VERSION "HNNBNNNYNNNNNNNNNNNNNNNNNNNNNNNNNNNNNNNNNN/4/%%%/4/'%**4NNN///"

NS_ :

BS_:

BU_: Allrad_Haldex AreaView_MQB BAP_Tester Bremse_ABS_MK100 Bremse_ESP_EPB_EBC460Vi Bremse_ESP_EPB_MK100 Bremse_ESP_MK100 Daempfer Gateway_MQB Lenkhilfe_EPS PDC PDC_PLA

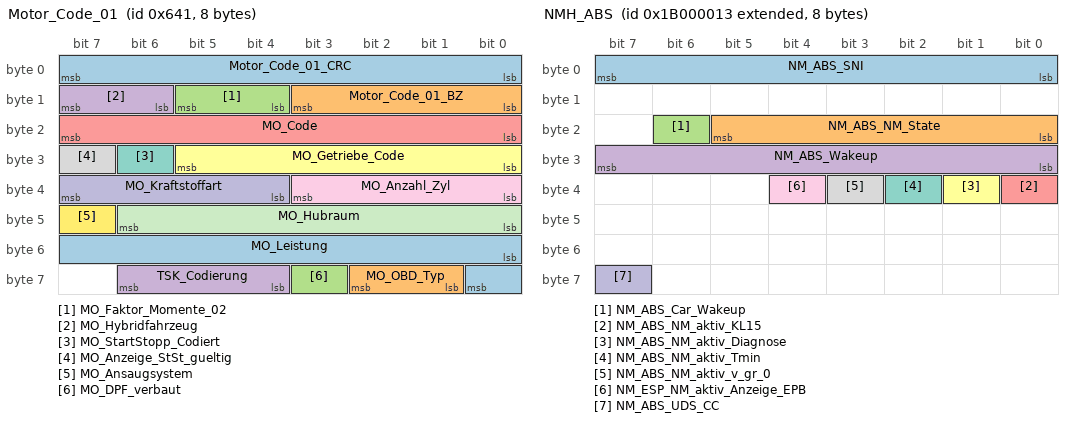
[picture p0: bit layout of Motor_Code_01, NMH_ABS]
BO_ 1601 Motor_Code_01: 8 Gateway_MQB
 SG_ Motor_Code_01_CRC : 0|8@1+ (1,0) [0|255] ""  Bremse_ABS_MK100,Bremse_ESP_EPB_EBC460Vi,Bremse_ESP_EPB_MK100,Bremse_ESP_MK100,Lenkhilfe_EPS
 SG_ Motor_Code_01_BZ : 8|4@1+ (1,0) [0|15] ""  Bremse_ABS_MK100,Bremse_ESP_EPB_EBC460Vi,Bremse_ESP_EPB_MK100,Bremse_ESP_MK100,Lenkhilfe_EPS
 SG_ MO_Faktor_Momente_02 : 12|2@1+ (1,0) [1|3] "Unit_NewtoMeter"  Allrad_Haldex,Bremse_ABS_MK100,Bremse_ESP_EPB_EBC460Vi,Bremse_ESP_EPB_MK100,Bremse_ESP_MK100,Lenkhilfe_EPS
 SG_ MO_Hybridfahrzeug : 14|2@1+ (1.0,0.0) [0.0|3] ""  Bremse_ESP_EPB_EBC460Vi,Bremse_ESP_EPB_MK100,Lenkhilfe_EPS
 SG_ MO_Code : 16|8@1+ (1,0) [0|255] ""  Vector__XXX
 SG_ MO_Getriebe_Code : 24|6@1+ (1.0,0.0) [0.0|63] ""  Bremse_ABS_MK100,Bremse_ESP_EPB_EBC460Vi,Bremse_ESP_EPB_MK100,Bremse_ESP_MK100
 SG_ MO_StartStopp_Codiert : 30|1@1+ (1.0,0.0) [0.0|1] ""  Lenkhilfe_EPS
 SG_ MO_Anzeige_StSt_gueltig : 31|1@1+ (1.0,0.0) [0.0|1] ""  Vector__XXX
 SG_ MO_Anzahl_Zyl : 32|4@1+ (1.0,0.0) [0.0|15] ""  Bremse_ESP_EPB_EBC460Vi,Bremse_ESP_EPB_MK100,Bremse_ESP_MK100
 SG_ MO_Kraftstoffart : 36|4@1+ (1.0,0.0) [0.0|15] ""  Allrad_Haldex,Bremse_ESP_EPB_EBC460Vi,Bremse_ESP_EPB_MK100,Bremse_ESP_MK100
 SG_ MO_Hubraum : 40|7@1+ (0.1,0) [0.0|12.7] "Unit_Liter"  Bremse_ESP_EPB_EBC460Vi,Bremse_ESP_EPB_MK100
 SG_ MO_Ansaugsystem : 47|1@1+ (1.0,0.0) [0.0|1] ""  Bremse_ESP_EPB_EBC460Vi,Bremse_ESP_EPB_MK100,Bremse_ESP_MK100
 SG_ MO_Leistung : 48|9@1+ (1,0) [0|511] "Unit_KiloWatt"  Allrad_Haldex,Bremse_ESP_EPB_EBC460Vi,Bremse_ESP_EPB_MK100
 SG_ MO_OBD_Typ : 57|2@1+ (1.0,0.0) [0.0|3] ""  Bremse_ESP_EPB_MK100
 SG_ MO_DPF_verbaut : 59|1@1+ (1.0,0.0) [0.0|1] ""  Vector__XXX
 SG_ TSK_Codierung : 60|3@1+ (1.0,0.0) [0.0|7] ""  Bremse_ESP_EPB_EBC460Vi,Bremse_ESP_EPB_MK100,Bremse_ESP_MK100

BO_ 2600468499 NMH_ABS: 8 Bremse_ABS_MK100
 SG_ NM_ABS_SNI : 0|8@1+ (1.0,0.0) [0.0|255] ""  Vector__XXX
 SG_ NM_ABS_NM_State : 16|6@1+ (1.0,0.0) [0.0|63] ""  AreaView_MQB,Bremse_ABS_MK100,Bremse_ESP_EPB_EBC460Vi,Bremse_ESP_EPB_MK100,Bremse_ESP_MK100,Lenkhilfe_EPS
 SG_ NM_ABS_Car_Wakeup : 22|1@1+ (1.0,0.0) [0.0|1] ""  Gateway_MQB
 SG_ NM_ABS_Wakeup : 24|8@1+ (1.0,0.0) [0.0|255] ""  Vector__XXX
 SG_ NM_ABS_NM_aktiv_KL15 : 32|1@1+ (1.0,0.0) [0.0|1] ""  Vector__XXX
 SG_ NM_ABS_NM_aktiv_Diagnose : 33|1@1+ (1.0,0.0) [0.0|1] ""  Vector__XXX
 SG_ NM_ABS_NM_aktiv_Tmin : 34|1@1+ (1.0,0.0) [0.0|1] ""  Vector__XXX
 SG_ NM_ABS_NM_aktiv_v_gr_0 : 35|1@1+ (1.0,0.0) [0.0|1] ""  Vector__XXX
 SG_ NM_ESP_NM_aktiv_Anzeige_EPB : 36|1@1+ (1.0,0.0) [0.0|1] ""  Vector__XXX
 SG_ NM_ABS_UDS_CC : 63|1@1+ (1.0,0.0) [0.0|1] ""  Vector__XXX

BO_ 2600468496 NMH_Gateway: 8 Gateway_MQB
 SG_ NM_Gateway_SNI : 0|8@1+ (1.0,0.0) [0.0|255] ""  Vector__XXX
 SG_ NM_Gateway_NM_State : 16|6@1+ (1.0,0.0) [0.0|63] ""  AreaView_MQB,Bremse_ABS_MK100,Bremse_ESP_EPB_EBC460Vi,Bremse_ESP_EPB_MK100,Bremse_ESP_MK100,Lenkhilfe_EPS
 SG_ NM_Gateway_Car_Wakeup : 22|1@1+ (1.0,0.0) [0.0|1] ""  Vector__XXX
 SG_ NM_Gateway_Wakeup : 24|8@1+ (1.0,0.0) [0.0|255] ""  Vector__XXX
 SG_ NM_Gateway_NM_aktiv_KL15 : 32|1@1+ (1.0,0.0) [0.0|1] ""  Vector__XXX
 SG_ NM_Gateway_NM_aktiv_Diagnose : 33|1@1+ (1.0,0.0) [0.0|1] ""  Vector__XXX
 SG_ NM_Gateway_NM_aktiv_Tmin : 34|1@1+ (1.0,0.0) [0.0|1] ""  Vector__XXX
 SG_ NM_Gateway_ACAN_Aktivitaet : 35|1@1+ (1.0,0.0) [0.0|1] ""  Vector__XXX
 SG_ NM_Gateway_FCAN_Aktivitaet : 36|1@1+ (1.0,0.0) [0.0|1] ""  Vector__XXX
 SG_ NM_Gateway_KCAN_Aktivitaet : 37|1@1+ (1.0,0.0) [0.0|1] ""  Vector__XXX
 SG_ NM_Gateway_ICAN_Aktivitaet : 38|1@1+ (1.0,0.0) [0.0|1] ""  Vector__XXX
 SG_ NM_Gateway_DiagCAN_Aktivitaet : 39|1@1+ (1.0,0.0) [0.0|1] ""  Vector__XXX
 SG_ NM_Gateway_ECAN_Aktivitaet : 40|1@1+ (1.0,0.0) [0.0|1] ""  Vector__XXX
 SG_ NM_Gateway_EnergieLIN_Aktivitaet : 41|1@1+ (1.0,0.0) [0.0|1] ""  Vector__XXX
 SG_ NM_Gateway_Bedien_LIN_Aktivitaet : 42|1@1+ (1.0,0.0) [0.0|1] ""  Vector__XXX
 SG_ NM_Gateway_EM_Aktivitaet : 43|1@1+ (1.0,0.0) [0.0|1] ""  Vector__XXX
 SG_ NM_Gateway_KS_Aktivitaet : 44|1@1+ (1.0,0.0) [0.0|1] ""  Vector__XXX
 SG_ NM_Gateway_HVEM_aktiv : 45|1@1+ (1.0,0.0) [0.0|1] ""  Vector__XXX
 SG_ NM_Gateway_NL_EM : 48|1@1+ (1.0,0.0) [0.0|1] ""  Vector__XXX
 SG_ NM_Gateway_NL_Shutdown : 49|1@1+ (1.0,0.0) [0.0|1] ""  Vector__XXX
 SG_ NM_Gateway_NL_Spg_Messung : 50|1@1+ (1.0,0.0) [0.0|1] ""  Vector__XXX
 SG_ NM_Gateway_NL_Wakeup_Monitor : 51|1@1+ (1.0,0.0) [0.0|1] ""  Vector__XXX
 SG_ NM_Gateway_UDS_CC : 63|1@1+ (1.0,0.0) [0.0|1] ""  Vector__XXX

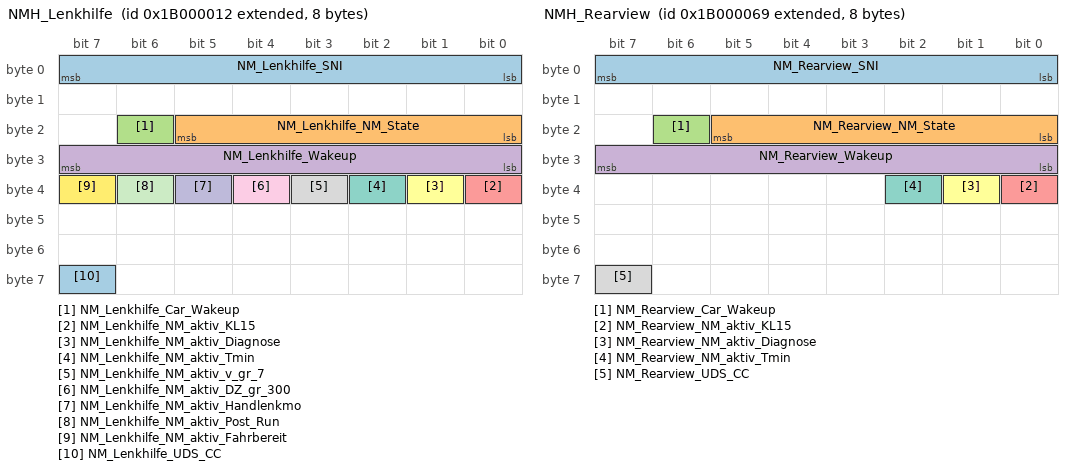
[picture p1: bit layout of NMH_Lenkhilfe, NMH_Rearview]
BO_ 2600468498 NMH_Lenkhilfe: 8 Lenkhilfe_EPS
 SG_ NM_Lenkhilfe_SNI : 0|8@1+ (1.0,0.0) [0.0|255] ""  Vector__XXX
 SG_ NM_Lenkhilfe_NM_State : 16|6@1+ (1.0,0.0) [0.0|63] ""  AreaView_MQB,Bremse_ABS_MK100,Bremse_ESP_EPB_EBC460Vi,Bremse_ESP_EPB_MK100,Bremse_ESP_MK100,Lenkhilfe_EPS
 SG_ NM_Lenkhilfe_Car_Wakeup : 22|1@1+ (1.0,0.0) [0.0|1] ""  Gateway_MQB
 SG_ NM_Lenkhilfe_Wakeup : 24|8@1+ (1.0,0.0) [0.0|255] ""  Vector__XXX
 SG_ NM_Lenkhilfe_NM_aktiv_KL15 : 32|1@1+ (1.0,0.0) [0.0|1] ""  Vector__XXX
 SG_ NM_Lenkhilfe_NM_aktiv_Diagnose : 33|1@1+ (1.0,0.0) [0.0|1] ""  Vector__XXX
 SG_ NM_Lenkhilfe_NM_aktiv_Tmin : 34|1@1+ (1.0,0.0) [0.0|1] ""  Vector__XXX
 SG_ NM_Lenkhilfe_NM_aktiv_v_gr_7 : 35|1@1+ (1.0,0.0) [0.0|1] ""  Vector__XXX
 SG_ NM_Lenkhilfe_NM_aktiv_DZ_gr_300 : 36|1@1+ (1.0,0.0) [0.0|1] ""  Vector__XXX
 SG_ NM_Lenkhilfe_NM_aktiv_Handlenkmo : 37|1@1+ (1.0,0.0) [0.0|1] ""  Vector__XXX
 SG_ NM_Lenkhilfe_NM_aktiv_Post_Run : 38|1@1+ (1.0,0.0) [0.0|1] ""  Vector__XXX
 SG_ NM_Lenkhilfe_NM_aktiv_Fahrbereit : 39|1@1+ (1.0,0.0) [0.0|1] ""  Vector__XXX
 SG_ NM_Lenkhilfe_UDS_CC : 63|1@1+ (1.0,0.0) [0.0|1] ""  Vector__XXX

BO_ 2600468585 NMH_Rearview: 8 AreaView_MQB
 SG_ NM_Rearview_SNI : 0|8@1+ (1.0,0.0) [0.0|255] ""  Vector__XXX
 SG_ NM_Rearview_NM_State : 16|6@1+ (1.0,0.0) [0.0|63] ""  AreaView_MQB,Bremse_ABS_MK100,Bremse_ESP_EPB_EBC460Vi,Bremse_ESP_EPB_MK100,Bremse_ESP_MK100,Lenkhilfe_EPS
 SG_ NM_Rearview_Car_Wakeup : 22|1@1+ (1.0,0.0) [0.0|1] ""  Vector__XXX
 SG_ NM_Rearview_Wakeup : 24|8@1+ (1.0,0.0) [0.0|255] ""  Vector__XXX
 SG_ NM_Rearview_NM_aktiv_KL15 : 32|1@1+ (1.0,0.0) [0.0|1] ""  Vector__XXX
 SG_ NM_Rearview_NM_aktiv_Diagnose : 33|1@1+ (1.0,0.0) [0.0|1] ""  Vector__XXX
 SG_ NM_Rearview_NM_aktiv_Tmin : 34|1@1+ (1.0,0.0) [0.0|1] ""  Vector__XXX
 SG_ NM_Rearview_UDS_CC : 63|1@1+ (1.0,0.0) [0.0|1] ""  Vector__XXX

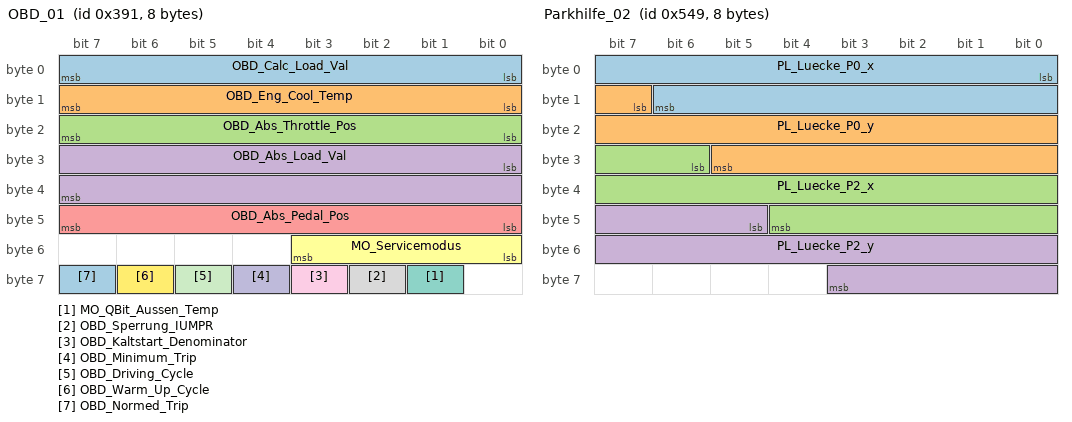
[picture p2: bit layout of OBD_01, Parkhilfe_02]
BO_ 913 OBD_01: 8 Gateway_MQB
 SG_ OBD_Calc_Load_Val : 0|8@1+ (0.39215686274509803,0) [0E-17|99.99999999999999765] "Unit_PerCent"  Bremse_ESP_EPB_MK100
 SG_ OBD_Eng_Cool_Temp : 8|8@1+ (1,-40) [-40|215] "Unit_DegreCelsi"  Bremse_ESP_EPB_MK100
 SG_ OBD_Abs_Throttle_Pos : 16|8@1+ (0.39215686274509803,0) [0E-17|99.99999999999999765] "Unit_PerCent"  Bremse_ESP_EPB_MK100
 SG_ OBD_Abs_Load_Val : 24|16@1+ (0.39215686274509803,0) [0E-17|25699.99999999999939605] "Unit_PerCent"  Bremse_ESP_EPB_MK100
 SG_ OBD_Abs_Pedal_Pos : 40|8@1+ (0.39215686274509803,0) [0E-17|99.99999999999999765] "Unit_PerCent"  Bremse_ESP_EPB_MK100
 SG_ MO_Servicemodus : 48|4@1+ (1.0,0.0) [0.0|15] ""  Vector__XXX
 SG_ MO_QBit_Aussen_Temp : 57|1@1+ (1.0,0.0) [0.0|1] ""  Vector__XXX
 SG_ OBD_Sperrung_IUMPR : 58|1@1+ (1.0,0.0) [0.0|1] ""  Bremse_ESP_EPB_MK100
 SG_ OBD_Kaltstart_Denominator : 59|1@1+ (1.0,0.0) [0.0|1] ""  Bremse_ESP_EPB_MK100
 SG_ OBD_Minimum_Trip : 60|1@1+ (1.0,0.0) [0.0|1] ""  Bremse_ESP_EPB_MK100
 SG_ OBD_Driving_Cycle : 61|1@1+ (1.0,0.0) [0.0|1] ""  Bremse_ESP_EPB_MK100
 SG_ OBD_Warm_Up_Cycle : 62|1@1+ (1.0,0.0) [0.0|1] ""  Bremse_ESP_EPB_MK100
 SG_ OBD_Normed_Trip : 63|1@1+ (1.0,0.0) [0.0|1] ""  Bremse_ESP_EPB_MK100

BO_ 2549875219 OBDC_ABS_Req: 8 Vector__XXX
 SG_ OBDC_ABS_Req_Data : 0|64@1+ (1.0,0.0) [0.0|18446744073709551615] ""  Bremse_ABS_MK100,Bremse_ESP_EPB_EBC460Vi,Bremse_ESP_EPB_MK100,Bremse_ESP_MK100

BO_ 2550006291 OBDC_ABS_Resp: 8 Bremse_ABS_MK100
 SG_ OBDC_ABS_Resp_Data : 0|64@1+ (1.0,0.0) [0.0|18446744073709551615] ""  Vector__XXX

BO_ 2549875215 OBDC_Allrad_Req: 8 Vector__XXX
 SG_ OBDC_Allrad_Req_Data : 0|64@1+ (1.0,0.0) [0.0|18446744073709551615] ""  Allrad_Haldex

BO_ 2550006287 OBDC_Allrad_Resp: 8 Allrad_Haldex
 SG_ OBDC_Allrad_Resp_Data : 0|64@1+ (1.0,0.0) [0.0|18446744073709551615] ""  Vector__XXX

BO_ 2549875314 OBDC_Daempfer_Req: 8 Vector__XXX
 SG_ OBDC_Daempfer_Req_Data : 0|64@1+ (1.0,0.0) [0.0|18446744073709551615] ""  Daempfer

BO_ 2550006386 OBDC_Daempfer_Resp: 8 Daempfer
 SG_ OBDC_Daempfer_Resp_Data : 0|64@1+ (1.0,0.0) [0.0|18446744073709551615] ""  Vector__XXX

BO_ 2549875210 OBDC_EPH_Req: 8 Vector__XXX
 SG_ OBDC_EPH_Req_Data : 0|64@1+ (1.0,0.0) [0.0|18446744073709551615] ""  PDC,PDC_PLA

BO_ 2550006282 OBDC_EPH_Resp: 8 PDC
 SG_ OBDC_EPH_Resp_Data : 0|64@1+ (1.0,0.0) [0.0|18446744073709551615] ""  Vector__XXX

BO_ 2549875218 OBDC_Lenkhilfe_Req: 8 Vector__XXX
 SG_ OBDC_Lenkhilfe_Req_Data : 0|64@1+ (1.0,0.0) [0.0|18446744073709551615] ""  Lenkhilfe_EPS

BO_ 2550006290 OBDC_Lenkhilfe_Resp: 8 Lenkhilfe_EPS
 SG_ OBDC_Lenkhilfe_Resp_Data : 0|64@1+ (1.0,0.0) [0.0|18446744073709551615] ""  Vector__XXX

BO_ 2549875305 OBDC_Rearview_Req: 8 Vector__XXX
 SG_ OBDC_Rearview_Req_Data : 0|64@1+ (1.0,0.0) [0.0|18446744073709551615] ""  AreaView_MQB

BO_ 2550006377 OBDC_Rearview_Resp: 8 AreaView_MQB
 SG_ OBDC_Rearview_Resp_Data : 0|64@1+ (1.0,0.0) [0.0|18446744073709551615] ""  Vector__XXX

BO_ 1175 Parkhilfe_01: 8 PDC
 SG_ PH_Visualisierung : 0|3@1+ (1.0,0.0) [0.0|7] ""  AreaView_MQB,Gateway_MQB
 SG_ PDC_Tonausgabe_Front : 4|4@1+ (1.0,0.0) [0.0|15] ""  Gateway_MQB
 SG_ PDC_Tonausgabe_Heck : 8|4@1+ (1.0,0.0) [0.0|15] ""  Gateway_MQB
 SG_ PH_nachtr_Stopp_Anf : 12|1@1+ (1.0,0.0) [0.0|1] ""  Gateway_MQB
 SG_ PH_Abschaltursache : 13|3@1+ (1.0,0.0) [0.0|7] ""  Gateway_MQB
 SG_ PH_Opt_Anzeige_V_ein : 16|1@1+ (1.0,0.0) [0.0|1] ""  Gateway_MQB
 SG_ PH_Opt_Anzeige_H_ein : 17|1@1+ (1.0,0.0) [0.0|1] ""  Gateway_MQB
 SG_ PH_Opt_Anz_V_Hindernis : 18|1@1+ (1.0,0.0) [0.0|1] ""  Gateway_MQB
 SG_ PH_Opt_Anz_H_Hindernis : 19|1@1+ (1.0,0.0) [0.0|1] ""  Gateway_MQB
 SG_ PH_Tongeber_V_aktiv : 20|1@1+ (1.0,0.0) [0.0|1] ""  Gateway_MQB
 SG_ PH_Tongeber_H_aktiv : 21|1@1+ (1.0,0.0) [0.0|1] ""  Gateway_MQB
 SG_ PH_Tongeber_mute : 22|1@1+ (1.0,0.0) [0.0|1] ""  Gateway_MQB
 SG_ PH_Anf_Audioabsenkung : 23|1@1+ (1.0,0.0) [0.0|1] ""  Gateway_MQB
 SG_ PH_Tongeber_H_verfuegbar : 24|1@1+ (1.0,0.0) [0.0|1] ""  Gateway_MQB
 SG_ PLA_Anf_Aufschaltung_RVC : 25|1@1+ (1.0,0.0) [0.0|1] ""  AreaView_MQB,Gateway_MQB
 SG_ PH_Taster : 28|2@1+ (1.0,0.0) [0.0|3] ""  AreaView_MQB,Gateway_MQB
 SG_ PH_Anf_Verdeck : 30|2@1+ (1.0,0.0) [0.0|3] ""  Gateway_MQB
 SG_ PH_Frequenz_hinten : 32|4@1+ (1,0) [0|15] ""  Gateway_MQB
 SG_ PH_Lautstaerke_hinten : 36|4@1+ (1,0) [0|15] ""  Gateway_MQB
 SG_ PH_Frequenz_vorn : 40|4@1+ (1,0) [0|15] ""  Gateway_MQB
 SG_ PH_Lautstaerke_vorn : 44|4@1+ (1,0) [0|15] ""  Gateway_MQB
 SG_ PH_StartStopp_Info : 49|2@1+ (1.0,0.0) [0.0|3] ""  Gateway_MQB
 SG_ PH_Stoermeldung : 52|4@1+ (1.0,0.0) [0.0|15] ""  Gateway_MQB
 SG_ PH_defekt : 56|1@1+ (1.0,0.0) [0.0|1] ""  Gateway_MQB
 SG_ PH_gestoert : 57|1@1+ (1.0,0.0) [0.0|1] ""  Gateway_MQB
 SG_ PH_Systemzustand : 58|3@1+ (1.0,0.0) [0.0|7] ""  AreaView_MQB,Gateway_MQB
 SG_ PH_Display_Kundenwunsch : 61|2@1+ (1.0,0.0) [0.0|3] ""  Gateway_MQB

BO_ 1353 Parkhilfe_02: 8 PDC_PLA
 SG_ PL_Luecke_P0_x : 0|15@1+ (2,-32767) [-32767|32767] "Unit_Centimeter"  AreaView_MQB,Gateway_MQB
 SG_ PL_Luecke_P0_y : 15|15@1+ (2,-32767) [-32767|32767] "Unit_Centimeter"  AreaView_MQB,Gateway_MQB
 SG_ PL_Luecke_P2_x : 30|15@1+ (2,-32767) [-32767|32767] "Unit_Centimeter"  AreaView_MQB,Gateway_MQB
 SG_ PL_Luecke_P2_y : 45|15@1+ (2,-32767) [-32767|32767] "Unit_Centimeter"  AreaView_MQB,Gateway_MQB

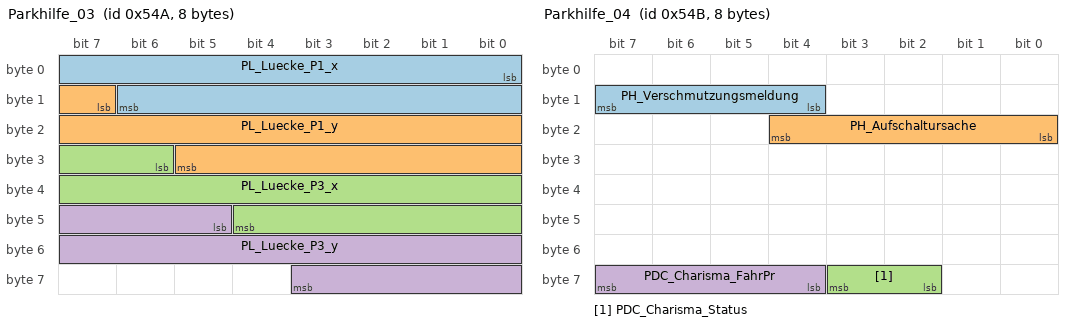
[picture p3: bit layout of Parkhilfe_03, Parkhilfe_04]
BO_ 1354 Parkhilfe_03: 8 PDC_PLA
 SG_ PL_Luecke_P1_x : 0|15@1+ (2,-32767) [-32767|32767] "Unit_Centimeter"  AreaView_MQB,Gateway_MQB
 SG_ PL_Luecke_P1_y : 15|15@1+ (2,-32767) [-32767|32767] "Unit_Centimeter"  AreaView_MQB,Gateway_MQB
 SG_ PL_Luecke_P3_x : 30|15@1+ (2,-32767) [-32767|32767] "Unit_Centimeter"  AreaView_MQB,Gateway_MQB
 SG_ PL_Luecke_P3_y : 45|15@1+ (2,-32767) [-32767|32767] "Unit_Centimeter"  AreaView_MQB,Gateway_MQB

BO_ 1355 Parkhilfe_04: 8 PDC
 SG_ PH_Verschmutzungsmeldung : 12|4@1+ (1.0,0.0) [0.0|15] ""  Vector__XXX
 SG_ PH_Aufschaltursache : 16|5@1+ (1.0,0.0) [0.0|31] ""  Vector__XXX
 SG_ PDC_Charisma_Status : 58|2@1+ (1.0,0.0) [0.0|3] ""  Gateway_MQB
 SG_ PDC_Charisma_FahrPr : 60|4@1+ (1.0,0.0) [0.0|15] ""  Gateway_MQB

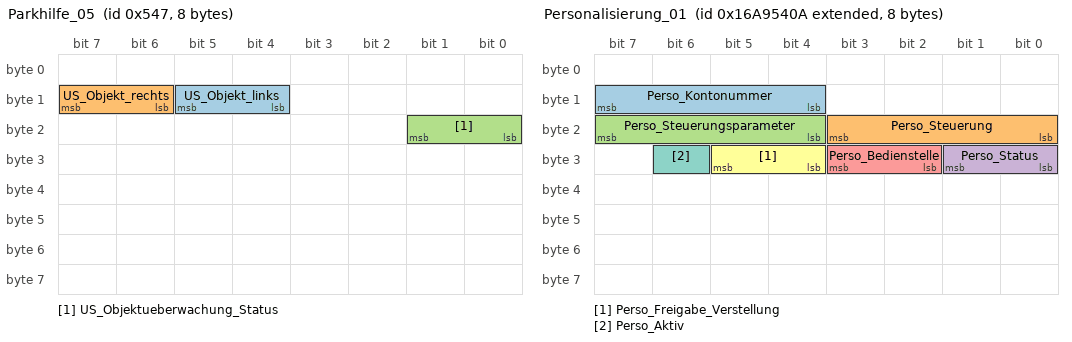
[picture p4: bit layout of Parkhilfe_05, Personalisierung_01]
BO_ 1351 Parkhilfe_05: 8 PDC_PLA
 SG_ US_Objekt_links : 12|2@1+ (1.0,0.0) [0.0|3] ""  Gateway_MQB
 SG_ US_Objekt_rechts : 14|2@1+ (1.0,0.0) [0.0|3] ""  Gateway_MQB
 SG_ US_Objektueberwachung_Status : 16|2@1+ (1.0,0.0) [0.0|3] ""  Gateway_MQB

BO_ 2527679498 Personalisierung_01: 8 Gateway_MQB
 SG_ Perso_Kontonummer : 12|4@1+ (1.0,0.0) [0.0|15] ""  PDC,PDC_PLA
 SG_ Perso_Steuerung : 16|4@1+ (1.0,0.0) [0.0|15] ""  PDC,PDC_PLA
 SG_ Perso_Steuerungsparameter : 20|4@1+ (1.0,0.0) [0.0|15] ""  PDC,PDC_PLA
 SG_ Perso_Status : 24|2@1+ (1.0,0.0) [0.0|3] ""  PDC,PDC_PLA
 SG_ Perso_Bedienstelle : 26|2@1+ (1.0,0.0) [0.0|3] ""  Vector__XXX
 SG_ Perso_Freigabe_Verstellung : 28|2@1+ (1.0,0.0) [0.0|3] ""  Vector__XXX
 SG_ Perso_Aktiv : 30|1@1+ (1.0,0.0) [0.0|1] ""  Vector__XXX

BO_ 304 PLA_01: 8 PDC
 SG_ PLA_01_CRC : 0|8@1+ (1,0) [0|255] ""  Bremse_ESP_EPB_EBC460Vi,Bremse_ESP_EPB_MK100,Bremse_ESP_MK100,Lenkhilfe_EPS
 SG_ PLA_01_BZ : 8|4@1+ (1,0) [0|15] ""  Bremse_ESP_EPB_EBC460Vi,Bremse_ESP_EPB_MK100,Bremse_ESP_MK100,Lenkhilfe_EPS
 SG_ PLA_Status_PLA_ESP : 12|4@1+ (1.0,0.0) [0.0|15] ""  Bremse_ESP_EPB_EBC460Vi,Bremse_ESP_EPB_MK100,Bremse_ESP_MK100
 SG_ PLA_LW_Soll : 16|13@1+ (0.1,0) [0.0|819.1] "Unit_DegreOfArc"  Lenkhilfe_EPS
 SG_ PLA_VZ_LW_Soll : 31|1@1+ (1.0,0.0) [0.0|1] ""  Lenkhilfe_EPS
 SG_ PLA_Status_PLA_EPS : 32|4@1+ (1.0,0.0) [0.0|15] ""  Gateway_MQB,Lenkhilfe_EPS
 SG_ PLA_Bremsmoment m0  : 36|13@1+ (4,0) [0|32760] "Unit_NewtoMeter"  Bremse_ESP_EPB_EBC460Vi,Bremse_ESP_EPB_MK100,Bremse_ESP_MK100
 SG_ PLA_Bremsverzoegerung m1  : 36|7@1+ (0.1,0) [0.0|12.0] "Unit_MeterPerSeconSquar"  Bremse_ESP_EPB_EBC460Vi,Bremse_ESP_EPB_MK100,Bremse_ESP_MK100
 SG_ PLA_Anf_Bremsverzoegerung m1  : 43|1@1+ (1.0,0.0) [0.0|1] ""  Bremse_ESP_EPB_EBC460Vi,Bremse_ESP_EPB_MK100,Bremse_ESP_MK100
 SG_ PLA_BremsMom_Verzoeg M  : 50|1@1+ (1.0,0.0) [0.0|1] ""  Bremse_ESP_EPB_EBC460Vi,Bremse_ESP_EPB_MK100,Bremse_ESP_MK100
 SG_ PLA_Anhalten : 51|1@1+ (1.0,0.0) [0.0|1] ""  Bremse_ESP_EPB_EBC460Vi,Bremse_ESP_EPB_MK100,Bremse_ESP_MK100
 SG_ PLA_Anhalteweg : 52|11@1+ (0.01,0) [0.01|20.45] "Unit_Meter"  Bremse_ESP_EPB_EBC460Vi,Bremse_ESP_EPB_MK100,Bremse_ESP_MK100
 SG_ PLA_01_Signal_red_cyclic : 63|1@1+ (1.0,0.0) [0.0|1] ""  Vector__XXX

BO_ 1174 PLA_Status_01: 8 PDC_PLA
 SG_ PLS_Anf_Anz : 12|1@1+ (1.0,0.0) [0.0|1] ""  Gateway_MQB
 SG_ PLS_Kurze_Luecke : 13|1@1+ (1.0,0.0) [0.0|1] ""  Gateway_MQB
 SG_ PLS_Laengs_Querluecke : 14|1@1+ (1.0,0.0) [0.0|1] ""  Gateway_MQB
 SG_ PLS_Anf_Anz_Schwellpfeil : 15|1@1+ (1.0,0.0) [0.0|1] ""  Gateway_MQB
 SG_ PLS_Fahrtrichtg_Mehrzg : 16|1@1+ (1.0,0.0) [0.0|1] ""  Gateway_MQB
 SG_ PLS_Bremssymbol : 17|1@1+ (1.0,0.0) [0.0|1] ""  Gateway_MQB
 SG_ PLS_PL_Exist : 18|1@1+ (1.0,0.0) [0.0|1] ""  Gateway_MQB
 SG_ PLS_Standby : 19|1@1+ (1.0,0.0) [0.0|1] ""  Gateway_MQB
 SG_ PLS_Mehrzg_Aktiv : 20|1@1+ (1.0,0.0) [0.0|1] ""  Gateway_MQB
 SG_ PLS_Pos_OK : 21|1@1+ (1.0,0.0) [0.0|1] ""  Gateway_MQB
 SG_ PLS_PL_Seite : 22|1@1+ (1.0,0.0) [0.0|1] ""  Gateway_MQB
 SG_ PLS_Lenk_Aktiv_Hinweis : 23|1@1+ (1.0,0.0) [0.0|1] ""  Gateway_MQB
 SG_ PLS_Texte : 24|7@1+ (1.0,0.0) [0.0|127] ""  Gateway_MQB
 SG_ PLS_Schwellpfeil_rel : 32|4@1+ (1.0,0.0) [0.0|15] ""  Gateway_MQB
 SG_ PLS_Schwellpfeil_abs : 37|2@1+ (1.0,0.0) [0.0|3] ""  Gateway_MQB
 SG_ PLS_Ausparken_Aktiv : 40|1@1+ (1.0,0.0) [0.0|1] ""  Gateway_MQB
 SG_ PLS_Bremsleuchte : 41|1@1+ (1.0,0.0) [0.0|1] ""  Gateway_MQB
 SG_ PLS_Akustik : 42|2@1+ (1.0,0.0) [0.0|3] ""  Gateway_MQB

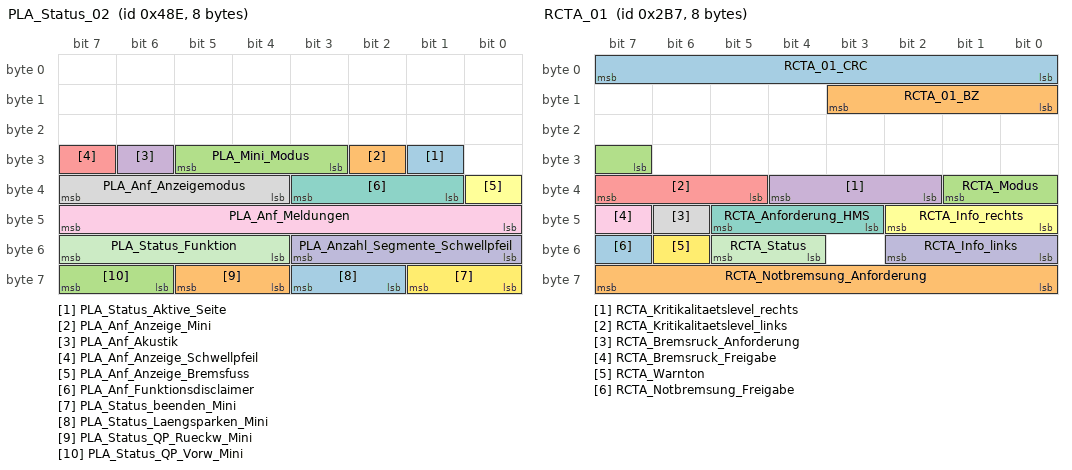
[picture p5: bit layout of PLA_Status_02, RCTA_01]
BO_ 1166 PLA_Status_02: 8 PDC
 SG_ PLA_Status_Aktive_Seite : 25|1@1+ (1.0,0.0) [0.0|1] ""  Gateway_MQB
 SG_ PLA_Anf_Anzeige_Mini : 26|1@1+ (1.0,0.0) [0.0|1] ""  Gateway_MQB
 SG_ PLA_Mini_Modus : 27|3@1+ (1.0,0.0) [0.0|7] ""  Gateway_MQB
 SG_ PLA_Anf_Akustik : 30|1@1+ (1.0,0.0) [0.0|1] ""  Gateway_MQB
 SG_ PLA_Anf_Anzeige_Schwellpfeil : 31|1@1+ (1.0,0.0) [0.0|1] ""  Gateway_MQB
 SG_ PLA_Anf_Anzeige_Bremsfuss : 32|1@1+ (1.0,0.0) [0.0|1] ""  Gateway_MQB
 SG_ PLA_Anf_Funktionsdisclaimer : 33|3@1+ (1.0,0.0) [0.0|7] ""  Gateway_MQB
 SG_ PLA_Anf_Anzeigemodus : 36|4@1+ (1.0,0.0) [0.0|15] ""  Gateway_MQB
 SG_ PLA_Anf_Meldungen : 40|8@1+ (1.0,0.0) [0.0|255] ""  Gateway_MQB
 SG_ PLA_Anzahl_Segmente_Schwellpfeil : 48|4@1+ (1,0) [0|15] "Unit_None"  Gateway_MQB
 SG_ PLA_Status_Funktion : 52|4@1+ (1.0,0.0) [0.0|15] ""  Gateway_MQB
 SG_ PLA_Status_beenden_Mini : 56|2@1+ (1.0,0.0) [0.0|3] ""  Gateway_MQB
 SG_ PLA_Status_Laengsparken_Mini : 58|2@1+ (1.0,0.0) [0.0|3] ""  Gateway_MQB
 SG_ PLA_Status_QP_Rueckw_Mini : 60|2@1+ (1.0,0.0) [0.0|3] ""  Gateway_MQB
 SG_ PLA_Status_QP_Vorw_Mini : 62|2@1+ (1.0,0.0) [0.0|3] ""  Gateway_MQB

BO_ 695 RCTA_01: 8 Gateway_MQB
 SG_ RCTA_01_CRC : 0|8@1+ (1,0) [0|255] ""  Bremse_ESP_EPB_EBC460Vi,Bremse_ESP_EPB_MK100
 SG_ RCTA_01_BZ : 8|4@1+ (1,0) [0|15] ""  Bremse_ESP_EPB_EBC460Vi,Bremse_ESP_EPB_MK100
 SG_ RCTA_Modus : 31|3@1+ (1.0,0.0) [0.0|7] ""  Vector__XXX
 SG_ RCTA_Kritikalitaetslevel_rechts : 34|3@1+ (1.0,0.0) [0.0|7] ""  Vector__XXX
 SG_ RCTA_Kritikalitaetslevel_links : 37|3@1+ (1.0,0.0) [0.0|7] ""  Vector__XXX
 SG_ RCTA_Info_rechts : 40|3@1+ (1.0,0.0) [0.0|7] ""  PDC_PLA
 SG_ RCTA_Anforderung_HMS : 43|3@1+ (1.0,0.0) [0.0|7] ""  Vector__XXX
 SG_ RCTA_Bremsruck_Anforderung : 46|1@1+ (1.0,0.0) [0.0|1] ""  Bremse_ESP_EPB_EBC460Vi,Bremse_ESP_EPB_MK100
 SG_ RCTA_Bremsruck_Freigabe : 47|1@1+ (1.0,0.0) [0.0|1] ""  Bremse_ESP_EPB_EBC460Vi,Bremse_ESP_EPB_MK100
 SG_ RCTA_Info_links : 48|3@1+ (1.0,0.0) [0.0|7] ""  PDC_PLA
 SG_ RCTA_Status : 52|2@1+ (1.0,0.0) [0.0|3] ""  Bremse_ESP_EPB_EBC460Vi,Bremse_ESP_EPB_MK100,PDC,PDC_PLA
 SG_ RCTA_Warnton : 54|1@1+ (1.0,0.0) [0.0|1] ""  PDC,PDC_PLA
 SG_ RCTA_Notbremsung_Freigabe : 55|1@1+ (1.0,0.0) [0.0|1] ""  Bremse_ESP_EPB_EBC460Vi,Bremse_ESP_EPB_MK100
 SG_ RCTA_Notbremsung_Anforderung : 56|8@1+ (0.078,-19.812) [-19.734|0.000] "Unit_MeterPerSeconSquar"  Bremse_ESP_EPB_EBC460Vi,Bremse_ESP_EPB_MK100

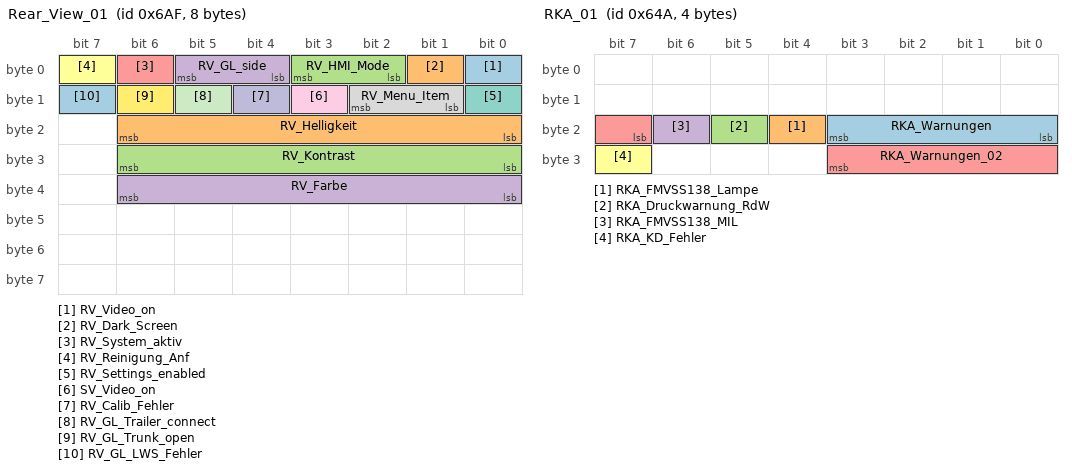
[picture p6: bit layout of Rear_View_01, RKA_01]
BO_ 1711 Rear_View_01: 8 AreaView_MQB
 SG_ RV_Video_on : 0|1@1+ (1.0,0.0) [0.0|1] ""  Gateway_MQB
 SG_ RV_Dark_Screen : 1|1@1+ (1.0,0.0) [0.0|1] ""  Gateway_MQB
 SG_ RV_HMI_Mode : 2|2@1+ (1.0,0.0) [0.0|3] ""  Gateway_MQB
 SG_ RV_GL_side : 4|2@1+ (1.0,0.0) [0.0|3] ""  Gateway_MQB
 SG_ RV_System_aktiv : 6|1@1+ (1.0,0.0) [0.0|1] ""  Gateway_MQB
 SG_ RV_Reinigung_Anf : 7|1@1+ (1.0,0.0) [0.0|1] ""  Gateway_MQB
 SG_ RV_Settings_enabled : 8|1@1+ (1.0,0.0) [0.0|1] ""  Gateway_MQB
 SG_ RV_Menu_Item : 9|2@1+ (1.0,0.0) [0.0|3] ""  Gateway_MQB
 SG_ SV_Video_on : 11|1@1+ (1.0,0.0) [0.0|1] ""  Gateway_MQB
 SG_ RV_Calib_Fehler : 12|1@1+ (1.0,0.0) [0.0|1] ""  Gateway_MQB
 SG_ RV_GL_Trailer_connect : 13|1@1+ (1.0,0.0) [0.0|1] ""  Gateway_MQB
 SG_ RV_GL_Trunk_open : 14|1@1+ (1.0,0.0) [0.0|1] ""  Gateway_MQB
 SG_ RV_GL_LWS_Fehler : 15|1@1+ (1.0,0.0) [0.0|1] ""  Gateway_MQB
 SG_ RV_Helligkeit : 16|7@1+ (1,0) [0|100] "Unit_PerCent"  Gateway_MQB
 SG_ RV_Kontrast : 24|7@1+ (1,0) [0|100] "Unit_PerCent"  Gateway_MQB
 SG_ RV_Farbe : 32|7@1+ (1,0) [0|100] "Unit_PerCent"  Gateway_MQB

BO_ 1610 RKA_01: 4 Bremse_ESP_EPB_EBC460Vi
 SG_ RKA_Warnungen : 16|4@1+ (1.0,0.0) [0.0|15] ""  Gateway_MQB
 SG_ RKA_FMVSS138_Lampe : 20|1@1+ (1.0,0.0) [0.0|1] ""  Gateway_MQB
 SG_ RKA_Druckwarnung_RdW : 21|1@1+ (1.0,0.0) [0.0|1] ""  Gateway_MQB
 SG_ RKA_FMVSS138_MIL : 22|1@1+ (1,0) [0|1] ""  Gateway_MQB
 SG_ RKA_Warnungen_02 : 23|5@1+ (1.0,0.0) [0.0|31] ""  Gateway_MQB
 SG_ RKA_KD_Fehler : 31|1@1+ (1.0,0.0) [0.0|1] ""  Gateway_MQB

BO_ 1710 Spiegel_01: 4 Gateway_MQB
 SG_ SP_FT_oben : 0|1@1+ (1.0,0.0) [0.0|1] ""  Vector__XXX
 SG_ SP_FT_unten : 1|1@1+ (1.0,0.0) [0.0|1] ""  Vector__XXX
 SG_ SP_FT_links : 2|1@1+ (1.0,0.0) [0.0|1] ""  Vector__XXX
 SG_ SP_FT_rechts : 3|1@1+ (1.0,0.0) [0.0|1] ""  Vector__XXX
 SG_ SP_BT_oben : 4|1@1+ (1.0,0.0) [0.0|1] ""  Vector__XXX
 SG_ SP_BT_unten : 5|1@1+ (1.0,0.0) [0.0|1] ""  Vector__XXX
 SG_ SP_BT_links : 6|1@1+ (1.0,0.0) [0.0|1] ""  Vector__XXX
 SG_ SP_BT_rechts : 7|1@1+ (1.0,0.0) [0.0|1] ""  Vector__XXX
 SG_ SP_abklappen : 8|1@1+ (1.0,0.0) [0.0|1] ""  AreaView_MQB
 SG_ SP_anklappen : 9|1@1+ (1.0,0.0) [0.0|1] ""  AreaView_MQB
 SG_ SP_normieren : 10|1@1+ (1.0,0.0) [0.0|1] ""  Vector__XXX
 SG_ SP_Spg_Verstellschalter_Fehler : 11|1@1+ (1.0,0.0) [0.0|1] ""  Vector__XXX
 SG_ SP_Hzg_Taster : 12|1@1+ (1.0,0.0) [0.0|1] ""  Vector__XXX
 SG_ SP_S_oben : 16|1@1+ (1.0,0.0) [0.0|1] ""  Vector__XXX
 SG_ SP_S_unten : 17|1@1+ (1.0,0.0) [0.0|1] ""  Vector__XXX
 SG_ SP_S_links : 18|1@1+ (1.0,0.0) [0.0|1] ""  Vector__XXX
 SG_ SP_S_rechts : 19|1@1+ (1.0,0.0) [0.0|1] ""  Vector__XXX
 SG_ SP_Auswahl_li : 20|1@1+ (1.0,0.0) [0.0|1] ""  Vector__XXX
 SG_ SP_Auswahl_re : 21|1@1+ (1.0,0.0) [0.0|1] ""  Vector__XXX
 SG_ SP_ARA_Status : 22|1@1+ (1.0,0.0) [0.0|1] ""  Vector__XXX
 SG_ SP_S_Klappen : 23|1@1+ (1.0,0.0) [0.0|1] ""  AreaView_MQB

BO_ 1413 Systeminfo_01: 8 Gateway_MQB
 SG_ SI_Sammel_SG_Fehler : 0|6@1+ (1,0) [0|60] ""  Vector__XXX
 SG_ SI_Diagnose_Aktiv : 7|1@1+ (1.0,0.0) [0.0|1] ""  Vector__XXX
 SG_ SI_QRS_Mode : 8|1@1+ (1.0,0.0) [0.0|1] ""  Vector__XXX
 SG_ SI_T_Mode : 9|1@1+ (1.0,0.0) [0.0|1] ""  Vector__XXX
 SG_ SI_NWDF : 10|1@1+ (1.0,0.0) [0.0|1] ""  Allrad_Haldex,AreaView_MQB,Bremse_ESP_EPB_EBC460Vi,Daempfer,Lenkhilfe_EPS,PDC,PDC_PLA
 SG_ SI_NWDF_gueltig : 11|1@1+ (1.0,0.0) [0.0|1] ""  Allrad_Haldex,AreaView_MQB,Bremse_ESP_EPB_EBC460Vi,Daempfer,Lenkhilfe_EPS,PDC,PDC_PLA
 SG_ SI_Sammelfehler : 12|1@1+ (1.0,0.0) [0.0|1] ""  Vector__XXX
 SG_ GW_KD_Fehler : 13|1@1+ (1.0,0.0) [0.0|1] ""  Vector__XXX
 SG_ SI_T_Schutz : 14|1@1+ (1.0,0.0) [0.0|1] ""  Daempfer,PDC,PDC_PLA
 SG_ SI_BUS_01 : 16|1@1+ (1.0,0.0) [0.0|1] ""  Vector__XXX
 SG_ SI_BUS_02 : 17|1@1+ (1.0,0.0) [0.0|1] ""  Vector__XXX
 SG_ SI_BUS_03 : 18|1@1+ (1.0,0.0) [0.0|1] ""  Vector__XXX
 SG_ SI_BUS_04 : 19|1@1+ (1.0,0.0) [0.0|1] ""  Vector__XXX
 SG_ SI_BUS_05 : 20|1@1+ (1.0,0.0) [0.0|1] ""  Vector__XXX
 SG_ SI_BUS_06 : 21|1@1+ (1.0,0.0) [0.0|1] ""  Vector__XXX
 SG_ SI_BUS_07 : 22|1@1+ (1.0,0.0) [0.0|1] ""  Vector__XXX
 SG_ SI_BUS_08 : 23|1@1+ (1.0,0.0) [0.0|1] ""  Vector__XXX
 SG_ SI_BUS_09 : 24|1@1+ (1.0,0.0) [0.0|1] ""  Vector__XXX
 SG_ SI_BUS_10 : 25|1@1+ (1.0,0.0) [0.0|1] ""  Vector__XXX
 SG_ SI_BUS_11 : 26|1@1+ (1.0,0.0) [0.0|1] ""  Vector__XXX
 SG_ SI_BUS_12 : 27|1@1+ (1.0,0.0) [0.0|1] ""  Vector__XXX
 SG_ SI_BUS_13 : 28|1@1+ (1.0,0.0) [0.0|1] ""  Vector__XXX
 SG_ SI_BUS_14 : 29|1@1+ (1.0,0.0) [0.0|1] ""  Vector__XXX
 SG_ SI_BUS_15 : 30|1@1+ (1.0,0.0) [0.0|1] ""  Vector__XXX
 SG_ SI_Bus_Identifikation : 32|8@1+ (1.0,0.0) [0.0|255] ""  Vector__XXX

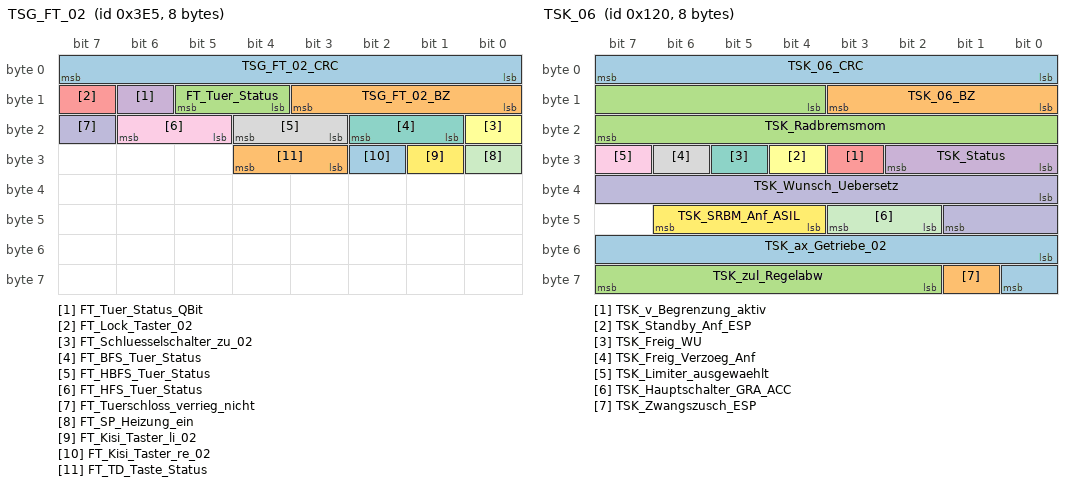
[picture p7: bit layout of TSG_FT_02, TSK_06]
BO_ 997 TSG_FT_02: 8 Gateway_MQB
 SG_ TSG_FT_02_CRC : 0|8@1+ (1,0) [0|255] ""  Bremse_ESP_EPB_EBC460Vi,Bremse_ESP_EPB_MK100
 SG_ TSG_FT_02_BZ : 8|4@1+ (1,0) [0|15] ""  Bremse_ESP_EPB_EBC460Vi,Bremse_ESP_EPB_MK100
 SG_ FT_Tuer_Status : 12|2@1+ (1.0,0.0) [0.0|3] ""  Bremse_ESP_EPB_EBC460Vi,Bremse_ESP_EPB_MK100
 SG_ FT_Tuer_Status_QBit : 14|1@1+ (1.0,0.0) [0.0|1] ""  Vector__XXX
 SG_ FT_Lock_Taster_02 : 15|1@1+ (1.0,0.0) [0.0|1] ""  Vector__XXX
 SG_ FT_Schluesselschalter_zu_02 : 16|1@1+ (1.0,0.0) [0.0|1] ""  Vector__XXX
 SG_ FT_BFS_Tuer_Status : 17|2@1+ (1.0,0.0) [0.0|3] ""  Vector__XXX
 SG_ FT_HBFS_Tuer_Status : 19|2@1+ (1.0,0.0) [0.0|3] ""  Vector__XXX
 SG_ FT_HFS_Tuer_Status : 21|2@1+ (1.0,0.0) [0.0|3] ""  Vector__XXX
 SG_ FT_Tuerschloss_verrieg_nicht : 23|1@1+ (1.0,0.0) [0.0|1] ""  Vector__XXX
 SG_ FT_SP_Heizung_ein : 24|1@1+ (1.0,0.0) [0.0|1] ""  Vector__XXX
 SG_ FT_Kisi_Taster_li_02 : 25|1@1+ (1.0,0.0) [0.0|1] ""  Vector__XXX
 SG_ FT_Kisi_Taster_re_02 : 26|1@1+ (1.0,0.0) [0.0|1] ""  Vector__XXX
 SG_ FT_TD_Taste_Status : 27|2@1+ (1.0,0.0) [0.0|3] ""  Vector__XXX

BO_ 288 TSK_06: 8 Gateway_MQB
 SG_ TSK_06_CRC : 0|8@1+ (1,0) [0|255] ""  Bremse_ESP_EPB_EBC460Vi,Bremse_ESP_EPB_MK100,Bremse_ESP_MK100
 SG_ TSK_06_BZ : 8|4@1+ (1,0) [0|15] ""  Bremse_ESP_EPB_EBC460Vi,Bremse_ESP_EPB_MK100,Bremse_ESP_MK100
 SG_ TSK_Radbremsmom : 12|12@1+ (8,0) [0|32760] "Unit_NewtoMeter"  Bremse_ESP_EPB_EBC460Vi,Bremse_ESP_EPB_MK100,Bremse_ESP_MK100
 SG_ TSK_Status : 24|3@1+ (1.0,0.0) [0.0|7] ""  Bremse_ESP_EPB_EBC460Vi,Bremse_ESP_EPB_MK100,Bremse_ESP_MK100
 SG_ TSK_v_Begrenzung_aktiv : 27|1@1+ (1.0,0.0) [0.0|1] ""  Vector__XXX
 SG_ TSK_Standby_Anf_ESP : 28|1@1+ (1.0,0.0) [0.0|1] ""  Bremse_ESP_EPB_EBC460Vi,Bremse_ESP_EPB_MK100,Bremse_ESP_MK100
 SG_ TSK_Freig_WU : 29|1@1+ (1.0,0.0) [0.0|1] ""  Vector__XXX
 SG_ TSK_Freig_Verzoeg_Anf : 30|1@1+ (1.0,0.0) [0.0|1] ""  Bremse_ESP_EPB_EBC460Vi,Bremse_ESP_EPB_MK100,Bremse_ESP_MK100
 SG_ TSK_Limiter_ausgewaehlt : 31|1@1+ (1.0,0.0) [0.0|1] ""  Vector__XXX
 SG_ TSK_Wunsch_Uebersetz : 32|10@1+ (0.0245,0) [0.0245|25.0635] ""  Vector__XXX
 SG_ TSK_Hauptschalter_GRA_ACC : 42|2@1+ (1.0,0.0) [0.0|3] ""  Vector__XXX
 SG_ TSK_SRBM_Anf_ASIL : 44|3@1+ (1.0,0.0) [0.0|7] ""  Vector__XXX
 SG_ TSK_ax_Getriebe_02 : 48|9@1+ (0.024,-2.016) [-2.016|10.224] "Unit_MeterPerSeconSquar"  Vector__XXX
 SG_ TSK_Zwangszusch_ESP : 57|1@1+ (1.0,0.0) [0.0|1] ""  Bremse_ESP_EPB_EBC460Vi,Bremse_ESP_EPB_MK100,Bremse_ESP_MK100
 SG_ TSK_zul_Regelabw : 58|6@1+ (0.024,0) [0.000|1.512] "Unit_MeterPerSeconSquar"  Vector__XXX

BO_ 1716 VIN_01: 8 Gateway_MQB
 SG_ VIN_01_MUX M  : 0|2@1+ (1,0) [0|3] ""  Bremse_ABS_MK100,Bremse_ESP_EPB_EBC460Vi,Bremse_ESP_EPB_MK100,Bremse_ESP_MK100,Daempfer,Lenkhilfe_EPS
 SG_ KS_Geheimnis_1 m0  : 8|8@1+ (1,0) [0|255] ""  Vector__XXX
 SG_ VIN_4 m1  : 8|8@1+ (1,0) [0|255] ""  Daempfer
 SG_ VIN_11 m2  : 8|8@1+ (1,0) [0|255] ""  Daempfer
 SG_ KS_Geheimnis_2 m0  : 16|8@1+ (1,0) [0|255] ""  Vector__XXX
 SG_ VIN_5 m1  : 16|8@1+ (1,0) [0|255] ""  Daempfer
 SG_ VIN_12 m2  : 16|8@1+ (1,0) [0|255] ""  Daempfer
 SG_ KS_Geheimnis_3 m0  : 24|8@1+ (1,0) [0|255] ""  Vector__XXX
 SG_ VIN_6 m1  : 24|8@1+ (1,0) [0|255] ""  Daempfer
 SG_ VIN_13 m2  : 24|8@1+ (1,0) [0|255] ""  Bremse_ABS_MK100,Bremse_ESP_EPB_EBC460Vi,Bremse_ESP_EPB_MK100,Bremse_ESP_MK100,Daempfer
 SG_ KS_Geheimnis_4 m0  : 32|8@1+ (1,0) [0|255] ""  Vector__XXX
 SG_ VIN_7 m1  : 32|8@1+ (1,0) [0|255] ""  Bremse_ABS_MK100,Bremse_ESP_EPB_EBC460Vi,Bremse_ESP_EPB_MK100,Bremse_ESP_MK100,Daempfer
 SG_ VIN_14 m2  : 32|8@1+ (1,0) [0|255] ""  Bremse_ABS_MK100,Bremse_ESP_EPB_EBC460Vi,Bremse_ESP_EPB_MK100,Bremse_ESP_MK100,Daempfer,Lenkhilfe_EPS
 SG_ VIN_1 m0  : 40|8@1+ (1,0) [0|255] ""  Daempfer
 SG_ VIN_8 m1  : 40|8@1+ (1,0) [0|255] ""  Bremse_ABS_MK100,Bremse_ESP_EPB_EBC460Vi,Bremse_ESP_EPB_MK100,Bremse_ESP_MK100,Daempfer
 SG_ VIN_15 m2  : 40|8@1+ (1,0) [0|255] ""  Bremse_ABS_MK100,Bremse_ESP_EPB_EBC460Vi,Bremse_ESP_EPB_MK100,Bremse_ESP_MK100,Daempfer,Lenkhilfe_EPS
 SG_ VIN_2 m0  : 48|8@1+ (1,0) [0|255] ""  Daempfer
 SG_ VIN_9 m1  : 48|8@1+ (1,0) [0|255] ""  Daempfer
 SG_ VIN_16 m2  : 48|8@1+ (1,0) [0|255] ""  Bremse_ABS_MK100,Bremse_ESP_EPB_EBC460Vi,Bremse_ESP_EPB_MK100,Bremse_ESP_MK100,Daempfer,Lenkhilfe_EPS
 SG_ VIN_3 m0  : 56|8@1+ (1,0) [0|255] ""  Daempfer
 SG_ VIN_10 m1  : 56|8@1+ (1,0) [0|255] ""  Daempfer
 SG_ VIN_17 m2  : 56|8@1+ (1,0) [0|255] ""  Bremse_ABS_MK100,Bremse_ESP_EPB_EBC460Vi,Bremse_ESP_EPB_MK100,Bremse_ESP_MK100,Daempfer,Lenkhilfe_EPS

BO_ 2617218560 XCP_Daempfer_CRO_01: 8 Vector__XXX
 SG_ XCP_Daempfer_CRO_01_Data : 0|64@1+ (1.0,0.0) [0.0|18446744073709551615] ""  Daempfer

BO_ 2617218561 XCP_Daempfer_DTO_01: 8 Daempfer
 SG_ XCP_Daempfer_DTO_01_Data : 0|64@1+ (1.0,0.0) [0.0|18446744073709551615] ""  Vector__XXX

BO_ 2617024000 XCP_ESP_CRO_01: 8 Gateway_MQB
 SG_ XCP_ESP_CRO_01_Data : 0|64@1+ (1.0,0.0) [0.0|18446744073709551615] ""  Bremse_ABS_MK100,Bremse_ESP_EPB_EBC460Vi,Bremse_ESP_EPB_MK100,Bremse_ESP_MK100

BO_ 2617024001 XCP_ESP_DTO_01: 8 Bremse_ABS_MK100
 SG_ XCP_ESP_DTO_01_Data : 0|64@1+ (1.0,0.0) [0.0|18446744073709551615] ""  Gateway_MQB

BO_TX_BU_ 2600468499 :Bremse_ABS_MK100,Bremse_ESP_EPB_EBC460Vi,Bremse_ESP_EPB_MK100,Bremse_ESP_MK100;
BO_TX_BU_ 2550006291 :Bremse_ABS_MK100,Bremse_ESP_EPB_EBC460Vi,Bremse_ESP_EPB_MK100,Bremse_ESP_MK100;
BO_TX_BU_ 2550006282 :PDC,PDC_PLA;
BO_TX_BU_ 1175 :PDC,PDC_PLA;
BO_TX_BU_ 1355 :PDC,PDC_PLA;
BO_TX_BU_ 304 :PDC,PDC_PLA;
BO_TX_BU_ 1166 :PDC,PDC_PLA;
BO_TX_BU_ 1610 :Bremse_ESP_EPB_EBC460Vi,Bremse_ESP_EPB_MK100,Bremse_ESP_MK100;
BO_TX_BU_ 2617024001 :Bremse_ABS_MK100,Bremse_ESP_EPB_EBC460Vi,Bremse_ESP_EPB_MK100,Bremse_ESP_MK100;
CM_ BO_ 1601 "ab MQB mit CRC-8";
CM_ BO_ 1175 "neue Struktur ab MQB ohne KD-Fehler";
CM_ BO_ 1355 "neue Struktur ab MQB ohne KD-Fehler";
CM_ BO_ 1351 "neue Struktur ab MQB ohne KD-Fehler";
CM_ BO_ 304 "Nur im MQB verwendet";
CM_ BO_ 695 "Rear Cross Traffic Assist";
CM_ BO_ 1413 "MQB, MLBevo";
CM_ BO_ 288 "Vorschlag TSK-Schnittstelle MQB";
CM_ BO_ 1716 "200ms bei D4 und folgende";
CM_ BO_ 2617218560 "ab MQB";
CM_ BO_ 2617218561 "ab MQB";
CM_ BO_ 2617024000 "ab MQB";
CM_ BO_ 2617024001 "ab MQB";

CM_ SG_ 1601 MO_Ansaugsystem "Art des Ansaugsystems des Verbrennungsmotors";
CM_ SG_ 1601 MO_Anzahl_Zyl "Zylinderzahl des Verbrennungsmotors";
CM_ SG_ 1601 MO_Anzeige_StSt_gueltig "Zeigt die Gültigkeit der neuen StSt-Anzeigesignale an, MO_Anzeige_StSt_Text und  MO_Anzeige_Symbol. Mo_Text_Motorstart 1..5 sind zu ignorieren.";
CM_ SG_ 1601 MO_Code "Motorcodierinformation Version 8";
CM_ SG_ 1601 MO_DPF_verbaut "Verbauinformation Diesel-Partikel-Filter
";
CM_ SG_ 1601 MO_Faktor_Momente_02 "Dieses Signal schaltet den Wertebereich aller Momente vom Motor, Getriebe, TSK, Bremse ... um! Die Momente besitzen somit einen variablen Wertebereich, weil sich durch den Faktor die Momente sowohl in Auflösung als auch Maximalwerten ändert.

0x0 nicht ";
CM_ SG_ 1601 MO_Getriebe_Code "Getriebecodierung des Motors";
CM_ SG_ 1601 MO_Hubraum "Hubraum des Verbrennungsmotors";
CM_ SG_ 1601 MO_Hybridfahrzeug "Anhand dieses Signals plausibilisiert die Lenkhilfe das Bit Fahrbereitschaft.

Im Projekt Cayenne PHEV (und ggf. auch VW526 PHEV) ist aus Gründen der Abwärtskompatibilität der Wert '2' zu senden.";
CM_ SG_ 1601 MO_Kraftstoffart "Primärkraftstoff zum Antrieb des Fahrzeugs";
CM_ SG_ 1601 MO_Leistung "Nennleistung des Verbrennungsmotors";
CM_ SG_ 1601 MO_OBD_Typ "Abgastyp OBD";
CM_ SG_ 1601 MO_StartStopp_Codiert "Funktion StartStopp im aktuellen Klemmenzyklus verbaut";
CM_ SG_ 1601 Motor_Code_01_CRC "Für MLB:
'Berechnung siehe Lastenheft 'Kommunikationsabsicherung für FlexRay und CAN''

Ab MQB und MLBevo:
'Berechnung siehe Lastenheft 'End-to-End Kommunikationsabsicherung''

Endwerte siehe Begleitdokument 'S-PDU Kennungsfolgen'";
CM_ SG_ 1601 TSK_Codierung "Information über den plausibilisierten Codierungszustand des Triebstrangskoordinators auf ACC oder GRA.";

CM_ SG_ 2600468499 NM_ABS_Car_Wakeup "Car Wakeup (Gateway wertet aus)
MQB: EPB-Lampe wird bei 'Kl. 15 aus' für die Dauer von 30 Sekunden eingeschaltet (Bit bleibt solange gesetzt)";
CM_ SG_ 2600468499 NM_ABS_NM_aktiv_Diagnose "Diagnose befindet sich nach VW80124 in einer NonDefaultDiagnostic-Session, z.B. ExtendedDiagnostic-Session";
CM_ SG_ 2600468499 NM_ABS_NM_aktiv_KL15 "Steuergerät hat KL15-EIN erkannt";
CM_ SG_ 2600468499 NM_ABS_NM_aktiv_Tmin "Mindestaktivzeit ist noch nicht abgelaufen (bei jedem Weckereignis wird die Mindestaktivzeit neu gestartet)";
CM_ SG_ 2600468499 NM_ABS_NM_aktiv_v_gr_0 "Bus gefordert, weil die Bremse nicht den Stillstand aller Räder erkannt hat";
CM_ SG_ 2600468499 NM_ABS_NM_State "1 = Zustand Repeat Message (<-- Bus-Sleep Mode)
2 = Zustand Repeat Message (<-- Prepare Bus-Sleep Mode)
4 = Zustand Normal Operation (<-- Repeat Message)
8 = Zustand Normal Operation (<-- Ready Sleep)";
CM_ SG_ 2600468499 NM_ABS_SNI "Source Node-Identifier (SNI) identifiziert den Sender der NM-Botschaft (Knotenadresse) eindeutig im Fahrzeug";
CM_ SG_ 2600468499 NM_ABS_UDS_CC "Funktionseinschränkung aufgrund aktivem UDS-Communication Control; siehe VW80124";
CM_ SG_ 2600468499 NM_ABS_Wakeup "enthält die Weckursache; stehen mehrere Weckursachen parallel an, dann muss der kleinste Wert übertragen werden";
CM_ SG_ 2600468499 NM_ESP_NM_aktiv_Anzeige_EPB "Bus gefordert, weil EPB-Lampe im Kombi angezeigt werden muss";

CM_ SG_ 2600468496 NM_Gateway_ACAN_Aktivitaet "Dieser Bus wird auf Grund einer Aktivität auf dem Antriebs-CAN wachgehalten (Buskopplung, CAR-Wakeup)";
CM_ SG_ 2600468496 NM_Gateway_Bedien_LIN_Aktivitaet "Dieser Bus wird auf Grund einer Aktivität auf dem Bedien-LIN wachgehalten (Buskopplung, CAR-Wakeup)";
CM_ SG_ 2600468496 NM_Gateway_Car_Wakeup "Car Wakeup (Subbusmaster wertet aus)
MQB: Diagnose- oder Komponentenschutzmaster-Funktion weckt den schlafenden Subbus (z.B. MOST)";
CM_ SG_ 2600468496 NM_Gateway_DiagCAN_Aktivitaet "Dieser Bus wird auf Grund einer Aktivität auf dem Diagnose-CAN wachgehalten (Buskopplung, CAR-Wakeup)";
CM_ SG_ 2600468496 NM_Gateway_ECAN_Aktivitaet "Dieser Bus wird auf Grund einer Aktivität auf dem Extended-CAN wachgehalten (Buskopplung, CAR-Wakeup)";
CM_ SG_ 2600468496 NM_Gateway_EM_Aktivitaet "Dieser Bus wird auf Grund einer Aktivität des Energiemanagements wachgehalten";
CM_ SG_ 2600468496 NM_Gateway_EnergieLIN_Aktivitaet "Dieser Bus wird auf Grund einer Aktivität auf dem Energie-LIN wachgehalten (Buskopplung, CAR-Wakeup)";
CM_ SG_ 2600468496 NM_Gateway_FCAN_Aktivitaet "Dieser Bus wird auf Grund einer Aktivität auf dem Fahrwerks-CAN wachgehalten (Buskopplung, CAR-Wakeup)";
CM_ SG_ 2600468496 NM_Gateway_HVEM_aktiv "Hochvoltenergiemanagement hält ACAN im MQB E wach.
Mögliche Gründe z. B. Ladesteckerentriegelung bei Fahrzeugentriegelung, autonomes Nachladen NV, ...";
CM_ SG_ 2600468496 NM_Gateway_ICAN_Aktivitaet "Dieser Bus wird auf Grund einer Aktivität auf dem Infotainment-CAN wachgehalten (Buskopplung, CAR-Wakeup)";
CM_ SG_ 2600468496 NM_Gateway_KCAN_Aktivitaet "Dieser Bus wird auf Grund einer Aktivität auf dem Komfort-CAN wachgehalten (Buskopplung, CAR-Wakeup)";
CM_ SG_ 2600468496 NM_Gateway_KS_Aktivitaet "Dieser Bus wird auf Grund einer Aktivität des Komponentenschutzes (IKA-Runde) wachgehalten.";
CM_ SG_ 2600468496 NM_Gateway_NL_EM "lokale / interne Aktivität vor WakeUp: Energiemanagement";
CM_ SG_ 2600468496 NM_Gateway_NL_Shutdown "lokale / interne Aktivität vor WakeUp: Shutdown";
CM_ SG_ 2600468496 NM_Gateway_NL_Spg_Messung "lokale / interne Aktivität vor WakeUp: Spannungsmessung";
CM_ SG_ 2600468496 NM_Gateway_NL_Wakeup_Monitor "lokale / interne Aktivität vor WakeUp: Wakeup Monitor";
CM_ SG_ 2600468496 NM_Gateway_NM_aktiv_Diagnose "Diagnose befindet sich nach VW80124 in einer NonDefaultDiagnostic-Session, z.B. ExtendedDiagnostic-Session";
CM_ SG_ 2600468496 NM_Gateway_NM_aktiv_KL15 "Steuergerät hat KL15-EIN erkannt";
CM_ SG_ 2600468496 NM_Gateway_NM_aktiv_Tmin "Mindestaktivzeit ist noch nicht abgelaufen (bei jedem Weckereignis wird die Mindestaktivzeit neu gestartet)";
CM_ SG_ 2600468496 NM_Gateway_NM_State "1 = Zustand Repeat Message (<-- Bus-Sleep Mode)
2 = Zustand Repeat Message (<-- Prepare Bus-Sleep Mode)
4 = Zustand Normal Operation (<-- Repeat Message)
8 = Zustand Normal Operation (<-- Ready Sleep)
16 = Zustand Repeat Message (<-- Ready Sleep)
32 ";
CM_ SG_ 2600468496 NM_Gateway_SNI "Source Node-Identifier (SNI) identifiziert den Sender der NM-Botschaft (Knotenadresse) eindeutig im Fahrzeug";
CM_ SG_ 2600468496 NM_Gateway_UDS_CC "Funktionseinschränkung aufgrund aktivem UDS-Communication Control; siehe VW80124";
CM_ SG_ 2600468496 NM_Gateway_Wakeup "enthält die Weckursache; stehen mehrere Weckursachen parallel an, dann muss der kleinste Wert übertragen werden";

CM_ SG_ 2600468498 NM_Lenkhilfe_Car_Wakeup "Car Wakeup (Gateway wertet aus)
";
CM_ SG_ 2600468498 NM_Lenkhilfe_NM_aktiv_Diagnose "Diagnose befindet sich nach VW80124 in einer NonDefaultDiagnostic-Session, z.B. ExtendedDiagnostic-Session";
CM_ SG_ 2600468498 NM_Lenkhilfe_NM_aktiv_DZ_gr_300 "Bus gefordert bei Drehzahl > 300 1/min";
CM_ SG_ 2600468498 NM_Lenkhilfe_NM_aktiv_Fahrbereit "Bus gefordert bei erkannter Fahrbereitschaft (Hybrid/Elektro)";
CM_ SG_ 2600468498 NM_Lenkhilfe_NM_aktiv_Handlenkmo "Bus gefordert bei anliegendem Handlenkmoment";
CM_ SG_ 2600468498 NM_Lenkhilfe_NM_aktiv_KL15 "Steuergerät hat KL15-EIN erkannt";
CM_ SG_ 2600468498 NM_Lenkhilfe_NM_aktiv_Post_Run "Bus gefordert bei Post Run";
CM_ SG_ 2600468498 NM_Lenkhilfe_NM_aktiv_Tmin "Mindestaktivzeit ist noch nicht abgelaufen (bei jedem Weckereignis wird die Mindestaktivzeit neu gestartet)";
CM_ SG_ 2600468498 NM_Lenkhilfe_NM_aktiv_v_gr_7 "Bus gefordert bei Geschwindigkeit > 7 km/h";
CM_ SG_ 2600468498 NM_Lenkhilfe_NM_State "1 = Zustand Repeat Message (<-- Bus-Sleep Mode)
2 = Zustand Repeat Message (<-- Prepare Bus-Sleep Mode)
4 = Zustand Normal Operation (<-- Repeat Message)
8 = Zustand Normal Operation (<-- Ready Sleep)";
CM_ SG_ 2600468498 NM_Lenkhilfe_SNI "Source Node-Identifier (SNI) identifiziert den Sender der NM-Botschaft (Knotenadresse) eindeutig im Fahrzeug";
CM_ SG_ 2600468498 NM_Lenkhilfe_UDS_CC "Funktionseinschränkung aufgrund aktivem UDS-Communication Control; siehe VW80124";
CM_ SG_ 2600468498 NM_Lenkhilfe_Wakeup "enthält die Weckursache; stehen mehrere Weckursachen parallel an, dann muss der kleinste Wert übertragen werden";

CM_ SG_ 2600468585 NM_Rearview_Car_Wakeup "Car Wakeup (Gateway wertet aus)
";
CM_ SG_ 2600468585 NM_Rearview_NM_aktiv_Diagnose "Diagnose befindet sich nach VW80124 in einer NonDefaultDiagnostic-Session, z.B. ExtendedDiagnostic-Session";
CM_ SG_ 2600468585 NM_Rearview_NM_aktiv_KL15 "Steuergerät hat KL15-EIN erkannt";
CM_ SG_ 2600468585 NM_Rearview_NM_aktiv_Tmin "Mindestaktivzeit ist noch nicht abgelaufen (bei jedem Weckereignis wird die Mindestaktivzeit neu gestartet)";
CM_ SG_ 2600468585 NM_Rearview_NM_State "1 = Zustand Repeat Message (<-- Bus-Sleep Mode)
2 = Zustand Repeat Message (<-- Prepare Bus-Sleep Mode)
4 = Zustand Normal Operation (<-- Repeat Message)
8 = Zustand Normal Operation (<-- Ready Sleep)";
CM_ SG_ 2600468585 NM_Rearview_SNI "Source Node-Identifier (SNI) identifiziert den Sender der NM-Botschaft (Knotenadresse) eindeutig im Fahrzeug";
CM_ SG_ 2600468585 NM_Rearview_UDS_CC "Funktionseinschränkung aufgrund aktivem UDS-Communication Control; siehe VW80124";
CM_ SG_ 2600468585 NM_Rearview_Wakeup "enthält die Weckursache; stehen mehrere Weckursachen parallel an, dann muss der kleinste Wert übertragen werden";

CM_ SG_ 913 MO_QBit_Aussen_Temp "QBit der Aussentemperatur. Gesetzt bei Ersatzwert, Init oder Fehler.";
CM_ SG_ 913 MO_Servicemodus "Ausgabe aktiver Service-Mode";
CM_ SG_ 913 OBD_Abs_Load_Val "Absolute Load Value

Übertragung von Meßgrößen an das Getriebesteuergerät für Freeze Frame Abspeicherung bei Getriebefehlern

PID $43 Absolute Load Value; 0 .. 25700%  mit 100/255 %/bit";
CM_ SG_ 913 OBD_Abs_Pedal_Pos "Absolute Pedal Position

Übertragung von Meßgrößen an das Getriebesteuergerät für Freeze Frame Abspeicherung bei Getriebefehlern

PID $49 Accelerator Pedal Position D; 0 .. 100% mit 100/255 %/bit";
CM_ SG_ 913 OBD_Abs_Throttle_Pos "Absolute Throttle Position

Übertragung von Meßgrößen an das Getriebesteuergerät für Freeze Frame Abspeicherung bei Getriebefehlern

PID $11 Absolute Throttle Position; 0 .. 100% mit 100/255 %/bit";
CM_ SG_ 913 OBD_Calc_Load_Val "Calculated Load Value

Übertragung von Meßgrößen an das Getriebesteuergerät für Freeze Frame Abspeicherung bei Getriebefehlern

PID $04 Calculated Load Value; 0 .. 100% mit 100/255 % per bit
";
CM_ SG_ 913 OBD_Eng_Cool_Temp "Engine Coolant Temperature

Übertragung von Meßgrößen an das Getriebesteuergerät für Freeze Frame Abspeicherung bei Getriebefehlern

PID $05 Engine Coolant Temperature; -40 .. +215°C mit 1°C/bit und 40°C Offset";
CM_ SG_ 913 OBD_Kaltstart_Denominator "Bestimmte Diagnosen werden nur unter Kaltstartbedingungen durchgeführt, der entsprechende Denominator bei IUMPR-pflichtigen Systemen wird anhand dieses vom MSG gebildeten Signals inkrementiert. (Entspricht EVAP-Denominator)";
CM_ SG_ 913 OBD_Minimum_Trip "Grundlage OBD-Gesetz CCR 1968.2 (d)(4.3) Denominator Specifications
Bildung des General Denominator 'Normed Trip':
 600 sec. (kumulativ) Zeit nach Motorstart
 300 sec. (kumulativ) mit Fahrzeuggeschwindigkeit > 25 mph (40 km/h)
 30 sec. (kontinuierlich";
CM_ SG_ 913 OBD_Normed_Trip "Gesetzlich definierte 'Normed Condition' erfüllt, 'General Denominator' darf erhöht werden";
CM_ SG_ 913 OBD_Sperrung_IUMPR "Wenn der General Denominator auf Grund eines Fehlers in den Eingangsgrößen gesperrt wird, wird diese Information über Bussystem als OBD-Statusinformation OBD_Sperrung_IUMPR für andere OBD-Steuergeräte bereitgestellt. 

Das MSG (MIL-Master) setzt dieses ";
CM_ SG_ 913 OBD_Warm_Up_Cycle "Mit dem Warm-Up-Cycle wird der zentrale Verlernzähler vom Gateway inkrementiert";

CM_ SG_ 1175 PDC_Tonausgabe_Front "In Abhängigkeit der Systemaktivitäten werden unterschiedliche Tonwarnungen ausgegeben. 
Kombi spielt entsprechende WAV.-Datei über internen Audiomaster ab.

0 = kein Ton
1 = Intervallton 1
2 = Intervallton 2
3 = Intervallton 3
4 = Intervallton 4
5";
CM_ SG_ 1175 PDC_Tonausgabe_Heck "In Abhängigkeit der Systemaktivitäten werden unterschiedliche Tonwarnungen ausgegeben. 
Kombi spielt entsprechende WAV.-Datei über internen Audiomaster ab.

0 = kein Ton
1 = Intervallton 1
2 = Intervallton 2
3 = Intervallton 3
4 = Intervallton 4
5";
CM_ SG_ 1175 PH_Abschaltursache "Abschaltursache bleibt bis zur nächsten Aktivierung bzw. bis KL15 aus gesetzt
Im Fehlerfall (blinkende LED) wird '7' gesendet obwohl das System noch aktiv ist, bei 'geheiltem' Fehler wird sofort wieder der Zustand '0' gesendet";
CM_ SG_ 1175 PH_Anf_Audioabsenkung "Es gibt zwei unterschiedliche Nachlauftimer für dieses Bit:
1. normale Funktion
2. Demotonausgabe";
CM_ SG_ 1175 PH_Anf_Verdeck "Anforderung an ein Verdeck-System, die vom Fahrer angeforderte Öffnung/Schließung zu verhindern";
CM_ SG_ 1175 PH_defekt "Zeigt an das sich die Parkhilfe im Fehlerzustand befindet. Signal bleibt bis zur nächsten 'Gut-Aktivierung' gesetzt.
Spezialfall: Sensordefekt hinten bei Anhängerbetrieb. Anhänger wird abgesteckt Fehler wird gesetzt. Fehlerfall bleibt bis Behebung des De";
CM_ SG_ 1175 PH_Display_Kundenwunsch "Anzeige der bei Aktivierung verwendeten Parameter bzgl. Kundenwunsch Displayanziege. Änderungen werden erst bei erneuter Aktivierung aktualisiert.";
CM_ SG_ 1175 PH_Frequenz_hinten "Uebertragung der aktuell im APS Steuergeraet gespeicherten Werte fuer Tongeber Frequenz hinten
Anzeige der aktuell verwendeten Parameter (nicht zwingend die abgespeicherten - da Werte erst 2s nach der letzten Änderung gespeichert werden!)";
CM_ SG_ 1175 PH_Frequenz_vorn "Uebertragung der aktuell im APS Steuergeraet gespeicherten Werte fuer Tongeber Frequenz vorne
Anzeige der aktuell verwendeten Parameter (nicht zwingend die abgespeicherten - da Werte erst 2s nach der letzten Änderung gespeichert werden!)";
CM_ SG_ 1175 PH_gestoert "Eine Störung ist aufgetreten, der die Parkhilfe in einen 'gestört-Zustand' versetzt, z.B. massiver Fremdultraschall, Vereisung, Schnee.Derzeit nur für Störschall benutzt, da keinerlei andere Erkennung implementiert.";
CM_ SG_ 1175 PH_Lautstaerke_hinten "Uebertragung der aktuell im APS Steuergeraet gespeicherten Werte fuer Tongeber Lautstaerke hinten
Anzeige der aktuell verwendeten Parameter (nicht zwingend die abgespeicherten - da Werte erst 2s nach der letzten Änderung gespeichert werden!)";
CM_ SG_ 1175 PH_Lautstaerke_vorn "Uebertragung der aktuell im APS Steuergeraet gespeicherten Werte fuer Tongeber Lautstaerke vorn.
Anzeige der aktuell verwendeten Parameter (nicht zwingend die abgespeicherten - da Werte erst 2s nach der letzten Änderung gespeichert werden!)";
CM_ SG_ 1175 PH_nachtr_Stopp_Anf "Dieses Signal dient dem Motor als Trigger, dass ein nachträglicher Motorstopp eingeleitet werden kann, wenn es die Bedingungen des StSt Koordinators dies zulassen. ";
CM_ SG_ 1175 PH_Opt_Anz_H_Hindernis "mindestens 1 Segment wird für den hinteren Detekionsbereich dargestellt, also ein Hindernis ist im Detektionsbereich. Funktion nur bei gesicherter Rückmeldung vom ASG gegeben.";
CM_ SG_ 1175 PH_Opt_Anz_V_Hindernis "mindestens 1 Segment wird für den vorderen Detekionsbereich dargestellt, also ein Hindernis ist im Detektionsbereich. Funktion nur bei gesicherter Rückmeldung vom ASG gegeben.";
CM_ SG_ 1175 PH_Opt_Anzeige_H_ein "OPS hinten ist im Display aktiv bzw. Anzeigemodule hinten sind eingeschaltet. Funktion nur bei gesicherter Rückmeldung vom ASG gegeben.";
CM_ SG_ 1175 PH_Opt_Anzeige_V_ein "OPS vorne ist im Display aktiv bzw. Anzeigemodule vorne sind eingeschaltet. Funktion nur bei gesicherter Rückmeldung vom ASG gegeben.";
CM_ SG_ 1175 PH_StartStopp_Info "Stopp-Freigabe und Start-Anforderung an den Start-Stopp-Koordinator";
CM_ SG_ 1175 PH_Stoermeldung "Meldung einer Störung der PDC an das Kombi";
CM_ SG_ 1175 PH_Systemzustand "Aktivierungsursache wird für die Dauer der Aktivierung gemeldet.
Im Fehlerfall bei atkviem System wechselt das Signal auf '7'
(siehe auch 'Abschaltursache')";
CM_ SG_ 1175 PH_Taster "Taster Status (für RVC/TopView)";
CM_ SG_ 1175 PH_Tongeber_H_aktiv "Rohsignal für 'Tongeber hinten wird angesteuert', verlängerbar mit Nachlauftimer.
Bit wird nicht während des Stellgliedtests angesteuert.";
CM_ SG_ 1175 PH_Tongeber_H_verfuegbar "Tongeber ist für die Tonausgabe für externe Funktionen verfügbar. PDC ist aktiv und Tongeber ist nicht gestört.";
CM_ SG_ 1175 PH_Tongeber_mute "Die Akustikausgabe des Systems wird unterdrückt, z.B. Wählhebel in 'P', Parlbremse geschlossen (8-Kanal-System)";
CM_ SG_ 1175 PH_Tongeber_V_aktiv "Rohsignal für 'Tongeber vorne wird angesteuert', verlängerbar mit Nachlauftimer.
Bit wird nicht während des Stellgliedtests angesteuert.";
CM_ SG_ 1175 PH_Visualisierung "Signal zeigt den Partnersteuergeräten RearView/TopView/ARA/... den aktuellen Status der Visualisierung des OPS. Die Partnersteuergeräte können dadurch auch ihre Aufschaltung an dieses Signal koppeln.";
CM_ SG_ 1175 PLA_Anf_Aufschaltung_RVC "Anforderung der Aufschaltung RVC durch PLA";

CM_ SG_ 1353 PL_Luecke_P0_x "x-Koordinate des Punktes P0
";
CM_ SG_ 1353 PL_Luecke_P0_y "y-Koordinate des Punktes P0";
CM_ SG_ 1353 PL_Luecke_P2_x "x-Koordinate des Punktes P2";
CM_ SG_ 1353 PL_Luecke_P2_y "y-Koordinate des Punktes P2";

CM_ SG_ 1354 PL_Luecke_P1_x "x-Koordinate des Punktes P1";
CM_ SG_ 1354 PL_Luecke_P1_y "y-Koordinate des Punktes P1";
CM_ SG_ 1354 PL_Luecke_P3_x "x-Koordinate des Punktes P3";
CM_ SG_ 1354 PL_Luecke_P3_y "y-Koordinate des Punktes P3";

CM_ SG_ 1355 PDC_Charisma_FahrPr "Istwert der Kennline (siehe System-LAH MQB FPA)";
CM_ SG_ 1355 PDC_Charisma_Status "Charisma Systemstatus des Charisma-Teilnehmers";
CM_ SG_ 1355 PH_Aufschaltursache "Der Grund für die Aufschaltung der Einparkhilfe wird angegeben, z.B. bei der Aktivierung der Einparkhilfe durch eine andere Funktion, wird diese Funktion als Aktivierungsursache für die Dauer der Aktivierung gemeldet.
Das Signal wird den PH_Systemzustand";
CM_ SG_ 1355 PH_Verschmutzungsmeldung "Meldung einer Verschmutzung/Vereisung der PDC an das Kombi";

CM_ SG_ 1351 US_Objekt_links "Signal gibt an, ob während der Fahrt über Ultraschall an der Flanke links ein Objekt erkannt wurde. Für lange Fahrzeuge (wie Crafter) soll die Information genutzt werden, um die Totwinkelüberwachung zu verbessern.";
CM_ SG_ 1351 US_Objekt_rechts "Signal gibt an, ob während der Fahrt über Ultraschall an der Flanke links ein Objekt erkannt wurde. Für lange Fahrzeuge (wie Crafter) soll die Information genutzt werden, um die Totwinkelüberwachung zu verbessern.";
CM_ SG_ 1351 US_Objektueberwachung_Status "Status der Ultraschallobjektüberwachung während der Fahrt. Während der Fahrt sollen dynamische Objekte über Ultraschall erkannt werden, um bei langen Fahrzeugen die Totwinkelüberwachung zu stützen. Im Stand/außerhalb gültiger Geschwindigkeit ist die Funkt";

CM_ SG_ 2527679498 Perso_Aktiv "Status Personalisierung für den Fahrer aktiviert/ deaktiviert (via HMI)";
CM_ SG_ 2527679498 Perso_Bedienstelle "Signal zeigt an, über welche Bedienstelle die Umschaltung des Benutzerkontos gestartet wurden.";
CM_ SG_ 2527679498 Perso_Freigabe_Verstellung "Signal zeigt an, ob die Ergonomiefunktionen nach Umschaltung des Benutzerkontos verfahren dürfen.";
CM_ SG_ 2527679498 Perso_Kontonummer "Signal gibt die jewels aktuelle Kontonummer für die Personalisierung an.
Nicht für AU736 und AU48x.";
CM_ SG_ 2527679498 Perso_Status "Codierstatus der Personalisierung
Nicht für AU736 und AU49x.";
CM_ SG_ 2527679498 Perso_Steuerung "Signal gibt einen Steuerungsbefehl an die Funktionsteilnehmer der Personalisierung.
Nicht für AU736 und AU49x.";
CM_ SG_ 2527679498 Perso_Steuerungsparameter "Signal gibt einen Parameter zum Steuerungsbefehl (Signal Perso_Steuerung) für die Personalisierung an.
Nicht für AU736 und AU49x.";

CM_ SG_ 304 PLA_01_BZ "4bit-Botschaftszaehler, wird in jeder Sendebotschaft inkrementiert

";
CM_ SG_ 304 PLA_01_CRC "Für MLB:
Berechnung siehe Lastenheft 'Kommunikationsabsicherung für FlexRay und CAN''

Ab MQB und MLBevo:
Berechnung siehe Lastenheft 'End-to-End Kommunikationsabsicherung'

Endwerte siehe Begleitdokument 'S-PDU Kennungsfolgen'";
CM_ SG_ 304 PLA_01_Signal_red_cyclic "Zeigt die reduzierte Zykluszeit der CAN-Botschaft 'PLA_01' an.";
CM_ SG_ 304 PLA_Anf_Bremsverzoegerung "Anforderung der Verzögerungsbremsung";
CM_ SG_ 304 PLA_Anhalten "Anhaltewunsch des PLA ";
CM_ SG_ 304 PLA_Anhalteweg "Anhalteweg für die Anhaltewegschnittstelle PLA";
CM_ SG_ 304 PLA_BremsMom_Verzoeg "Kennzeichnung der übertragenen Sollvorgabe
0 = Bremsmoment: MQB A
1 = Bremsverzoegerung: MLBevo, MQB B
Die Bedatung ist im Fahrzeug konstant.";
CM_ SG_ 304 PLA_Bremsmoment "Anforderung eines Summenradbremsmomentes";
CM_ SG_ 304 PLA_Bremsverzoegerung "Wert der Bremsverzögerung für eine Bremsung durch PLA";
CM_ SG_ 304 PLA_LW_Soll "Steuerbefehl an EPS zum Einstellen des angeforderten Lenkwinkels.";
CM_ SG_ 304 PLA_Status_PLA_EPS "Schnittstelle zum Austausch von Statusinformationen der internen Statusmaschine. Erforderlich zum Aktivieren der automatischen Lenkung.";
CM_ SG_ 304 PLA_Status_PLA_ESP "Zustand der Statusmaschine des PLA für die korrespondierenden Statusmaschine in der Bremse.";
CM_ SG_ 304 PLA_VZ_LW_Soll "Vorzeichen zum Lenkwinkel-Steuerbefehl an EPS zum Einstellen des angeforderten Lenkwinkels.";

CM_ SG_ 1174 PLS_Akustik "Dient der akustischen Signalisierung von PLA-Funktionsdeaktivierungen oder Funktionsstörungen";
CM_ SG_ 1174 PLS_Anf_Anz "Anforderung der Anzeige entsprechender Symbolik gem. HMI-Spezifikation im Kombiinstrument. Alle weiteren Darstellungen im Kombiinstrument werden nur  nur zur Anzeige gebracht, wenn dieses Signal gesetzt ist.";
CM_ SG_ 1174 PLS_Anf_Anz_Schwellpfeil "Schalter, mit dem die Anzeige eines Schwellpfeiles ein- bzw. ausgeschaltet wird.";
CM_ SG_ 1174 PLS_Ausparken_Aktiv "Vorhalt für mögliche Unterscheiungen in der Anzeige. Kennzeichnet einen aktiven Ausparkvorgang und dient der Anzeige geeigneter Informationen im Kombiinstrument, die sich von der Anzeige währende des Einparkvorganges unterscheiden.";
CM_ SG_ 1174 PLS_Bremsleuchte "Bei einer durch PLA initiierten Bremsung des Fahrzeugs muss Bremsleuchte angesteuert werden. Dieses Signal ist der Befehl, die Bremsleuchte einzuschalten, an dasjenige Steuergerät, das sie schaltet.";
CM_ SG_ 1174 PLS_Bremssymbol "Dient der Anzeige zur Aufforderung, das Bremspedal getreten zu halten, solange im Stillstand die Räder eingelenkt werden.";
CM_ SG_ 1174 PLS_Fahrtrichtg_Mehrzg "Fahrtrichtungsempfehlung bei mehrzügigem Ein- und Ausparken";
CM_ SG_ 1174 PLS_Kurze_Luecke "Schalter, mit dem eine Kurze Lücke erkannt wird, damit die Anzeige eines Schwellpfeiles ein- bzw. ausgeschaltet wird.
";
CM_ SG_ 1174 PLS_Laengs_Querluecke "Anzeige gemäß Auswahl der Parkfunktion für Längs- oder Querparklücke.";
CM_ SG_ 1174 PLS_Lenk_Aktiv_Hinweis "Anzeige des Symbols, das für Aktiv-Lenkung verwendet wird. Das Signal steuert den Anzeigebilschirm für den Hinweis und liegt nicht während des gesammten aktiven automatischen Lenkeigriffs an.";
CM_ SG_ 1174 PLS_Mehrzg_Aktiv "Schalter, mit dem die Bedienbildschirme der Fahrtrichtungsempfehlung bei mehrzügigem Ein- und Ausparken Anzeige erfolgt wird.";
CM_ SG_ 1174 PLS_PL_Exist "Anzeige des Symbols, das für die Parklückeinfo verwendet wird. Anzeige entsprechender Symbolik gem. HMI-Spezifikation im Kombiinstrument";
CM_ SG_ 1174 PLS_PL_Seite "Anzeige gemäß Auswahl der Parklückenseite für Ein- und Ausparken";
CM_ SG_ 1174 PLS_Pos_OK "Schalter, mit dem die Anzeige einer optimale Position zum erstmaligem  Einlegen des Rückwärtsgang bei der Einparkfunktion ausgeschaltet wird.";
CM_ SG_ 1174 PLS_Schwellpfeil_abs "Anzeige eines Schwellpfeils während Vorwärts- oder Rückwärtsfahrt in einer Parklücke, der den absoluten Abstand in gewünschter Richtung bis zum tatsächlichen Wendepunkt anzeigt. (Pfeil läuft leer).";
CM_ SG_ 1174 PLS_Schwellpfeil_rel "Anzeige eines Schwellpfeils während Vorwärts- oder Rückwärtsfahrt in einer Parklücke, der den relativen Abstand in gewünschter Richtung bis zum tatsächlichen Wendepunkt anzeigt. Der Pfeil läuft bis zur Aufforderung zum Fahrtrichtungswechsel leer.";
CM_ SG_ 1174 PLS_Standby "Anzeige des Symbols, das für Standby-Anzeige verwendet wird. Standby-Zustand zeigt an, dass die Fzg.-Geschwindigkeit zu hoch zum Vermessen von Parklücken ist, das System sich bei Unterschreiten einer Geschwindigkeitsschwelle wieder selbständig zur Anzeige";

CM_ SG_ 1166 PLA_Anf_Akustik "Anzeige, ob das PLA einen Gong im Kombi anfordert, Gong soll mit dem Übergang 0->1 abgespielt werden.";
CM_ SG_ 1166 PLA_Anf_Anzeige_Bremsfuss "Anzeige, ob PLA die Anzeige eines Bremsfusses anfordert";
CM_ SG_ 1166 PLA_Anf_Anzeige_Mini "Anforderung der Miniaturanzeige ";
CM_ SG_ 1166 PLA_Anf_Anzeige_Schwellpfeil "Anzeige, ob PLA im Kombi den Schwellpfeil zur Darstellung der Restwegstrecke im aktuellen Zug anfordert";
CM_ SG_ 1166 PLA_Anf_Anzeigemodus "Anzeigemodus das vom PLA je nach Parkszenario beim Kombi angefordert wird";
CM_ SG_ 1166 PLA_Anf_Funktionsdisclaimer "Anforderung des Funktionsdisclaimer durch PLA";
CM_ SG_ 1166 PLA_Anf_Meldungen "Anforderung der Meldungen:
0 - Keine Meldung
1-127 niederprio. Meldungen
128-255 hochprio. Meldungen";
CM_ SG_ 1166 PLA_Anzahl_Segmente_Schwellpfeil "Wird ein Schwellpfeil angezeigt, gibt dieses Signal die Länge des breiten Balkens in Anzahl der Segmente (max. Länge: 15 Segmente).

Wird keine Anzeige der Schwellpfeile angefordert, muss die Anzahl Segmente 0 sein.";
CM_ SG_ 1166 PLA_Mini_Modus "Art des vom PLA zur Darstellung angeforderten Minis. Wird angezeigt, wenn PLA_Anf_Anzeige_Mini=1.";
CM_ SG_ 1166 PLA_Status_Aktive_Seite "Anzeige der zu parkenden Seite";
CM_ SG_ 1166 PLA_Status_beenden_Mini "Status Anzeige beendet Mini";
CM_ SG_ 1166 PLA_Status_Funktion "Funktionsstati, die die einzelnen Schritte innerhalb eines Parkszenarios anzeigen.";
CM_ SG_ 1166 PLA_Status_Laengsparken_Mini "Status Anzeige Längsparken Mini";
CM_ SG_ 1166 PLA_Status_QP_Rueckw_Mini "Status Anzeige Querparken rückwärts Mini";
CM_ SG_ 1166 PLA_Status_QP_Vorw_Mini "Status Anzeige Querparken vorwärtsMini";

CM_ SG_ 695 RCTA_01_BZ "4bit-Botschaftszaehler, wird in jeder Sendebotschaft inkrementiert";
CM_ SG_ 695 RCTA_01_CRC "Für MLB:
'Berechnung siehe Lastenheft 'Kommunikationsabsicherung für FlexRay und CAN''

Ab MQB und MLBevo:
'Berechnung siehe Lastenheft 'End-to-End Kommunikationsabsicherung''

Endwerte siehe Begleitdokument 'S-PDU Kennungsfolgen'";
CM_ SG_ 695 RCTA_Anforderung_HMS "Nach einer Notbremsung durch RCTA muss das Fahrzeug halten. Deshalb ist eine HMS-Anforderung mit der Notbremsung erforderlich.";
CM_ SG_ 695 RCTA_Bremsruck_Anforderung "RCTA_Bremsruck_Anforderung  ist die Anforderung an das Bremssystem einen kurzen Bremsruck auszuführen. Mit dem Signal 'RCTA_Bremsruck_Freigabe' zusammen wird der Ruck ausgeführt. Dadurch soll der Fahrer auf eine mögliche Kollision hingewiesen und zum Brem";
CM_ SG_ 695 RCTA_Bremsruck_Freigabe "RCTA_Bremsruck_Freigabe ist die eigentliche Auforderung (mit dem Signal 'RCTA_Bremsruck_Anforderung') an das Bremssystem einen kurzen Bremsruck auszuführen. Dadurch soll der Fahrer auf eine mögliche Kollision hingewiesen und zum Bremsen animiert werden.";
CM_ SG_ 695 RCTA_Info_links "Das alte RCTA_Info wird aufgeteilt in RCTA_Info_links und RCTA_Info_rechts. Damit sollen Richtungsblinken oder ähnliches aufgrund der RCTA-Funtkion möglich gemacht werden.

Dieser Parameter ist eine zusätzliche Information zu RCTA. Andere Systeme können";
CM_ SG_ 695 RCTA_Info_rechts "Das alte RCTA_Info wird aufgeteilt in RCTA_Info_links und RCTA_Info_rechts. Damit sollen Richtungsblinken oder ähnliches aufgrund der RCTA-Funtkion möglich gemacht werden.

Dieser Parameter ist eine zusätzliche Information zu RCTA. Andere Systeme können";
CM_ SG_ 695 RCTA_Kritikalitaetslevel_links "Mit dem Signal wird das Kritikalitätslevel der Funktion RCTA dargestellt.
Je höher das Kritikalitätslevel ist, je höher die Crashwahrscheinlichkeit.
Die Kritikalität ist nicht bewertbar, wenn
-	die Funktion im Anhängerbetrieb ist
-	die Sensorsicht blo";
CM_ SG_ 695 RCTA_Kritikalitaetslevel_rechts "Mit dem Signal wird das Kritikalitätslevel der Funktion RCTA dargestellt.
Je höher das Kritikalitätslevel ist, je höher die Crashwahrscheinlichkeit.
Die Kritikalität ist nicht bewertbar, wenn
-	die Funktion im Anhängerbetrieb ist
-	die Sensorsicht blo";
CM_ SG_ 695 RCTA_Modus "gibt die Verfügbarkeit der RCTA Modus an";
CM_ SG_ 695 RCTA_Notbremsung_Anforderung "RCTA_Notbremsung_Anforderung  ist die Anforderung der Funktion RCTA an das Bremssystem. Mit dem Signal 'Notbremsung_Freigabe' zusammen wird die Bremsung eingeleitet. Dadurch sollen größere Schäden am Fahrzeug verhindert werden.";
CM_ SG_ 695 RCTA_Notbremsung_Freigabe "RCTA_Notbremsung_Freigabe ist die eigentliche Auforderung (mit dem Signal 'Notbremsung_Anforderung_Wert') an das Bremssystem eine Notfallbremsung einzuleiten. Dadurch sollen größere Schäden am Fahrzeug vermieden werden.";
CM_ SG_ 695 RCTA_Status "RCTA_Status ist die Rückmeldung, ob das System überhaupt aktiv ist. Mögliche Zustände sind: Das System ist aus; Das System ist nur passiv (läuft, ist aber ohne Funktionalität); Das System ist aktiv; Das System ist fehlerhaft";
CM_ SG_ 695 RCTA_Warnton "Ansteuerung APS Tongeber für  Warnton von RCTA. (Dauerton)";

CM_ SG_ 1711 RV_Dark_Screen "Verdunkelungsanforderung Kamerabild";
CM_ SG_ 1711 RV_Farbe "Istwert fuer Farbe (in Prozent)";
CM_ SG_ 1711 RV_Helligkeit "Istwert fuer Helligkeit (in Prozent)";
CM_ SG_ 1711 RV_HMI_Mode "Aktueller Wert für den HMI-Modus

";
CM_ SG_ 1711 RV_Kontrast "Istwert fuer Kontrast (in Prozent)";
CM_ SG_ 1711 RV_Menu_Item "Ausgewähltes Menü-Item
";
CM_ SG_ 1711 RV_Reinigung_Anf "Anforderung Reinigung der Rückfahrkamera";
CM_ SG_ 1711 RV_Settings_enabled "Menü 'Einstellungen'
";
CM_ SG_ 1711 RV_System_aktiv "Systemstatus (Initialisierungsphase)
";
CM_ SG_ 1711 RV_Video_on "Anzeige Kamerabild
";
CM_ SG_ 1711 SV_Video_on "Aufschaltaufforderung SideView";

CM_ SG_ 1610 RKA_Druckwarnung_RdW "Druckwarnung für RdW-Projekte, bei Druckverlust Prio1

Kein Einsatz RKA im D4 Hybrid";
CM_ SG_ 1610 RKA_FMVSS138_Lampe "Kein Einsatz RKA im D4 Hybrid";
CM_ SG_ 1610 RKA_FMVSS138_MIL "Zentral blinkend für 1 Minute immer nur gelbe Lampe, dann statisch an. 

Kein Einsatz RKA im D4 Hybrid";
CM_ SG_ 1610 RKA_KD_Fehler "Bit wird nur bedient, wenn RDK am Komfort-CAN verbaut ist! Wenn RKA am Dashboard-CAN oder FlexRay (im ESP) vorhanden ist, dann darf das KD-Bit vom ESP-Steuergerät nie mit 0x1 bedient, es muss immer mit Null gesendet werden. Gateway darf Signal zur Verbauk";
CM_ SG_ 1610 RKA_Warnungen "Warnungen der RKA
 
0xA - 0xF = tbd. 

Kein Einsatz RKA im D4 Hybrid";
CM_ SG_ 1610 RKA_Warnungen_02 "Ansteuerung der Warnungen (Texte, Töne, Lampen) im Kombi für Funktion RKA+

Kein Einsatz RKA im D4 Hybrid
";

CM_ SG_ 1710 SP_abklappen "Spiegel abklappen";
CM_ SG_ 1710 SP_anklappen "Spiegel anklappen";
CM_ SG_ 1710 SP_ARA_Status "Rückkanal TSG im ARA-Modus";
CM_ SG_ 1710 SP_Auswahl_li "Spiegelschalter in Stellung Auswahl links";
CM_ SG_ 1710 SP_Auswahl_re "Spiegelschalter in Stellung Auswahl rechts";
CM_ SG_ 1710 SP_BT_links "Spiegel Beifahrertür nach links";
CM_ SG_ 1710 SP_BT_oben "Spiegel Beifahrertür nach oben";
CM_ SG_ 1710 SP_BT_rechts "Spiegel Beifahrertür nach rechts";
CM_ SG_ 1710 SP_BT_unten "Spiegel Beifahrertür nach unten";
CM_ SG_ 1710 SP_FT_links "Spiegel Fahrertür nach links";
CM_ SG_ 1710 SP_FT_oben "Spiegel Fahrertür nach oben";
CM_ SG_ 1710 SP_FT_rechts "Spiegel Fahrertür nach rechts";
CM_ SG_ 1710 SP_FT_unten "Spiegel Fahrertür nach unten";
CM_ SG_ 1710 SP_Hzg_Taster "Heizungstaster/schalter aktiv";
CM_ SG_ 1710 SP_normieren "Spiegel normieren";
CM_ SG_ 1710 SP_S_Klappen "Spiegelschalter in Stellung Klappen";
CM_ SG_ 1710 SP_S_links "Spiegelschalter in Stellung links";
CM_ SG_ 1710 SP_S_oben "Spiegelschalter in Stellung oben";
CM_ SG_ 1710 SP_S_rechts "Spiegelschalter in Stellung rechts";
CM_ SG_ 1710 SP_S_unten "Spiegelschalter in Stellung unten";
CM_ SG_ 1710 SP_Spg_Verstellschalter_Fehler "Erkennung eines hängenden Spiegelverstellschalters";

CM_ SG_ 1413 GW_KD_Fehler "Kundendienstfehlerbit Gateway zur Anzeige eines im Gateway abgelegten Fehlerspeichereintrages.";
CM_ SG_ 1413 SI_BUS_01 "MQB/PQ26: ACAN
MLBevo: HCAN";
CM_ SG_ 1413 SI_BUS_02 "MQB: FCAN
MLBevo: Frei";
CM_ SG_ 1413 SI_BUS_03 "MQB/PQ26: KCAN
MLBevo: KCAN";
CM_ SG_ 1413 SI_BUS_04 "MQB: ICAN
MLBevo: ICAN";
CM_ SG_ 1413 SI_BUS_05 "MQB/PQ26: DiagCAN
MLBevo: DiagCAN";
CM_ SG_ 1413 SI_BUS_06 "MQB/PQ26: ECAN
MLBevo: ECAN";
CM_ SG_ 1413 SI_BUS_07 "MQB: LIN1 (Energie)
MLBevo: LIN1 (Energie)";
CM_ SG_ 1413 SI_BUS_08 "MQB: LIN2 (MFL)
MLBevo: LIN2 (MFL)";
CM_ SG_ 1413 SI_BUS_09 "MQB: LIN3 (unbelegt)
MLBevo: LIN3 (Energie2)";
CM_ SG_ 1413 SI_BUS_10 "MLBevo: Flexray";
CM_ SG_ 1413 SI_BUS_11 "MLBevo: Ethernet";
CM_ SG_ 1413 SI_BUS_12 "MQB: unbelegt
MLBevo: K2CAN";
CM_ SG_ 1413 SI_BUS_13 "MQB: unbelegt
MLBevo: DCAN";
CM_ SG_ 1413 SI_Bus_Identifikation "Das Signal identifiziert den Bus eindeutig. Das Signal ist konstant auf jedem Bus.
Der Signalwert entspricht dem Wert 'Busnummer' aus der VW80127 Gateway_component_list_databus_identification (0x2A2D) 'Bus-Identifier'.";
CM_ SG_ 1413 SI_Diagnose_Aktiv "Gibt an ob Diagnose-Botschaften empfangen werden und somit eine Diagnose aktiv ist.
MQB: Gibt an ob Diagnose-Bus Botschaften empfangen werden und somit eine Diagnose aktiv ist.";
CM_ SG_ 1413 SI_NWDF "Netzwerk-Diagnose Freigebe zur zentralen Aktivierung der Netzwerkdiagnose";
CM_ SG_ 1413 SI_NWDF_gueltig "Gültigkeitsbit zu SI_NWDF gemäß Lastenheft: Zentrale Aktivierung Netzwerkdiagnose";
CM_ SG_ 1413 SI_Sammel_SG_Fehler "Anzahl der gesetzten KD-Fehler direkt angeschlossener Steuergeräte der DK3 und DK4 gemäß 80127.
Hinweis: Ein Subbusmaster stellt nur die gesammelte Information der an ihn angeschlossenen Steuergeräte der DK3 und DK4 zur Verfügung.

Für ServiceKey Auswe";
CM_ SG_ 1413 SI_Sammelfehler "Sammelfehlermeldung zur Anzeige im Kombi - siehe Spez. Sammelfehlermeldung
Hinweis: Einzelne Steuergeräte können zur Anpassung an den Produktionsprozess im Gateway auskodiert werden!";
CM_ SG_ 1413 SI_T_Mode "0x0: Transportmodus nicht aktiv
0x1: Transportmodus aktiv";
CM_ SG_ 1413 SI_T_Schutz "Transportschutz-Signal, das bei Transportmodus und Motorlauf aktiv bleibt
0x0: Transportschutz nicht aktiv
0x1: Transportschutz aktiv";

CM_ SG_ 997 FT_BFS_Tuer_Status "Gesammelte Türstatusbotschaft";
CM_ SG_ 997 FT_HBFS_Tuer_Status "Türstatus mit Fehler und Initwert";
CM_ SG_ 997 FT_HFS_Tuer_Status "Türstatus mit Fehler und Initwert";
CM_ SG_ 997 FT_Kisi_Taster_li_02 "Der Kindersicherungstaster hinten links aktiv.";
CM_ SG_ 997 FT_Kisi_Taster_re_02 "Der Kindersicherungstaster hinten rechts aktiv.";
CM_ SG_ 997 FT_Lock_Taster_02 "Lock-Taster betätigt";
CM_ SG_ 997 FT_Schluesselschalter_zu_02 "Schlüsselschalter für Schließen betätigt";
CM_ SG_ 997 FT_SP_Heizung_ein "Dieses Signal zeigt die tatsächliche Ansteuerung der  Spiegelheizung incl. PWM an. 
Zudem wird aufgrund des Teilnetzbetriebs das Signal zur Ansteuerung der Beifahrer-Spiegelheizung benutzt.

";
CM_ SG_ 997 FT_TD_Taste_Status "Status Taste für Tankdeckel";
CM_ SG_ 997 FT_Tuer_Status "Tür geöffnet oder Tür geschlossen";
CM_ SG_ 997 FT_Tuer_Status_QBit "Dieses Bit gibt die Zuverlässigkeit des Türkontakts an.";
CM_ SG_ 997 FT_Tuerschloss_verrieg_nicht "Die Fahrertür kann nicht verriegelt werden.";
CM_ SG_ 997 TSG_FT_02_BZ "4bit Botschaftszaehler, wird mit jeder Sendebotschaft inkrementiert";
CM_ SG_ 997 TSG_FT_02_CRC "Für MLB:
'Berechnung siehe Lastenheft 'Kommunikationsabsicherung für FlexRay und CAN''

Ab MQB und MLBevo:
'Berechnung siehe Lastenheft 'End-to-End Kommunikationsabsicherung''

Endwerte siehe Begleitdokument 'S-PDU Kennungsfolgen'";

CM_ SG_ 288 TSK_06_CRC "Für MLB:
'Berechnung siehe Lastenheft 'Kommunikationsabsicherung für FlexRay und CAN''

Ab MQB und MLBevo:
'Berechnung siehe Lastenheft 'End-to-End Kommunikationsabsicherung''

Endwerte siehe Begleitdokument 'S-PDU Kennungsfolgen'";
CM_ SG_ 288 TSK_ax_Getriebe_02 "Beschleunigungsanforderung des Beschleunigungsreglers (u. a. für ACC, GRA, Speed Limiter). Das Signal wird vom Getriebe benutzt, um die von GRA/ACC geforderte Sollbeschleunigung in dem verbrauchsgünstigsten Gang einzustellen.
MQB: Im MQB wird die Sollbes";
CM_ SG_ 288 TSK_Freig_Verzoeg_Anf "Freigabe der Verzögerungsanforderung der ACC oder ggf. GRA+ Funktion für ECD Regelung im ESP";
CM_ SG_ 288 TSK_Freig_WU "Freigabe des TSK_Übersetzungswunsches bei ACC/GRA Betrieb bergab für die Verstellung nach kurz bzw. Rückschaltung im Getriebe.";
CM_ SG_ 288 TSK_Hauptschalter_GRA_ACC "Stellung des GRA/ACC Hauptschalters. Das Signal wird auch bei Fehlerabschaltungen von GRA/ACC weiterhin bedient und ermöglicht für ACC die Steuerung der ACC-Anzeige auch in Fehlerfällen.";
CM_ SG_ 288 TSK_Limiter_ausgewaehlt "ACC/GRA-Betrieb nur bei nicht ausgewähltem Limiter möglich";
CM_ SG_ 288 TSK_Radbremsmom "Bei der Schnittstelle vom TSK zum ESP soll in Folgeprojekten des B8 und insbesondere bei VW-Projekten die Ansteuerung der Bremse nicht über Sollbeschleunigung sondern Bremsmoment erfolgen.  Es handelt sich genauer um das Summenradbremsmoment, welches die ";
CM_ SG_ 288 TSK_SRBM_Anf_ASIL "ASIL-Level des TSK-Anforderers, der aktuell eine Bremsmomentenanforderung auslöst";
CM_ SG_ 288 TSK_Standby_Anf_ESP "Mit diesem Bit wird das aktive Bremssystem auf eine anstehende TSK-Verzögerungsanforderung vorbereitet (Überfahren Leerweg, Anlegen Bremsbeläge)";
CM_ SG_ 288 TSK_Status "Betriebszustand des TSK-Reglers";
CM_ SG_ 288 TSK_v_Begrenzung_aktiv "Limiter oder HGB begrenzen die Beschleunigung/das Moment";
CM_ SG_ 288 TSK_Wunsch_Uebersetz "Bei ACC/GRA Betrieb bergab teilt der TSK dem Getriebe mit, dass eine Drehzahlerhöhung erwünscht ist, um mehr Schleppmoment und damit verbunden die nötige Verzögerung zu erzeugen, um die Geschwindigkeit konstant zu halten. 

Nutzung im VL: das Getriebe v";
CM_ SG_ 288 TSK_zul_Regelabw "Anforderung der zulässigen Regelabweichung vom Triebstrangkoordinator. Zulässiger Betrag der Abweichung zwischen angeforderter 'TSK_Sollbeschleunigung_Getriebe' und umzusetzender Sollbeschleunigung  im Getriebe. Im TSK wird, abhängig vom Arbeitspunkt die ";
CM_ SG_ 288 TSK_Zwangszusch_ESP "Mit diesem Bit wird das ESP/ASR zwangsweise aktiviert. Bei gesetztem Bit ist ein ausgetastetes ESP (oder ASR) wieder aktiviert bzw. wird die Austastung verhindert.";

CM_ SG_ 1716 VIN_01_MUX "Achtung:
Die Botschaft ist nicht linear gemultiplext!!!
Sondern 0,1,0,2,0, usw.";
CM_ SG_ 1716 VIN_1 "Initwert:
0x2D bei Fahrzeugen mit Wegfahrsperrengeneration >= 5 
0x58 bei Fahrzeugen mit Wegfahrsperrengeneration < 5 (z.B. WFS-4)";
CM_ SG_ 1716 VIN_10 "Initwert:
0x2D bei Fahrzeugen mit Wegfahrsperrengeneration >= 5 
0x58 bei Fahrzeugen mit Wegfahrsperrengeneration < 5 (z.B. WFS-4)";
CM_ SG_ 1716 VIN_11 "Initwert:
0x2D bei Fahrzeugen mit Wegfahrsperrengeneration >= 5 
0x58 bei Fahrzeugen mit Wegfahrsperrengeneration < 5 (z.B. WFS-4)";
CM_ SG_ 1716 VIN_12 "Initwert:
0x2D bei Fahrzeugen mit Wegfahrsperrengeneration >= 5 
0x58 bei Fahrzeugen mit Wegfahrsperrengeneration < 5 (z.B. WFS-4)";
CM_ SG_ 1716 VIN_13 "Initwert:
0x2D bei Fahrzeugen mit Wegfahrsperrengeneration >= 5 
0x58 bei Fahrzeugen mit Wegfahrsperrengeneration < 5 (z.B. WFS-4)";
CM_ SG_ 1716 VIN_14 "Initwert:
0x2D bei Fahrzeugen mit Wegfahrsperrengeneration >= 5 
0x58 bei Fahrzeugen mit Wegfahrsperrengeneration < 5 (z.B. WFS-4)";
CM_ SG_ 1716 VIN_15 "Initwert:
0x2D bei Fahrzeugen mit Wegfahrsperrengeneration >= 5 
0x58 bei Fahrzeugen mit Wegfahrsperrengeneration < 5 (z.B. WFS-4)";
CM_ SG_ 1716 VIN_16 "Initwert:
0x2D bei Fahrzeugen mit Wegfahrsperrengeneration >= 5 
0x58 bei Fahrzeugen mit Wegfahrsperrengeneration < 5 (z.B. WFS-4)";
CM_ SG_ 1716 VIN_17 "Initwert:
0x2D bei Fahrzeugen mit Wegfahrsperrengeneration >= 5 
0x58 bei Fahrzeugen mit Wegfahrsperrengeneration < 5 (z.B. WFS-4)";
CM_ SG_ 1716 VIN_2 "Initwert:
0x2D bei Fahrzeugen mit Wegfahrsperrengeneration >= 5 
0x58 bei Fahrzeugen mit Wegfahrsperrengeneration < 5 (z.B. WFS-4)";
CM_ SG_ 1716 VIN_3 "Initwert:
0x2D bei Fahrzeugen mit Wegfahrsperrengeneration >= 5 
0x58 bei Fahrzeugen mit Wegfahrsperrengeneration < 5 (z.B. WFS-4)";
CM_ SG_ 1716 VIN_4 "Initwert:
0x2D bei Fahrzeugen mit Wegfahrsperrengeneration >= 5 
0x58 bei Fahrzeugen mit Wegfahrsperrengeneration < 5 (z.B. WFS-4)";
CM_ SG_ 1716 VIN_5 "Initwert:
0x2D bei Fahrzeugen mit Wegfahrsperrengeneration >= 5 
0x58 bei Fahrzeugen mit Wegfahrsperrengeneration < 5 (z.B. WFS-4)";
CM_ SG_ 1716 VIN_6 "Initwert:
0x2D bei Fahrzeugen mit Wegfahrsperrengeneration >= 5 
0x58 bei Fahrzeugen mit Wegfahrsperrengeneration < 5 (z.B. WFS-4)";
CM_ SG_ 1716 VIN_7 "Initwert:
0x2D bei Fahrzeugen mit Wegfahrsperrengeneration >= 5 
0x58 bei Fahrzeugen mit Wegfahrsperrengeneration < 5 (z.B. WFS-4)";
CM_ SG_ 1716 VIN_8 "Initwert:
0x2D bei Fahrzeugen mit Wegfahrsperrengeneration >= 5 
0x58 bei Fahrzeugen mit Wegfahrsperrengeneration < 5 (z.B. WFS-4)";
CM_ SG_ 1716 VIN_9 "Initwert:
0x2D bei Fahrzeugen mit Wegfahrsperrengeneration >= 5 
0x58 bei Fahrzeugen mit Wegfahrsperrengeneration < 5 (z.B. WFS-4)";
BA_DEF_REL_ BU_SG_REL_  "GenSigTimeoutTime" INT 0 65535;
BA_DEF_ BO_  "DiagRequest" ENUM "No", "Yes";
BA_DEF_ BO_  "DiagResponse" ENUM "No", "Yes";
BA_DEF_ BO_  "DiagState" ENUM "No", "Yes";
BA_DEF_ BO_  "GenMsgChkConstant" HEX 0 4095;
BA_DEF_ BO_  "GenMsgCycleTime" INT 0 65535;
BA_DEF_ BO_  "GenMsgCycleTimeFast" INT 0 65535;
BA_DEF_ BO_  "GenMsgDelayTime" INT 0 100000;
BA_DEF_ BO_  "GenMsgILSupport" ENUM "No", "Yes";
BA_DEF_ BO_  "GenMsgNrOfRepetition" INT 0 100;
BA_DEF_ BO_  "GenMsgPDUConstants" STRING;
BA_DEF_ BO_  "GenMsgSendType" ENUM "Cyclic", "not_used", "not_used", "not_used", "not_used", "not_used", "not_used", "IfActive", "NoMsgSendType";
BA_DEF_ BO_  "GenMsgStartDelayTime" INT 0 100000;
BA_DEF_ BO_  "NmMessage" ENUM "No", "Yes";
BA_DEF_ BO_  "NmhMessage" ENUM "No", "Yes";
BA_DEF_ BO_  "MsgType" ENUM "Application", "NM ", "NMH", "TP2.0", "ISO-TP ", "BAP", "EID", "KS";
BA_DEF_ BO_  "VAGTP20_API" HEX 0 255;
BA_DEF_ BO_  "VAGTP20_DynConnection" ENUM "No", "Yes";
BA_DEF_ BO_  "VAGTP20_DynSetup" ENUM "No", "Yes";
BA_DEF_ BO_  "VAGTP20_StatConnection" ENUM "No", "Yes";
BA_DEF_ SG_  "GenSigActiveRepetitions" INT -2147483648 2147483647;
BA_DEF_ SG_  "GenSigInactiveValue" INT -2147483648 2147483647;
BA_DEF_ SG_  "GenSigSendType" ENUM "Cyclic", "OnWrite", "OnWriteWithRepetition", "OnChange", "OnChangeWithRepetition", "IfActive", "IfActiveWithRepetition", "NoSigSendType", "OnChangeAndIfActive", "OnChangeAndIfActiveWithRepetition";
BA_DEF_ SG_  "GenSigStartValue" INT -2147483648 2147483647;
BA_DEF_ SG_  "NWM-WakeupAllowed" ENUM "No", "Yes";
BA_DEF_ SG_  "GenSigFuncType" ENUM "NoFunction", "MsgCounter", "CRC-8", "XOR", "XOR-2", "DatedBit", "SW-Kl15", "CHK", "Constant", "Protocol", "CRC-8-SAE_J1850";
BA_DEF_ SG_  "GenSigSwitchedByIgnition" ENUM "No", "Yes";
BA_DEF_ SG_  "Fehlerwert" HEX 0 2147483647;
BA_DEF_ SG_  "GenSigMissingSourceValue" HEX 0 2147483647;
BA_DEF_DEF_REL_  "GenSigTimeoutTime" 0;
BA_DEF_DEF_  "DiagRequest" "No";
BA_DEF_DEF_  "DiagResponse" "No";
BA_DEF_DEF_  "DiagState" "No";
BA_DEF_DEF_  "GenMsgChkConstant" 0;
BA_DEF_DEF_  "GenMsgCycleTime" 0;
BA_DEF_DEF_  "GenMsgCycleTimeFast" 0;
BA_DEF_DEF_  "GenMsgDelayTime" 0;
BA_DEF_DEF_  "GenMsgILSupport" "No";
BA_DEF_DEF_  "GenMsgNrOfRepetition" 0;
BA_DEF_DEF_  "GenMsgPDUConstants" "";
BA_DEF_DEF_  "GenMsgSendType" "NoMsgSendType";
BA_DEF_DEF_  "GenMsgStartDelayTime" 0;
BA_DEF_DEF_  "NmMessage" "No";
BA_DEF_DEF_  "NmhMessage" "No";
BA_DEF_DEF_  "MsgType" "Application";
BA_DEF_DEF_  "VAGTP20_API" 0;
BA_DEF_DEF_  "VAGTP20_DynConnection" "No";
BA_DEF_DEF_  "VAGTP20_DynSetup" "No";
BA_DEF_DEF_  "VAGTP20_StatConnection" "No";
BA_DEF_DEF_  "GenSigActiveRepetitions" 0;
BA_DEF_DEF_  "GenSigInactiveValue" 0;
BA_DEF_DEF_  "GenSigSendType" "NoSigSendType";
BA_DEF_DEF_  "GenSigStartValue" 0;
BA_DEF_DEF_  "NWM-WakeupAllowed" "No";
BA_DEF_DEF_  "GenSigFuncType" "NoFunction";
BA_DEF_DEF_  "GenSigSwitchedByIgnition" "Yes";
BA_DEF_DEF_  "Fehlerwert" 0;
BA_DEF_DEF_  "GenSigMissingSourceValue" 0;
BA_ "GenMsgChkConstant" BO_ 1601 71;
BA_ "GenMsgCycleTime" BO_ 1601 1000;
BA_ "GenMsgILSupport" BO_ 1601 1;
BA_ "GenMsgPDUConstants" BO_ 1601 "0x47,0x47,0x47,0x47,0x47,0x47,0x47,0x47,0x47,0x47,0x47,0x47,0x47,0x47,0x47,0x47";
BA_ "GenMsgSendType" BO_ 1601 0;
BA_ "GenMsgCycleTime" BO_ 2600468499 200;
BA_ "NmhMessage" BO_ 2600468499 1;
BA_ "MsgType" BO_ 2600468499 2;
BA_ "GenMsgCycleTime" BO_ 2600468496 200;
BA_ "NmhMessage" BO_ 2600468496 1;
BA_ "MsgType" BO_ 2600468496 2;
BA_ "GenMsgCycleTime" BO_ 2600468498 200;
BA_ "NmhMessage" BO_ 2600468498 1;
BA_ "MsgType" BO_ 2600468498 2;
BA_ "GenMsgCycleTime" BO_ 2600468585 200;
BA_ "NmhMessage" BO_ 2600468585 1;
BA_ "MsgType" BO_ 2600468585 2;
BA_ "GenMsgCycleTime" BO_ 913 100;
BA_ "GenMsgILSupport" BO_ 913 1;
BA_ "GenMsgSendType" BO_ 913 0;
BA_ "MsgType" BO_ 2549875219 4;
BA_ "MsgType" BO_ 2550006291 4;
BA_ "MsgType" BO_ 2549875215 4;
BA_ "MsgType" BO_ 2550006287 4;
BA_ "MsgType" BO_ 2549875314 4;
BA_ "MsgType" BO_ 2550006386 4;
BA_ "MsgType" BO_ 2549875210 4;
BA_ "MsgType" BO_ 2550006282 4;
BA_ "MsgType" BO_ 2549875218 4;
BA_ "MsgType" BO_ 2550006290 4;
BA_ "MsgType" BO_ 2549875305 4;
BA_ "MsgType" BO_ 2550006377 4;
BA_ "GenMsgCycleTime" BO_ 1175 100;
BA_ "GenMsgDelayTime" BO_ 1175 50;
BA_ "GenMsgILSupport" BO_ 1175 1;
BA_ "GenMsgSendType" BO_ 1175 0;
BA_ "GenMsgCycleTimeFast" BO_ 1353 100;
BA_ "GenMsgILSupport" BO_ 1353 1;
BA_ "GenMsgSendType" BO_ 1353 7;
BA_ "GenMsgCycleTimeFast" BO_ 1354 100;
BA_ "GenMsgILSupport" BO_ 1354 1;
BA_ "GenMsgSendType" BO_ 1354 7;
BA_ "GenMsgCycleTime" BO_ 1355 500;
BA_ "GenMsgDelayTime" BO_ 1355 20;
BA_ "GenMsgILSupport" BO_ 1355 1;
BA_ "GenMsgSendType" BO_ 1355 0;
BA_ "GenMsgCycleTime" BO_ 1351 1000;
BA_ "GenMsgDelayTime" BO_ 1351 20;
BA_ "GenMsgILSupport" BO_ 1351 1;
BA_ "GenMsgSendType" BO_ 1351 0;
BA_ "GenMsgCycleTime" BO_ 2527679498 1000;
BA_ "GenMsgCycleTimeFast" BO_ 2527679498 200;
BA_ "GenMsgDelayTime" BO_ 2527679498 50;
BA_ "GenMsgILSupport" BO_ 2527679498 1;
BA_ "GenMsgNrOfRepetition" BO_ 2527679498 3;
BA_ "GenMsgSendType" BO_ 2527679498 0;
BA_ "GenMsgChkConstant" BO_ 304 49;
BA_ "GenMsgCycleTime" BO_ 304 1000;
BA_ "GenMsgCycleTimeFast" BO_ 304 20;
BA_ "GenMsgILSupport" BO_ 304 1;
BA_ "GenMsgNrOfRepetition" BO_ 304 5;
BA_ "GenMsgPDUConstants" BO_ 304 "0x31,0x31,0x31,0x31,0x31,0x31,0x31,0x31,0x31,0x31,0x31,0x31,0x31,0x31,0x31,0x31";
BA_ "GenMsgSendType" BO_ 304 0;
BA_ "GenMsgCycleTime" BO_ 1174 100;
BA_ "GenMsgILSupport" BO_ 1174 1;
BA_ "GenMsgSendType" BO_ 1174 0;
BA_ "GenMsgCycleTime" BO_ 1166 100;
BA_ "GenMsgILSupport" BO_ 1166 1;
BA_ "GenMsgSendType" BO_ 1166 0;
BA_ "GenMsgCycleTime" BO_ 695 50;
BA_ "GenMsgILSupport" BO_ 695 1;
BA_ "GenMsgPDUConstants" BO_ 695 "0x5e,0xc7,0x04,0x11,0x4d,0x27,0x0d,0x31,0x91,0xb8,0x62,0x76,0x64,0x09,0xeb,0xec";
BA_ "GenMsgSendType" BO_ 695 0;
BA_ "GenMsgCycleTime" BO_ 1711 1000;
BA_ "GenMsgDelayTime" BO_ 1711 100;
BA_ "GenMsgILSupport" BO_ 1711 1;
BA_ "GenMsgSendType" BO_ 1711 0;
BA_ "GenMsgCycleTime" BO_ 1610 500;
BA_ "GenMsgILSupport" BO_ 1610 1;
BA_ "GenMsgSendType" BO_ 1610 0;
BA_ "GenMsgCycleTime" BO_ 1710 1000;
BA_ "GenMsgDelayTime" BO_ 1710 50;
BA_ "GenMsgILSupport" BO_ 1710 1;
BA_ "GenMsgSendType" BO_ 1710 0;
BA_ "GenMsgCycleTime" BO_ 1413 1000;
BA_ "GenMsgDelayTime" BO_ 1413 10;
BA_ "GenMsgILSupport" BO_ 1413 1;
BA_ "GenMsgSendType" BO_ 1413 0;
BA_ "GenMsgCycleTime" BO_ 997 100;
BA_ "GenMsgDelayTime" BO_ 997 20;
BA_ "GenMsgILSupport" BO_ 997 1;
BA_ "GenMsgPDUConstants" BO_ 997 "0xc4,0x6a,0x69,0x30,0xcf,0x61,0x58,0x51,0x1b,0x86,0x99,0xd3,0xf6,0x1d,0x9a,0x37";
BA_ "GenMsgSendType" BO_ 997 0;
BA_ "GenMsgCycleTime" BO_ 288 20;
BA_ "GenMsgILSupport" BO_ 288 1;
BA_ "GenMsgPDUConstants" BO_ 288 "0xc4,0xe2,0x4f,0xe4,0xf8,0x2f,0x56,0x81,0x9f,0xe5,0x83,0x44,0x05,0x3f,0x97,0xdf";
BA_ "GenMsgSendType" BO_ 288 0;
BA_ "GenMsgCycleTime" BO_ 1716 200;
BA_ "GenMsgILSupport" BO_ 1716 1;
BA_ "GenMsgSendType" BO_ 1716 0;
BA_ "MsgType" BO_ 2617218560 6;
BA_ "MsgType" BO_ 2617218561 6;
BA_ "MsgType" BO_ 2617024000 6;
BA_ "MsgType" BO_ 2617024001 6;
BA_ "GenSigSendType" SG_ 1601 MO_Ansaugsystem 0;
BA_ "GenSigFuncType" SG_ 1601 MO_Ansaugsystem 8;
BA_ "GenSigSwitchedByIgnition" SG_ 1601 MO_Ansaugsystem 0;
BA_ "GenSigSendType" SG_ 1601 MO_Anzahl_Zyl 0;
BA_ "GenSigFuncType" SG_ 1601 MO_Anzahl_Zyl 8;
BA_ "GenSigSwitchedByIgnition" SG_ 1601 MO_Anzahl_Zyl 0;
BA_ "GenSigSendType" SG_ 1601 MO_Anzeige_StSt_gueltig 0;
BA_ "GenSigSwitchedByIgnition" SG_ 1601 MO_Anzeige_StSt_gueltig 0;
BA_ "GenSigSendType" SG_ 1601 MO_Code 0;
BA_ "GenSigFuncType" SG_ 1601 MO_Code 8;
BA_ "GenSigSwitchedByIgnition" SG_ 1601 MO_Code 0;
BA_ "GenSigSendType" SG_ 1601 MO_DPF_verbaut 0;
BA_ "GenSigFuncType" SG_ 1601 MO_DPF_verbaut 8;
BA_ "GenSigSwitchedByIgnition" SG_ 1601 MO_DPF_verbaut 0;
BA_ "GenSigSendType" SG_ 1601 MO_Faktor_Momente_02 0;
BA_ "GenSigFuncType" SG_ 1601 MO_Faktor_Momente_02 8;
BA_ "GenSigSwitchedByIgnition" SG_ 1601 MO_Faktor_Momente_02 0;
BA_ "GenSigSendType" SG_ 1601 MO_Getriebe_Code 0;
BA_ "GenSigFuncType" SG_ 1601 MO_Getriebe_Code 8;
BA_ "GenSigSwitchedByIgnition" SG_ 1601 MO_Getriebe_Code 0;
BA_ "GenSigSendType" SG_ 1601 MO_Hubraum 0;
BA_ "GenSigFuncType" SG_ 1601 MO_Hubraum 8;
BA_ "GenSigSwitchedByIgnition" SG_ 1601 MO_Hubraum 0;
BA_ "GenSigSendType" SG_ 1601 MO_Hybridfahrzeug 0;
BA_ "GenSigFuncType" SG_ 1601 MO_Hybridfahrzeug 8;
BA_ "GenSigSwitchedByIgnition" SG_ 1601 MO_Hybridfahrzeug 0;
BA_ "GenSigSendType" SG_ 1601 MO_Kraftstoffart 0;
BA_ "GenSigFuncType" SG_ 1601 MO_Kraftstoffart 8;
BA_ "GenSigSwitchedByIgnition" SG_ 1601 MO_Kraftstoffart 0;
BA_ "GenSigSendType" SG_ 1601 MO_Leistung 0;
BA_ "GenSigFuncType" SG_ 1601 MO_Leistung 8;
BA_ "GenSigSwitchedByIgnition" SG_ 1601 MO_Leistung 0;
BA_ "GenSigSendType" SG_ 1601 MO_OBD_Typ 0;
BA_ "GenSigFuncType" SG_ 1601 MO_OBD_Typ 8;
BA_ "GenSigSwitchedByIgnition" SG_ 1601 MO_OBD_Typ 0;
BA_ "GenSigSendType" SG_ 1601 MO_StartStopp_Codiert 0;
BA_ "GenSigFuncType" SG_ 1601 MO_StartStopp_Codiert 8;
BA_ "GenSigSwitchedByIgnition" SG_ 1601 MO_StartStopp_Codiert 0;
BA_ "GenSigSendType" SG_ 1601 Motor_Code_01_BZ 0;
BA_ "GenSigFuncType" SG_ 1601 Motor_Code_01_BZ 1;
BA_ "GenSigSwitchedByIgnition" SG_ 1601 Motor_Code_01_BZ 0;
BA_ "GenSigSendType" SG_ 1601 Motor_Code_01_CRC 0;
BA_ "GenSigFuncType" SG_ 1601 Motor_Code_01_CRC 2;
BA_ "GenSigSwitchedByIgnition" SG_ 1601 Motor_Code_01_CRC 0;
BA_ "GenSigSendType" SG_ 1601 TSK_Codierung 0;
BA_ "GenSigStartValue" SG_ 1601 TSK_Codierung 7;
BA_ "GenSigSwitchedByIgnition" SG_ 1601 TSK_Codierung 0;
BA_ "GenSigSwitchedByIgnition" SG_ 2600468499 NM_ABS_Car_Wakeup 0;
BA_ "GenSigSwitchedByIgnition" SG_ 2600468499 NM_ABS_NM_aktiv_Diagnose 0;
BA_ "GenSigSwitchedByIgnition" SG_ 2600468499 NM_ABS_NM_aktiv_KL15 0;
BA_ "GenSigSwitchedByIgnition" SG_ 2600468499 NM_ABS_NM_aktiv_Tmin 0;
BA_ "GenSigSwitchedByIgnition" SG_ 2600468499 NM_ABS_NM_aktiv_v_gr_0 0;
BA_ "GenSigSwitchedByIgnition" SG_ 2600468499 NM_ABS_NM_State 0;
BA_ "GenSigStartValue" SG_ 2600468499 NM_ABS_SNI 19;
BA_ "GenSigSwitchedByIgnition" SG_ 2600468499 NM_ABS_SNI 0;
BA_ "GenSigSwitchedByIgnition" SG_ 2600468499 NM_ABS_UDS_CC 0;
BA_ "NWM-WakeupAllowed" SG_ 2600468499 NM_ABS_Wakeup 1;
BA_ "GenSigSwitchedByIgnition" SG_ 2600468499 NM_ABS_Wakeup 0;
BA_ "GenSigSwitchedByIgnition" SG_ 2600468499 NM_ESP_NM_aktiv_Anzeige_EPB 0;
BA_ "GenSigSwitchedByIgnition" SG_ 2600468496 NM_Gateway_ACAN_Aktivitaet 0;
BA_ "GenSigSwitchedByIgnition" SG_ 2600468496 NM_Gateway_Bedien_LIN_Aktivitaet 0;
BA_ "GenSigSwitchedByIgnition" SG_ 2600468496 NM_Gateway_Car_Wakeup 0;
BA_ "GenSigSwitchedByIgnition" SG_ 2600468496 NM_Gateway_DiagCAN_Aktivitaet 0;
BA_ "GenSigSwitchedByIgnition" SG_ 2600468496 NM_Gateway_ECAN_Aktivitaet 0;
BA_ "GenSigSwitchedByIgnition" SG_ 2600468496 NM_Gateway_EM_Aktivitaet 0;
BA_ "GenSigSwitchedByIgnition" SG_ 2600468496 NM_Gateway_EnergieLIN_Aktivitaet 0;
BA_ "GenSigSwitchedByIgnition" SG_ 2600468496 NM_Gateway_FCAN_Aktivitaet 0;
BA_ "GenSigSwitchedByIgnition" SG_ 2600468496 NM_Gateway_HVEM_aktiv 0;
BA_ "GenSigSwitchedByIgnition" SG_ 2600468496 NM_Gateway_ICAN_Aktivitaet 0;
BA_ "GenSigSwitchedByIgnition" SG_ 2600468496 NM_Gateway_KCAN_Aktivitaet 0;
BA_ "GenSigSwitchedByIgnition" SG_ 2600468496 NM_Gateway_KS_Aktivitaet 0;
BA_ "GenSigSwitchedByIgnition" SG_ 2600468496 NM_Gateway_NL_EM 0;
BA_ "GenSigSwitchedByIgnition" SG_ 2600468496 NM_Gateway_NL_Shutdown 0;
BA_ "GenSigSwitchedByIgnition" SG_ 2600468496 NM_Gateway_NL_Spg_Messung 0;
BA_ "GenSigSwitchedByIgnition" SG_ 2600468496 NM_Gateway_NL_Wakeup_Monitor 0;
BA_ "GenSigSwitchedByIgnition" SG_ 2600468496 NM_Gateway_NM_aktiv_Diagnose 0;
BA_ "GenSigSwitchedByIgnition" SG_ 2600468496 NM_Gateway_NM_aktiv_KL15 0;
BA_ "GenSigSwitchedByIgnition" SG_ 2600468496 NM_Gateway_NM_aktiv_Tmin 0;
BA_ "GenSigSwitchedByIgnition" SG_ 2600468496 NM_Gateway_NM_State 0;
BA_ "GenSigStartValue" SG_ 2600468496 NM_Gateway_SNI 16;
BA_ "GenSigSwitchedByIgnition" SG_ 2600468496 NM_Gateway_SNI 0;
BA_ "GenSigSwitchedByIgnition" SG_ 2600468496 NM_Gateway_UDS_CC 0;
BA_ "NWM-WakeupAllowed" SG_ 2600468496 NM_Gateway_Wakeup 1;
BA_ "GenSigSwitchedByIgnition" SG_ 2600468496 NM_Gateway_Wakeup 0;
BA_ "GenSigSwitchedByIgnition" SG_ 2600468498 NM_Lenkhilfe_Car_Wakeup 0;
BA_ "GenSigSwitchedByIgnition" SG_ 2600468498 NM_Lenkhilfe_NM_aktiv_Diagnose 0;
BA_ "GenSigSwitchedByIgnition" SG_ 2600468498 NM_Lenkhilfe_NM_aktiv_DZ_gr_300 0;
BA_ "GenSigSwitchedByIgnition" SG_ 2600468498 NM_Lenkhilfe_NM_aktiv_Fahrbereit 0;
BA_ "GenSigSwitchedByIgnition" SG_ 2600468498 NM_Lenkhilfe_NM_aktiv_Handlenkmo 0;
BA_ "GenSigSwitchedByIgnition" SG_ 2600468498 NM_Lenkhilfe_NM_aktiv_KL15 0;
BA_ "GenSigSwitchedByIgnition" SG_ 2600468498 NM_Lenkhilfe_NM_aktiv_Post_Run 0;
BA_ "GenSigSwitchedByIgnition" SG_ 2600468498 NM_Lenkhilfe_NM_aktiv_Tmin 0;
BA_ "GenSigSwitchedByIgnition" SG_ 2600468498 NM_Lenkhilfe_NM_aktiv_v_gr_7 0;
BA_ "GenSigSwitchedByIgnition" SG_ 2600468498 NM_Lenkhilfe_NM_State 0;
BA_ "GenSigStartValue" SG_ 2600468498 NM_Lenkhilfe_SNI 18;
BA_ "GenSigSwitchedByIgnition" SG_ 2600468498 NM_Lenkhilfe_SNI 0;
BA_ "GenSigSwitchedByIgnition" SG_ 2600468498 NM_Lenkhilfe_UDS_CC 0;
BA_ "NWM-WakeupAllowed" SG_ 2600468498 NM_Lenkhilfe_Wakeup 1;
BA_ "GenSigSwitchedByIgnition" SG_ 2600468498 NM_Lenkhilfe_Wakeup 0;
BA_ "GenSigSwitchedByIgnition" SG_ 2600468585 NM_Rearview_Car_Wakeup 0;
BA_ "GenSigSwitchedByIgnition" SG_ 2600468585 NM_Rearview_NM_aktiv_Diagnose 0;
BA_ "GenSigSwitchedByIgnition" SG_ 2600468585 NM_Rearview_NM_aktiv_KL15 0;
BA_ "GenSigSwitchedByIgnition" SG_ 2600468585 NM_Rearview_NM_aktiv_Tmin 0;
BA_ "GenSigSwitchedByIgnition" SG_ 2600468585 NM_Rearview_NM_State 0;
BA_ "GenSigStartValue" SG_ 2600468585 NM_Rearview_SNI 105;
BA_ "GenSigSwitchedByIgnition" SG_ 2600468585 NM_Rearview_SNI 0;
BA_ "GenSigSwitchedByIgnition" SG_ 2600468585 NM_Rearview_UDS_CC 0;
BA_ "NWM-WakeupAllowed" SG_ 2600468585 NM_Rearview_Wakeup 1;
BA_ "GenSigSwitchedByIgnition" SG_ 2600468585 NM_Rearview_Wakeup 0;
BA_ "GenSigSendType" SG_ 913 MO_QBit_Aussen_Temp 0;
BA_ "GenSigStartValue" SG_ 913 MO_QBit_Aussen_Temp 1;
BA_ "GenSigSwitchedByIgnition" SG_ 913 MO_QBit_Aussen_Temp 0;
BA_ "GenSigSendType" SG_ 913 MO_Servicemodus 0;
BA_ "GenSigSwitchedByIgnition" SG_ 913 MO_Servicemodus 0;
BA_ "GenSigSendType" SG_ 913 OBD_Abs_Load_Val 0;
BA_ "GenSigStartValue" SG_ 913 OBD_Abs_Load_Val 65535;
BA_ "GenSigSwitchedByIgnition" SG_ 913 OBD_Abs_Load_Val 0;
BA_ "GenSigSendType" SG_ 913 OBD_Abs_Pedal_Pos 0;
BA_ "GenSigStartValue" SG_ 913 OBD_Abs_Pedal_Pos 255;
BA_ "GenSigSwitchedByIgnition" SG_ 913 OBD_Abs_Pedal_Pos 0;
BA_ "GenSigSendType" SG_ 913 OBD_Abs_Throttle_Pos 0;
BA_ "GenSigStartValue" SG_ 913 OBD_Abs_Throttle_Pos 255;
BA_ "GenSigSwitchedByIgnition" SG_ 913 OBD_Abs_Throttle_Pos 0;
BA_ "GenSigSendType" SG_ 913 OBD_Calc_Load_Val 0;
BA_ "GenSigStartValue" SG_ 913 OBD_Calc_Load_Val 255;
BA_ "GenSigSwitchedByIgnition" SG_ 913 OBD_Calc_Load_Val 0;
BA_ "GenSigSendType" SG_ 913 OBD_Driving_Cycle 0;
BA_ "GenSigSwitchedByIgnition" SG_ 913 OBD_Driving_Cycle 0;
BA_ "GenSigSendType" SG_ 913 OBD_Eng_Cool_Temp 0;
BA_ "GenSigStartValue" SG_ 913 OBD_Eng_Cool_Temp 255;
BA_ "GenSigSwitchedByIgnition" SG_ 913 OBD_Eng_Cool_Temp 0;
BA_ "GenSigSendType" SG_ 913 OBD_Kaltstart_Denominator 0;
BA_ "GenSigSwitchedByIgnition" SG_ 913 OBD_Kaltstart_Denominator 0;
BA_ "GenSigSendType" SG_ 913 OBD_Minimum_Trip 0;
BA_ "GenSigSwitchedByIgnition" SG_ 913 OBD_Minimum_Trip 0;
BA_ "GenSigSendType" SG_ 913 OBD_Normed_Trip 0;
BA_ "GenSigSwitchedByIgnition" SG_ 913 OBD_Normed_Trip 0;
BA_ "GenSigSendType" SG_ 913 OBD_Sperrung_IUMPR 0;
BA_ "GenSigSwitchedByIgnition" SG_ 913 OBD_Sperrung_IUMPR 0;
BA_ "GenSigSendType" SG_ 913 OBD_Warm_Up_Cycle 0;
BA_ "GenSigSwitchedByIgnition" SG_ 913 OBD_Warm_Up_Cycle 0;
BA_ "GenSigSendType" SG_ 2549875219 OBDC_ABS_Req_Data 3;
BA_ "GenSigFuncType" SG_ 2549875219 OBDC_ABS_Req_Data 9;
BA_ "GenSigSwitchedByIgnition" SG_ 2549875219 OBDC_ABS_Req_Data 0;
BA_ "GenSigSendType" SG_ 2550006291 OBDC_ABS_Resp_Data 3;
BA_ "GenSigFuncType" SG_ 2550006291 OBDC_ABS_Resp_Data 9;
BA_ "GenSigSwitchedByIgnition" SG_ 2550006291 OBDC_ABS_Resp_Data 0;
BA_ "GenSigSendType" SG_ 2549875215 OBDC_Allrad_Req_Data 3;
BA_ "GenSigFuncType" SG_ 2549875215 OBDC_Allrad_Req_Data 9;
BA_ "GenSigSwitchedByIgnition" SG_ 2549875215 OBDC_Allrad_Req_Data 0;
BA_ "GenSigSendType" SG_ 2550006287 OBDC_Allrad_Resp_Data 3;
BA_ "GenSigFuncType" SG_ 2550006287 OBDC_Allrad_Resp_Data 9;
BA_ "GenSigSendType" SG_ 2549875314 OBDC_Daempfer_Req_Data 3;
BA_ "GenSigFuncType" SG_ 2549875314 OBDC_Daempfer_Req_Data 9;
BA_ "GenSigSwitchedByIgnition" SG_ 2549875314 OBDC_Daempfer_Req_Data 0;
BA_ "GenSigSendType" SG_ 2550006386 OBDC_Daempfer_Resp_Data 3;
BA_ "GenSigFuncType" SG_ 2550006386 OBDC_Daempfer_Resp_Data 9;
BA_ "GenSigSendType" SG_ 2549875210 OBDC_EPH_Req_Data 3;
BA_ "GenSigFuncType" SG_ 2549875210 OBDC_EPH_Req_Data 9;
BA_ "GenSigSwitchedByIgnition" SG_ 2549875210 OBDC_EPH_Req_Data 0;
BA_ "GenSigSendType" SG_ 2550006282 OBDC_EPH_Resp_Data 3;
BA_ "GenSigFuncType" SG_ 2550006282 OBDC_EPH_Resp_Data 9;
BA_ "GenSigSendType" SG_ 2549875218 OBDC_Lenkhilfe_Req_Data 3;
BA_ "GenSigFuncType" SG_ 2549875218 OBDC_Lenkhilfe_Req_Data 9;
BA_ "GenSigSwitchedByIgnition" SG_ 2549875218 OBDC_Lenkhilfe_Req_Data 0;
BA_ "GenSigSendType" SG_ 2550006290 OBDC_Lenkhilfe_Resp_Data 3;
BA_ "GenSigFuncType" SG_ 2550006290 OBDC_Lenkhilfe_Resp_Data 9;
BA_ "GenSigSwitchedByIgnition" SG_ 2550006290 OBDC_Lenkhilfe_Resp_Data 0;
BA_ "GenSigSendType" SG_ 2549875305 OBDC_Rearview_Req_Data 3;
BA_ "GenSigSwitchedByIgnition" SG_ 2549875305 OBDC_Rearview_Req_Data 0;
BA_ "GenSigSendType" SG_ 2550006377 OBDC_Rearview_Resp_Data 3;
BA_ "GenSigSwitchedByIgnition" SG_ 2550006377 OBDC_Rearview_Resp_Data 0;
BA_ "GenSigSendType" SG_ 1175 PDC_Tonausgabe_Front 3;
BA_ "GenSigSendType" SG_ 1175 PDC_Tonausgabe_Heck 3;
BA_ "GenSigSendType" SG_ 1175 PH_Abschaltursache 3;
BA_ "GenSigSendType" SG_ 1175 PH_Anf_Audioabsenkung 3;
BA_ "GenSigSendType" SG_ 1175 PH_Anf_Verdeck 3;
BA_ "GenSigSendType" SG_ 1175 PH_defekt 3;
BA_ "GenSigSendType" SG_ 1175 PH_Display_Kundenwunsch 3;
BA_ "GenSigSendType" SG_ 1175 PH_Frequenz_hinten 3;
BA_ "GenSigSendType" SG_ 1175 PH_Frequenz_vorn 3;
BA_ "GenSigSendType" SG_ 1175 PH_gestoert 3;
BA_ "GenSigSendType" SG_ 1175 PH_Lautstaerke_hinten 3;
BA_ "GenSigSendType" SG_ 1175 PH_Lautstaerke_vorn 3;
BA_ "GenSigSendType" SG_ 1175 PH_nachtr_Stopp_Anf 3;
BA_ "GenSigSendType" SG_ 1175 PH_Opt_Anz_H_Hindernis 3;
BA_ "GenSigSendType" SG_ 1175 PH_Opt_Anz_V_Hindernis 3;
BA_ "GenSigSendType" SG_ 1175 PH_Opt_Anzeige_H_ein 3;
BA_ "GenSigSendType" SG_ 1175 PH_Opt_Anzeige_V_ein 3;
BA_ "GenSigSendType" SG_ 1175 PH_StartStopp_Info 3;
BA_ "GenSigSendType" SG_ 1175 PH_Stoermeldung 3;
BA_ "GenSigSendType" SG_ 1175 PH_Systemzustand 3;
BA_ "GenSigSendType" SG_ 1175 PH_Taster 3;
BA_ "Fehlerwert" SG_ 1175 PH_Taster 3;
BA_ "GenSigSendType" SG_ 1175 PH_Tongeber_H_aktiv 3;
BA_ "GenSigSendType" SG_ 1175 PH_Tongeber_H_verfuegbar 3;
BA_ "GenSigSendType" SG_ 1175 PH_Tongeber_mute 3;
BA_ "GenSigSendType" SG_ 1175 PH_Tongeber_V_aktiv 3;
BA_ "GenSigSendType" SG_ 1175 PH_Visualisierung 3;
BA_ "GenSigStartValue" SG_ 1175 PH_Visualisierung 6;
BA_ "Fehlerwert" SG_ 1175 PH_Visualisierung 7;
BA_ "GenSigSendType" SG_ 1175 PLA_Anf_Aufschaltung_RVC 3;
BA_ "GenSigSendType" SG_ 1355 PDC_Charisma_FahrPr 3;
BA_ "GenSigSendType" SG_ 1355 PDC_Charisma_Status 3;
BA_ "GenSigSendType" SG_ 1355 PH_Aufschaltursache 3;
BA_ "GenSigSendType" SG_ 1355 PH_Verschmutzungsmeldung 3;
BA_ "GenSigSendType" SG_ 1351 US_Objekt_links 3;
BA_ "GenSigSendType" SG_ 1351 US_Objekt_rechts 3;
BA_ "GenSigSendType" SG_ 1351 US_Objektueberwachung_Status 3;
BA_ "Fehlerwert" SG_ 1351 US_Objektueberwachung_Status 3;
BA_ "GenSigSendType" SG_ 2527679498 Perso_Aktiv 4;
BA_ "GenSigSwitchedByIgnition" SG_ 2527679498 Perso_Aktiv 0;
BA_ "GenSigSendType" SG_ 2527679498 Perso_Bedienstelle 4;
BA_ "GenSigSwitchedByIgnition" SG_ 2527679498 Perso_Bedienstelle 0;
BA_ "GenSigSendType" SG_ 2527679498 Perso_Freigabe_Verstellung 4;
BA_ "GenSigSwitchedByIgnition" SG_ 2527679498 Perso_Freigabe_Verstellung 0;
BA_ "GenSigSendType" SG_ 2527679498 Perso_Kontonummer 4;
BA_ "GenSigSwitchedByIgnition" SG_ 2527679498 Perso_Kontonummer 0;
BA_ "GenSigSendType" SG_ 2527679498 Perso_Status 1;
BA_ "GenSigSwitchedByIgnition" SG_ 2527679498 Perso_Status 0;
BA_ "GenSigSendType" SG_ 2527679498 Perso_Steuerung 4;
BA_ "GenSigSwitchedByIgnition" SG_ 2527679498 Perso_Steuerung 0;
BA_ "GenSigSendType" SG_ 2527679498 Perso_Steuerungsparameter 4;
BA_ "GenSigSwitchedByIgnition" SG_ 2527679498 Perso_Steuerungsparameter 0;
BA_ "GenSigSendType" SG_ 304 PLA_01_BZ 0;
BA_ "GenSigFuncType" SG_ 304 PLA_01_BZ 1;
BA_ "GenSigSendType" SG_ 304 PLA_01_CRC 0;
BA_ "GenSigFuncType" SG_ 304 PLA_01_CRC 2;
BA_ "GenSigSendType" SG_ 304 PLA_01_Signal_red_cyclic 6;
BA_ "GenSigSendType" SG_ 304 PLA_Anhalten 0;
BA_ "GenSigSendType" SG_ 304 PLA_Anhalteweg 0;
BA_ "GenSigStartValue" SG_ 304 PLA_Anhalteweg 2046;
BA_ "Fehlerwert" SG_ 304 PLA_Anhalteweg 2047;
BA_ "GenSigSendType" SG_ 304 PLA_BremsMom_Verzoeg 0;
BA_ "Fehlerwert" SG_ 304 PLA_Bremsmoment 8191;
BA_ "GenSigStartValue" SG_ 304 PLA_Bremsverzoegerung 126;
BA_ "Fehlerwert" SG_ 304 PLA_Bremsverzoegerung 127;
BA_ "GenSigSendType" SG_ 304 PLA_LW_Soll 0;
BA_ "GenSigSendType" SG_ 304 PLA_Status_PLA_EPS 0;
BA_ "GenSigStartValue" SG_ 304 PLA_Status_PLA_EPS 9;
BA_ "GenSigSendType" SG_ 304 PLA_Status_PLA_ESP 0;
BA_ "GenSigStartValue" SG_ 304 PLA_Status_PLA_ESP 9;
BA_ "GenSigSendType" SG_ 304 PLA_VZ_LW_Soll 0;
BA_ "GenSigSendType" SG_ 1174 PLS_Akustik 0;
BA_ "GenSigSendType" SG_ 1174 PLS_Anf_Anz 0;
BA_ "GenSigSendType" SG_ 1174 PLS_Anf_Anz_Schwellpfeil 0;
BA_ "GenSigSendType" SG_ 1174 PLS_Ausparken_Aktiv 0;
BA_ "GenSigSendType" SG_ 1174 PLS_Bremsleuchte 0;
BA_ "GenSigSendType" SG_ 1174 PLS_Bremssymbol 0;
BA_ "GenSigSendType" SG_ 1174 PLS_Fahrtrichtg_Mehrzg 0;
BA_ "GenSigSendType" SG_ 1174 PLS_Kurze_Luecke 0;
BA_ "GenSigSendType" SG_ 1174 PLS_Laengs_Querluecke 0;
BA_ "GenSigSendType" SG_ 1174 PLS_Lenk_Aktiv_Hinweis 0;
BA_ "GenSigSendType" SG_ 1174 PLS_Mehrzg_Aktiv 0;
BA_ "GenSigSendType" SG_ 1174 PLS_PL_Exist 0;
BA_ "GenSigSendType" SG_ 1174 PLS_PL_Seite 0;
BA_ "GenSigSendType" SG_ 1174 PLS_Pos_OK 0;
BA_ "GenSigSendType" SG_ 1174 PLS_Schwellpfeil_abs 0;
BA_ "GenSigSendType" SG_ 1174 PLS_Schwellpfeil_rel 0;
BA_ "GenSigSendType" SG_ 1174 PLS_Standby 0;
BA_ "GenSigSendType" SG_ 1174 PLS_Texte 0;
BA_ "GenSigSendType" SG_ 1166 PLA_Anf_Akustik 0;
BA_ "GenSigSendType" SG_ 1166 PLA_Anf_Anzeige_Bremsfuss 0;
BA_ "GenSigSendType" SG_ 1166 PLA_Anf_Anzeige_Mini 0;
BA_ "GenSigSendType" SG_ 1166 PLA_Anf_Anzeige_Schwellpfeil 0;
BA_ "GenSigSendType" SG_ 1166 PLA_Anf_Anzeigemodus 0;
BA_ "GenSigSendType" SG_ 1166 PLA_Anf_Funktionsdisclaimer 0;
BA_ "GenSigSendType" SG_ 1166 PLA_Anf_Meldungen 0;
BA_ "GenSigSendType" SG_ 1166 PLA_Anzahl_Segmente_Schwellpfeil 0;
BA_ "GenSigSendType" SG_ 1166 PLA_Mini_Modus 0;
BA_ "GenSigSendType" SG_ 1166 PLA_Status_Aktive_Seite 0;
BA_ "GenSigSendType" SG_ 1166 PLA_Status_beenden_Mini 0;
BA_ "GenSigSendType" SG_ 1166 PLA_Status_Funktion 0;
BA_ "GenSigSendType" SG_ 1166 PLA_Status_Laengsparken_Mini 0;
BA_ "GenSigSendType" SG_ 1166 PLA_Status_QP_Rueckw_Mini 0;
BA_ "GenSigSendType" SG_ 1166 PLA_Status_QP_Vorw_Mini 0;
BA_ "GenSigSendType" SG_ 695 RCTA_01_BZ 0;
BA_ "GenSigFuncType" SG_ 695 RCTA_01_BZ 1;
BA_ "GenSigSendType" SG_ 695 RCTA_01_CRC 0;
BA_ "GenSigFuncType" SG_ 695 RCTA_01_CRC 2;
BA_ "GenSigSendType" SG_ 695 RCTA_Anforderung_HMS 0;
BA_ "GenSigSendType" SG_ 695 RCTA_Bremsruck_Anforderung 0;
BA_ "GenSigSendType" SG_ 695 RCTA_Bremsruck_Freigabe 0;
BA_ "GenSigSendType" SG_ 695 RCTA_Info_links 0;
BA_ "GenSigSendType" SG_ 695 RCTA_Info_rechts 0;
BA_ "GenSigSendType" SG_ 695 RCTA_Kritikalitaetslevel_links 0;
BA_ "GenSigSendType" SG_ 695 RCTA_Kritikalitaetslevel_rechts 0;
BA_ "GenSigSendType" SG_ 695 RCTA_Modus 0;
BA_ "GenSigSendType" SG_ 695 RCTA_Notbremsung_Anforderung 0;
BA_ "Fehlerwert" SG_ 695 RCTA_Notbremsung_Anforderung 255;
BA_ "GenSigSendType" SG_ 695 RCTA_Notbremsung_Freigabe 0;
BA_ "GenSigSendType" SG_ 695 RCTA_Status 0;
BA_ "Fehlerwert" SG_ 695 RCTA_Status 3;
BA_ "GenSigSendType" SG_ 695 RCTA_Warnton 0;
BA_ "GenSigSendType" SG_ 1711 RV_Calib_Fehler 3;
BA_ "GenSigSwitchedByIgnition" SG_ 1711 RV_Calib_Fehler 0;
BA_ "GenSigSendType" SG_ 1711 RV_Dark_Screen 3;
BA_ "GenSigSwitchedByIgnition" SG_ 1711 RV_Dark_Screen 0;
BA_ "GenSigSendType" SG_ 1711 RV_Farbe 3;
BA_ "GenSigSwitchedByIgnition" SG_ 1711 RV_Farbe 0;
BA_ "GenSigSendType" SG_ 1711 RV_GL_LWS_Fehler 3;
BA_ "GenSigSwitchedByIgnition" SG_ 1711 RV_GL_LWS_Fehler 0;
BA_ "GenSigSendType" SG_ 1711 RV_GL_side 3;
BA_ "GenSigSendType" SG_ 1711 RV_GL_Trailer_connect 3;
BA_ "GenSigSwitchedByIgnition" SG_ 1711 RV_GL_Trailer_connect 0;
BA_ "GenSigSendType" SG_ 1711 RV_GL_Trunk_open 3;
BA_ "GenSigSwitchedByIgnition" SG_ 1711 RV_GL_Trunk_open 0;
BA_ "GenSigSendType" SG_ 1711 RV_Helligkeit 3;
BA_ "GenSigSwitchedByIgnition" SG_ 1711 RV_Helligkeit 0;
BA_ "GenSigSendType" SG_ 1711 RV_HMI_Mode 3;
BA_ "GenSigSwitchedByIgnition" SG_ 1711 RV_HMI_Mode 0;
BA_ "GenSigSendType" SG_ 1711 RV_Kontrast 3;
BA_ "GenSigSwitchedByIgnition" SG_ 1711 RV_Kontrast 0;
BA_ "GenSigSendType" SG_ 1711 RV_Menu_Item 3;
BA_ "GenSigSwitchedByIgnition" SG_ 1711 RV_Menu_Item 0;
BA_ "GenSigSendType" SG_ 1711 RV_Reinigung_Anf 3;
BA_ "GenSigSwitchedByIgnition" SG_ 1711 RV_Reinigung_Anf 0;
BA_ "GenSigSendType" SG_ 1711 RV_Settings_enabled 3;
BA_ "GenSigSwitchedByIgnition" SG_ 1711 RV_Settings_enabled 0;
BA_ "GenSigSendType" SG_ 1711 RV_System_aktiv 3;
BA_ "GenSigSwitchedByIgnition" SG_ 1711 RV_System_aktiv 0;
BA_ "GenSigSendType" SG_ 1711 RV_Video_on 3;
BA_ "GenSigSwitchedByIgnition" SG_ 1711 RV_Video_on 0;
BA_ "GenSigSendType" SG_ 1711 SV_Video_on 3;
BA_ "GenSigSendType" SG_ 1610 RKA_Druckwarnung_RdW 0;
BA_ "GenSigSwitchedByIgnition" SG_ 1610 RKA_Druckwarnung_RdW 0;
BA_ "GenSigSendType" SG_ 1610 RKA_FMVSS138_Lampe 0;
BA_ "GenSigSwitchedByIgnition" SG_ 1610 RKA_FMVSS138_Lampe 0;
BA_ "GenSigSendType" SG_ 1610 RKA_FMVSS138_MIL 0;
BA_ "GenSigSwitchedByIgnition" SG_ 1610 RKA_FMVSS138_MIL 0;
BA_ "GenSigSendType" SG_ 1610 RKA_KD_Fehler 0;
BA_ "GenSigSwitchedByIgnition" SG_ 1610 RKA_KD_Fehler 0;
BA_ "GenSigSendType" SG_ 1610 RKA_Warnungen 0;
BA_ "GenSigSwitchedByIgnition" SG_ 1610 RKA_Warnungen 0;
BA_ "GenSigSendType" SG_ 1610 RKA_Warnungen_02 0;
BA_ "GenSigSwitchedByIgnition" SG_ 1610 RKA_Warnungen_02 0;
BA_ "GenSigSendType" SG_ 1710 SP_abklappen 3;
BA_ "GenSigSwitchedByIgnition" SG_ 1710 SP_abklappen 0;
BA_ "GenSigSendType" SG_ 1710 SP_anklappen 3;
BA_ "GenSigSwitchedByIgnition" SG_ 1710 SP_anklappen 0;
BA_ "GenSigSendType" SG_ 1710 SP_ARA_Status 0;
BA_ "GenSigSendType" SG_ 1710 SP_Auswahl_li 3;
BA_ "GenSigSwitchedByIgnition" SG_ 1710 SP_Auswahl_li 0;
BA_ "GenSigSendType" SG_ 1710 SP_Auswahl_re 3;
BA_ "GenSigSwitchedByIgnition" SG_ 1710 SP_Auswahl_re 0;
BA_ "GenSigSendType" SG_ 1710 SP_BT_links 3;
BA_ "GenSigSwitchedByIgnition" SG_ 1710 SP_BT_links 0;
BA_ "GenSigSendType" SG_ 1710 SP_BT_oben 3;
BA_ "GenSigSwitchedByIgnition" SG_ 1710 SP_BT_oben 0;
BA_ "GenSigSendType" SG_ 1710 SP_BT_rechts 3;
BA_ "GenSigSwitchedByIgnition" SG_ 1710 SP_BT_rechts 0;
BA_ "GenSigSendType" SG_ 1710 SP_BT_unten 3;
BA_ "GenSigSwitchedByIgnition" SG_ 1710 SP_BT_unten 0;
BA_ "GenSigSendType" SG_ 1710 SP_FT_links 3;
BA_ "GenSigSwitchedByIgnition" SG_ 1710 SP_FT_links 0;
BA_ "GenSigSendType" SG_ 1710 SP_FT_oben 3;
BA_ "GenSigSwitchedByIgnition" SG_ 1710 SP_FT_oben 0;
BA_ "GenSigSendType" SG_ 1710 SP_FT_rechts 3;
BA_ "GenSigSwitchedByIgnition" SG_ 1710 SP_FT_rechts 0;
BA_ "GenSigSendType" SG_ 1710 SP_FT_unten 3;
BA_ "GenSigSwitchedByIgnition" SG_ 1710 SP_FT_unten 0;
BA_ "GenSigSendType" SG_ 1710 SP_Hzg_Taster 3;
BA_ "GenSigSwitchedByIgnition" SG_ 1710 SP_Hzg_Taster 0;
BA_ "GenSigSendType" SG_ 1710 SP_normieren 3;
BA_ "GenSigSwitchedByIgnition" SG_ 1710 SP_normieren 0;
BA_ "GenSigSendType" SG_ 1710 SP_S_Klappen 3;
BA_ "GenSigSwitchedByIgnition" SG_ 1710 SP_S_Klappen 0;
BA_ "GenSigSendType" SG_ 1710 SP_S_links 3;
BA_ "GenSigSwitchedByIgnition" SG_ 1710 SP_S_links 0;
BA_ "GenSigSendType" SG_ 1710 SP_S_oben 3;
BA_ "GenSigSwitchedByIgnition" SG_ 1710 SP_S_oben 0;
BA_ "GenSigSendType" SG_ 1710 SP_S_rechts 3;
BA_ "GenSigSwitchedByIgnition" SG_ 1710 SP_S_rechts 0;
BA_ "GenSigSendType" SG_ 1710 SP_S_unten 3;
BA_ "GenSigSwitchedByIgnition" SG_ 1710 SP_S_unten 0;
BA_ "GenSigSendType" SG_ 1710 SP_Spg_Verstellschalter_Fehler 0;
BA_ "Fehlerwert" SG_ 1710 SP_Spg_Verstellschalter_Fehler 1;
BA_ "GenSigSendType" SG_ 1413 GW_KD_Fehler 3;
BA_ "GenSigSendType" SG_ 1413 SI_BUS_01 3;
BA_ "GenSigStartValue" SG_ 1413 SI_BUS_01 1;
BA_ "GenSigSwitchedByIgnition" SG_ 1413 SI_BUS_01 0;
BA_ "GenSigSendType" SG_ 1413 SI_BUS_02 3;
BA_ "GenSigStartValue" SG_ 1413 SI_BUS_02 1;
BA_ "GenSigSwitchedByIgnition" SG_ 1413 SI_BUS_02 0;
BA_ "GenSigSendType" SG_ 1413 SI_BUS_03 3;
BA_ "GenSigStartValue" SG_ 1413 SI_BUS_03 1;
BA_ "GenSigSwitchedByIgnition" SG_ 1413 SI_BUS_03 0;
BA_ "GenSigSendType" SG_ 1413 SI_BUS_04 3;
BA_ "GenSigStartValue" SG_ 1413 SI_BUS_04 1;
BA_ "GenSigSwitchedByIgnition" SG_ 1413 SI_BUS_04 0;
BA_ "GenSigSendType" SG_ 1413 SI_BUS_05 3;
BA_ "GenSigStartValue" SG_ 1413 SI_BUS_05 1;
BA_ "GenSigSwitchedByIgnition" SG_ 1413 SI_BUS_05 0;
BA_ "GenSigSendType" SG_ 1413 SI_BUS_06 3;
BA_ "GenSigStartValue" SG_ 1413 SI_BUS_06 1;
BA_ "GenSigSwitchedByIgnition" SG_ 1413 SI_BUS_06 0;
BA_ "GenSigSendType" SG_ 1413 SI_BUS_07 3;
BA_ "GenSigStartValue" SG_ 1413 SI_BUS_07 1;
BA_ "GenSigSwitchedByIgnition" SG_ 1413 SI_BUS_07 0;
BA_ "GenSigSendType" SG_ 1413 SI_BUS_08 3;
BA_ "GenSigStartValue" SG_ 1413 SI_BUS_08 1;
BA_ "GenSigSwitchedByIgnition" SG_ 1413 SI_BUS_08 0;
BA_ "GenSigSendType" SG_ 1413 SI_BUS_09 3;
BA_ "GenSigStartValue" SG_ 1413 SI_BUS_09 1;
BA_ "GenSigSwitchedByIgnition" SG_ 1413 SI_BUS_09 0;
BA_ "GenSigSendType" SG_ 1413 SI_BUS_10 3;
BA_ "GenSigStartValue" SG_ 1413 SI_BUS_10 1;
BA_ "GenSigSwitchedByIgnition" SG_ 1413 SI_BUS_10 0;
BA_ "GenSigSendType" SG_ 1413 SI_BUS_11 3;
BA_ "GenSigStartValue" SG_ 1413 SI_BUS_11 1;
BA_ "GenSigSwitchedByIgnition" SG_ 1413 SI_BUS_11 0;
BA_ "GenSigSendType" SG_ 1413 SI_BUS_12 3;
BA_ "GenSigStartValue" SG_ 1413 SI_BUS_12 1;
BA_ "GenSigSwitchedByIgnition" SG_ 1413 SI_BUS_12 0;
BA_ "GenSigSendType" SG_ 1413 SI_BUS_13 3;
BA_ "GenSigStartValue" SG_ 1413 SI_BUS_13 1;
BA_ "GenSigSwitchedByIgnition" SG_ 1413 SI_BUS_13 0;
BA_ "GenSigSendType" SG_ 1413 SI_BUS_14 3;
BA_ "GenSigStartValue" SG_ 1413 SI_BUS_14 1;
BA_ "GenSigSwitchedByIgnition" SG_ 1413 SI_BUS_14 0;
BA_ "GenSigSendType" SG_ 1413 SI_BUS_15 3;
BA_ "GenSigStartValue" SG_ 1413 SI_BUS_15 1;
BA_ "GenSigSwitchedByIgnition" SG_ 1413 SI_BUS_15 0;
BA_ "GenSigSendType" SG_ 1413 SI_Bus_Identifikation 0;
BA_ "GenSigFuncType" SG_ 1413 SI_Bus_Identifikation 8;
BA_ "GenSigSwitchedByIgnition" SG_ 1413 SI_Bus_Identifikation 0;
BA_ "GenSigSendType" SG_ 1413 SI_Diagnose_Aktiv 3;
BA_ "GenSigSwitchedByIgnition" SG_ 1413 SI_Diagnose_Aktiv 0;
BA_ "GenSigSendType" SG_ 1413 SI_NWDF 3;
BA_ "GenSigSwitchedByIgnition" SG_ 1413 SI_NWDF 0;
BA_ "GenSigSendType" SG_ 1413 SI_NWDF_gueltig 3;
BA_ "GenSigFuncType" SG_ 1413 SI_NWDF_gueltig 8;
BA_ "GenSigSwitchedByIgnition" SG_ 1413 SI_NWDF_gueltig 0;
BA_ "GenSigSendType" SG_ 1413 SI_QRS_Mode 3;
BA_ "GenSigSwitchedByIgnition" SG_ 1413 SI_QRS_Mode 0;
BA_ "GenSigSendType" SG_ 1413 SI_Sammel_SG_Fehler 0;
BA_ "GenSigStartValue" SG_ 1413 SI_Sammel_SG_Fehler 63;
BA_ "GenSigSwitchedByIgnition" SG_ 1413 SI_Sammel_SG_Fehler 0;
BA_ "GenSigSendType" SG_ 1413 SI_Sammelfehler 3;
BA_ "GenSigSwitchedByIgnition" SG_ 1413 SI_Sammelfehler 0;
BA_ "GenSigSendType" SG_ 1413 SI_T_Mode 3;
BA_ "GenSigSwitchedByIgnition" SG_ 1413 SI_T_Mode 0;
BA_ "GenSigSendType" SG_ 1413 SI_T_Schutz 3;
BA_ "GenSigSwitchedByIgnition" SG_ 1413 SI_T_Schutz 0;
BA_ "GenSigSendType" SG_ 997 FT_BFS_Tuer_Status 3;
BA_ "GenSigSwitchedByIgnition" SG_ 997 FT_BFS_Tuer_Status 0;
BA_ "Fehlerwert" SG_ 997 FT_BFS_Tuer_Status 3;
BA_ "GenSigSendType" SG_ 997 FT_HBFS_Tuer_Status 3;
BA_ "GenSigSwitchedByIgnition" SG_ 997 FT_HBFS_Tuer_Status 0;
BA_ "Fehlerwert" SG_ 997 FT_HBFS_Tuer_Status 3;
BA_ "GenSigSendType" SG_ 997 FT_HFS_Tuer_Status 3;
BA_ "GenSigSwitchedByIgnition" SG_ 997 FT_HFS_Tuer_Status 0;
BA_ "Fehlerwert" SG_ 997 FT_HFS_Tuer_Status 3;
BA_ "GenSigSendType" SG_ 997 FT_Kisi_Taster_li_02 3;
BA_ "GenSigSwitchedByIgnition" SG_ 997 FT_Kisi_Taster_li_02 0;
BA_ "GenSigSendType" SG_ 997 FT_Kisi_Taster_re_02 3;
BA_ "GenSigSwitchedByIgnition" SG_ 997 FT_Kisi_Taster_re_02 0;
BA_ "GenSigSendType" SG_ 997 FT_Lock_Taster_02 0;
BA_ "GenSigSwitchedByIgnition" SG_ 997 FT_Lock_Taster_02 0;
BA_ "GenSigSendType" SG_ 997 FT_Schluesselschalter_zu_02 0;
BA_ "GenSigSwitchedByIgnition" SG_ 997 FT_Schluesselschalter_zu_02 0;
BA_ "GenSigSendType" SG_ 997 FT_SP_Heizung_ein 3;
BA_ "GenSigSwitchedByIgnition" SG_ 997 FT_SP_Heizung_ein 0;
BA_ "GenSigSendType" SG_ 997 FT_TD_Taste_Status 3;
BA_ "GenSigSwitchedByIgnition" SG_ 997 FT_TD_Taste_Status 0;
BA_ "GenSigSendType" SG_ 997 FT_Tuer_Status 3;
BA_ "GenSigSwitchedByIgnition" SG_ 997 FT_Tuer_Status 0;
BA_ "Fehlerwert" SG_ 997 FT_Tuer_Status 3;
BA_ "GenSigSendType" SG_ 997 FT_Tuer_Status_QBit 0;
BA_ "GenSigSwitchedByIgnition" SG_ 997 FT_Tuer_Status_QBit 0;
BA_ "GenSigSendType" SG_ 997 FT_Tuerschloss_verrieg_nicht 0;
BA_ "GenSigSwitchedByIgnition" SG_ 997 FT_Tuerschloss_verrieg_nicht 0;
BA_ "GenSigSendType" SG_ 997 TSG_FT_02_BZ 0;
BA_ "GenSigFuncType" SG_ 997 TSG_FT_02_BZ 1;
BA_ "GenSigSwitchedByIgnition" SG_ 997 TSG_FT_02_BZ 0;
BA_ "GenSigSendType" SG_ 997 TSG_FT_02_CRC 0;
BA_ "GenSigFuncType" SG_ 997 TSG_FT_02_CRC 2;
BA_ "GenSigSwitchedByIgnition" SG_ 997 TSG_FT_02_CRC 0;
BA_ "GenSigSendType" SG_ 288 TSK_06_BZ 0;
BA_ "GenSigFuncType" SG_ 288 TSK_06_BZ 1;
BA_ "GenSigSwitchedByIgnition" SG_ 288 TSK_06_BZ 0;
BA_ "GenSigSendType" SG_ 288 TSK_06_CRC 0;
BA_ "GenSigFuncType" SG_ 288 TSK_06_CRC 2;
BA_ "GenSigSwitchedByIgnition" SG_ 288 TSK_06_CRC 0;
BA_ "GenSigSendType" SG_ 288 TSK_ax_Getriebe_02 0;
BA_ "GenSigStartValue" SG_ 288 TSK_ax_Getriebe_02 511;
BA_ "GenSigSwitchedByIgnition" SG_ 288 TSK_ax_Getriebe_02 0;
BA_ "GenSigSendType" SG_ 288 TSK_Freig_Verzoeg_Anf 0;
BA_ "GenSigSwitchedByIgnition" SG_ 288 TSK_Freig_Verzoeg_Anf 0;
BA_ "GenSigSendType" SG_ 288 TSK_Freig_WU 0;
BA_ "GenSigSwitchedByIgnition" SG_ 288 TSK_Freig_WU 0;
BA_ "GenSigSendType" SG_ 288 TSK_Hauptschalter_GRA_ACC 0;
BA_ "GenSigSwitchedByIgnition" SG_ 288 TSK_Hauptschalter_GRA_ACC 0;
BA_ "Fehlerwert" SG_ 288 TSK_Hauptschalter_GRA_ACC 3;
BA_ "GenSigSendType" SG_ 288 TSK_Limiter_ausgewaehlt 0;
BA_ "GenSigSwitchedByIgnition" SG_ 288 TSK_Limiter_ausgewaehlt 0;
BA_ "GenSigSendType" SG_ 288 TSK_Radbremsmom 0;
BA_ "GenSigSwitchedByIgnition" SG_ 288 TSK_Radbremsmom 0;
BA_ "GenSigSendType" SG_ 288 TSK_SRBM_Anf_ASIL 0;
BA_ "GenSigSwitchedByIgnition" SG_ 288 TSK_SRBM_Anf_ASIL 0;
BA_ "GenSigSendType" SG_ 288 TSK_Standby_Anf_ESP 0;
BA_ "GenSigSwitchedByIgnition" SG_ 288 TSK_Standby_Anf_ESP 0;
BA_ "GenSigSendType" SG_ 288 TSK_Status 0;
BA_ "GenSigStartValue" SG_ 288 TSK_Status 1;
BA_ "GenSigSwitchedByIgnition" SG_ 288 TSK_Status 0;
BA_ "GenSigSendType" SG_ 288 TSK_v_Begrenzung_aktiv 0;
BA_ "GenSigSwitchedByIgnition" SG_ 288 TSK_v_Begrenzung_aktiv 0;
BA_ "GenSigSendType" SG_ 288 TSK_Wunsch_Uebersetz 0;
BA_ "GenSigSwitchedByIgnition" SG_ 288 TSK_Wunsch_Uebersetz 0;
BA_ "GenSigSendType" SG_ 288 TSK_zul_Regelabw 0;
BA_ "GenSigSwitchedByIgnition" SG_ 288 TSK_zul_Regelabw 0;
BA_ "GenSigSendType" SG_ 288 TSK_Zwangszusch_ESP 0;
BA_ "GenSigSwitchedByIgnition" SG_ 288 TSK_Zwangszusch_ESP 0;
BA_ "GenSigSwitchedByIgnition" SG_ 1716 KS_Geheimnis_1 0;
BA_ "GenSigSwitchedByIgnition" SG_ 1716 KS_Geheimnis_2 0;
BA_ "GenSigSwitchedByIgnition" SG_ 1716 KS_Geheimnis_3 0;
BA_ "GenSigSwitchedByIgnition" SG_ 1716 KS_Geheimnis_4 0;
BA_ "GenSigSendType" SG_ 1716 VIN_01_MUX 0;
BA_ "GenSigSwitchedByIgnition" SG_ 1716 VIN_01_MUX 0;
BA_ "GenSigStartValue" SG_ 1716 VIN_1 45;
BA_ "GenSigSwitchedByIgnition" SG_ 1716 VIN_1 0;
BA_ "GenSigStartValue" SG_ 1716 VIN_10 45;
BA_ "GenSigSwitchedByIgnition" SG_ 1716 VIN_10 0;
BA_ "GenSigStartValue" SG_ 1716 VIN_11 45;
BA_ "GenSigSwitchedByIgnition" SG_ 1716 VIN_11 0;
BA_ "GenSigStartValue" SG_ 1716 VIN_12 45;
BA_ "GenSigSwitchedByIgnition" SG_ 1716 VIN_12 0;
BA_ "GenSigStartValue" SG_ 1716 VIN_13 45;
BA_ "GenSigSwitchedByIgnition" SG_ 1716 VIN_13 0;
BA_ "GenSigStartValue" SG_ 1716 VIN_14 45;
BA_ "GenSigSwitchedByIgnition" SG_ 1716 VIN_14 0;
BA_ "GenSigStartValue" SG_ 1716 VIN_15 45;
BA_ "GenSigSwitchedByIgnition" SG_ 1716 VIN_15 0;
BA_ "GenSigStartValue" SG_ 1716 VIN_16 45;
BA_ "GenSigSwitchedByIgnition" SG_ 1716 VIN_16 0;
BA_ "GenSigStartValue" SG_ 1716 VIN_17 45;
BA_ "GenSigSwitchedByIgnition" SG_ 1716 VIN_17 0;
BA_ "GenSigStartValue" SG_ 1716 VIN_2 45;
BA_ "GenSigSwitchedByIgnition" SG_ 1716 VIN_2 0;
BA_ "GenSigStartValue" SG_ 1716 VIN_3 45;
BA_ "GenSigSwitchedByIgnition" SG_ 1716 VIN_3 0;
BA_ "GenSigStartValue" SG_ 1716 VIN_4 45;
BA_ "GenSigSwitchedByIgnition" SG_ 1716 VIN_4 0;
BA_ "GenSigStartValue" SG_ 1716 VIN_5 45;
BA_ "GenSigSwitchedByIgnition" SG_ 1716 VIN_5 0;
BA_ "GenSigStartValue" SG_ 1716 VIN_6 45;
BA_ "GenSigSwitchedByIgnition" SG_ 1716 VIN_6 0;
BA_ "GenSigStartValue" SG_ 1716 VIN_7 45;
BA_ "GenSigSwitchedByIgnition" SG_ 1716 VIN_7 0;
BA_ "GenSigStartValue" SG_ 1716 VIN_8 45;
BA_ "GenSigSwitchedByIgnition" SG_ 1716 VIN_8 0;
BA_ "GenSigStartValue" SG_ 1716 VIN_9 45;
BA_ "GenSigSwitchedByIgnition" SG_ 1716 VIN_9 0;
BA_ "GenSigSendType" SG_ 2617218560 XCP_Daempfer_CRO_01_Data 6;
BA_ "GenSigSwitchedByIgnition" SG_ 2617218560 XCP_Daempfer_CRO_01_Data 0;
BA_ "GenSigSendType" SG_ 2617218561 XCP_Daempfer_DTO_01_Data 6;
BA_ "GenSigSwitchedByIgnition" SG_ 2617024000 XCP_ESP_CRO_01_Data 0;
BA_ "GenSigSwitchedByIgnition" SG_ 2617024001 XCP_ESP_DTO_01_Data 0;
BA_REL_ "GenSigTimeoutTime" BU_SG_REL_ Allrad_Haldex SG_ 1601 MO_Faktor_Momente_02 5000;
BA_REL_ "GenSigTimeoutTime" BU_SG_REL_ Allrad_Haldex SG_ 1601 MO_Kraftstoffart 5000;
BA_REL_ "GenSigTimeoutTime" BU_SG_REL_ Allrad_Haldex SG_ 1601 MO_Leistung 5000;
BA_REL_ "GenSigTimeoutTime" BU_SG_REL_ Allrad_Haldex SG_ 1413 SI_NWDF 5000;
BA_REL_ "GenSigTimeoutTime" BU_SG_REL_ Allrad_Haldex SG_ 1413 SI_NWDF_gueltig 5000;
BA_REL_ "GenSigTimeoutTime" BU_SG_REL_ AreaView_MQB SG_ 2600468499 NM_ABS_NM_State 2000;
BA_REL_ "GenSigTimeoutTime" BU_SG_REL_ AreaView_MQB SG_ 2600468496 NM_Gateway_NM_State 2000;
BA_REL_ "GenSigTimeoutTime" BU_SG_REL_ AreaView_MQB SG_ 2600468498 NM_Lenkhilfe_NM_State 2000;
BA_REL_ "GenSigTimeoutTime" BU_SG_REL_ AreaView_MQB SG_ 2600468585 NM_Rearview_NM_State 2000;
BA_REL_ "GenSigTimeoutTime" BU_SG_REL_ AreaView_MQB SG_ 1175 PH_Visualisierung 1000;
BA_REL_ "GenSigTimeoutTime" BU_SG_REL_ AreaView_MQB SG_ 1175 PLA_Anf_Aufschaltung_RVC 1000;
BA_REL_ "GenSigTimeoutTime" BU_SG_REL_ AreaView_MQB SG_ 1175 PH_Taster 1000;
BA_REL_ "GenSigTimeoutTime" BU_SG_REL_ AreaView_MQB SG_ 1175 PH_Systemzustand 1000;
BA_REL_ "GenSigTimeoutTime" BU_SG_REL_ AreaView_MQB SG_ 1353 PL_Luecke_P0_x 1000;
BA_REL_ "GenSigTimeoutTime" BU_SG_REL_ AreaView_MQB SG_ 1353 PL_Luecke_P0_y 1000;
BA_REL_ "GenSigTimeoutTime" BU_SG_REL_ AreaView_MQB SG_ 1353 PL_Luecke_P2_x 1000;
BA_REL_ "GenSigTimeoutTime" BU_SG_REL_ AreaView_MQB SG_ 1353 PL_Luecke_P2_y 1000;
BA_REL_ "GenSigTimeoutTime" BU_SG_REL_ AreaView_MQB SG_ 1354 PL_Luecke_P1_x 1000;
BA_REL_ "GenSigTimeoutTime" BU_SG_REL_ AreaView_MQB SG_ 1354 PL_Luecke_P1_y 1000;
BA_REL_ "GenSigTimeoutTime" BU_SG_REL_ AreaView_MQB SG_ 1354 PL_Luecke_P3_x 1000;
BA_REL_ "GenSigTimeoutTime" BU_SG_REL_ AreaView_MQB SG_ 1354 PL_Luecke_P3_y 1000;
BA_REL_ "GenSigTimeoutTime" BU_SG_REL_ AreaView_MQB SG_ 1710 SP_abklappen 5000;
BA_REL_ "GenSigTimeoutTime" BU_SG_REL_ AreaView_MQB SG_ 1710 SP_anklappen 5000;
BA_REL_ "GenSigTimeoutTime" BU_SG_REL_ AreaView_MQB SG_ 1710 SP_S_Klappen 5000;
BA_REL_ "GenSigTimeoutTime" BU_SG_REL_ AreaView_MQB SG_ 1413 SI_NWDF 5000;
BA_REL_ "GenSigTimeoutTime" BU_SG_REL_ AreaView_MQB SG_ 1413 SI_NWDF_gueltig 5000;
BA_REL_ "GenSigTimeoutTime" BU_SG_REL_ Bremse_ABS_MK100 SG_ 1601 Motor_Code_01_CRC 5000;
BA_REL_ "GenSigTimeoutTime" BU_SG_REL_ Bremse_ABS_MK100 SG_ 1601 Motor_Code_01_BZ 5000;
BA_REL_ "GenSigTimeoutTime" BU_SG_REL_ Bremse_ABS_MK100 SG_ 1601 MO_Faktor_Momente_02 5000;
BA_REL_ "GenSigTimeoutTime" BU_SG_REL_ Bremse_ABS_MK100 SG_ 1601 MO_Getriebe_Code 5000;
BA_REL_ "GenSigTimeoutTime" BU_SG_REL_ Bremse_ABS_MK100 SG_ 2600468499 NM_ABS_NM_State 2000;
BA_REL_ "GenSigTimeoutTime" BU_SG_REL_ Bremse_ABS_MK100 SG_ 2600468496 NM_Gateway_NM_State 2000;
BA_REL_ "GenSigTimeoutTime" BU_SG_REL_ Bremse_ABS_MK100 SG_ 2600468498 NM_Lenkhilfe_NM_State 2000;
BA_REL_ "GenSigTimeoutTime" BU_SG_REL_ Bremse_ABS_MK100 SG_ 2600468585 NM_Rearview_NM_State 2000;
BA_REL_ "GenSigTimeoutTime" BU_SG_REL_ Bremse_ABS_MK100 SG_ 1716 VIN_01_MUX 2000;
BA_REL_ "GenSigTimeoutTime" BU_SG_REL_ Bremse_ABS_MK100 SG_ 1716 VIN_13 2000;
BA_REL_ "GenSigTimeoutTime" BU_SG_REL_ Bremse_ABS_MK100 SG_ 1716 VIN_7 2000;
BA_REL_ "GenSigTimeoutTime" BU_SG_REL_ Bremse_ABS_MK100 SG_ 1716 VIN_14 2000;
BA_REL_ "GenSigTimeoutTime" BU_SG_REL_ Bremse_ABS_MK100 SG_ 1716 VIN_8 2000;
BA_REL_ "GenSigTimeoutTime" BU_SG_REL_ Bremse_ABS_MK100 SG_ 1716 VIN_15 2000;
BA_REL_ "GenSigTimeoutTime" BU_SG_REL_ Bremse_ABS_MK100 SG_ 1716 VIN_16 2000;
BA_REL_ "GenSigTimeoutTime" BU_SG_REL_ Bremse_ABS_MK100 SG_ 1716 VIN_17 2000;
BA_REL_ "GenSigTimeoutTime" BU_SG_REL_ Bremse_ESP_EPB_EBC460Vi SG_ 1601 Motor_Code_01_CRC 5000;
BA_REL_ "GenSigTimeoutTime" BU_SG_REL_ Bremse_ESP_EPB_EBC460Vi SG_ 1601 Motor_Code_01_BZ 5000;
BA_REL_ "GenSigTimeoutTime" BU_SG_REL_ Bremse_ESP_EPB_EBC460Vi SG_ 1601 MO_Faktor_Momente_02 5000;
BA_REL_ "GenSigTimeoutTime" BU_SG_REL_ Bremse_ESP_EPB_EBC460Vi SG_ 1601 MO_Hybridfahrzeug 5000;
BA_REL_ "GenSigTimeoutTime" BU_SG_REL_ Bremse_ESP_EPB_EBC460Vi SG_ 1601 MO_Getriebe_Code 5000;
BA_REL_ "GenSigTimeoutTime" BU_SG_REL_ Bremse_ESP_EPB_EBC460Vi SG_ 1601 MO_Anzahl_Zyl 5000;
BA_REL_ "GenSigTimeoutTime" BU_SG_REL_ Bremse_ESP_EPB_EBC460Vi SG_ 1601 MO_Kraftstoffart 5000;
BA_REL_ "GenSigTimeoutTime" BU_SG_REL_ Bremse_ESP_EPB_EBC460Vi SG_ 1601 MO_Hubraum 5000;
BA_REL_ "GenSigTimeoutTime" BU_SG_REL_ Bremse_ESP_EPB_EBC460Vi SG_ 1601 MO_Ansaugsystem 5000;
BA_REL_ "GenSigTimeoutTime" BU_SG_REL_ Bremse_ESP_EPB_EBC460Vi SG_ 1601 MO_Leistung 5000;
BA_REL_ "GenSigTimeoutTime" BU_SG_REL_ Bremse_ESP_EPB_EBC460Vi SG_ 1601 TSK_Codierung 5000;
BA_REL_ "GenSigTimeoutTime" BU_SG_REL_ Bremse_ESP_EPB_EBC460Vi SG_ 2600468499 NM_ABS_NM_State 2000;
BA_REL_ "GenSigTimeoutTime" BU_SG_REL_ Bremse_ESP_EPB_EBC460Vi SG_ 2600468496 NM_Gateway_NM_State 2000;
BA_REL_ "GenSigTimeoutTime" BU_SG_REL_ Bremse_ESP_EPB_EBC460Vi SG_ 2600468498 NM_Lenkhilfe_NM_State 2000;
BA_REL_ "GenSigTimeoutTime" BU_SG_REL_ Bremse_ESP_EPB_EBC460Vi SG_ 2600468585 NM_Rearview_NM_State 2000;
BA_REL_ "GenSigTimeoutTime" BU_SG_REL_ Bremse_ESP_EPB_EBC460Vi SG_ 304 PLA_01_CRC 5000;
BA_REL_ "GenSigTimeoutTime" BU_SG_REL_ Bremse_ESP_EPB_EBC460Vi SG_ 304 PLA_01_BZ 5000;
BA_REL_ "GenSigTimeoutTime" BU_SG_REL_ Bremse_ESP_EPB_EBC460Vi SG_ 304 PLA_Status_PLA_ESP 5000;
BA_REL_ "GenSigTimeoutTime" BU_SG_REL_ Bremse_ESP_EPB_EBC460Vi SG_ 304 PLA_Bremsmoment 5000;
BA_REL_ "GenSigTimeoutTime" BU_SG_REL_ Bremse_ESP_EPB_EBC460Vi SG_ 304 PLA_Bremsverzoegerung 5000;
BA_REL_ "GenSigTimeoutTime" BU_SG_REL_ Bremse_ESP_EPB_EBC460Vi SG_ 304 PLA_Anf_Bremsverzoegerung 5000;
BA_REL_ "GenSigTimeoutTime" BU_SG_REL_ Bremse_ESP_EPB_EBC460Vi SG_ 304 PLA_BremsMom_Verzoeg 5000;
BA_REL_ "GenSigTimeoutTime" BU_SG_REL_ Bremse_ESP_EPB_EBC460Vi SG_ 304 PLA_Anhalten 5000;
BA_REL_ "GenSigTimeoutTime" BU_SG_REL_ Bremse_ESP_EPB_EBC460Vi SG_ 304 PLA_Anhalteweg 5000;
BA_REL_ "GenSigTimeoutTime" BU_SG_REL_ Bremse_ESP_EPB_EBC460Vi SG_ 695 RCTA_01_CRC 500;
BA_REL_ "GenSigTimeoutTime" BU_SG_REL_ Bremse_ESP_EPB_EBC460Vi SG_ 695 RCTA_01_BZ 500;
BA_REL_ "GenSigTimeoutTime" BU_SG_REL_ Bremse_ESP_EPB_EBC460Vi SG_ 695 RCTA_Bremsruck_Anforderung 500;
BA_REL_ "GenSigTimeoutTime" BU_SG_REL_ Bremse_ESP_EPB_EBC460Vi SG_ 695 RCTA_Bremsruck_Freigabe 500;
BA_REL_ "GenSigTimeoutTime" BU_SG_REL_ Bremse_ESP_EPB_EBC460Vi SG_ 695 RCTA_Status 500;
BA_REL_ "GenSigTimeoutTime" BU_SG_REL_ Bremse_ESP_EPB_EBC460Vi SG_ 695 RCTA_Notbremsung_Freigabe 500;
BA_REL_ "GenSigTimeoutTime" BU_SG_REL_ Bremse_ESP_EPB_EBC460Vi SG_ 695 RCTA_Notbremsung_Anforderung 500;
BA_REL_ "GenSigTimeoutTime" BU_SG_REL_ Bremse_ESP_EPB_EBC460Vi SG_ 1413 SI_NWDF 5000;
BA_REL_ "GenSigTimeoutTime" BU_SG_REL_ Bremse_ESP_EPB_EBC460Vi SG_ 1413 SI_NWDF_gueltig 5000;
BA_REL_ "GenSigTimeoutTime" BU_SG_REL_ Bremse_ESP_EPB_EBC460Vi SG_ 997 TSG_FT_02_CRC 1000;
BA_REL_ "GenSigTimeoutTime" BU_SG_REL_ Bremse_ESP_EPB_EBC460Vi SG_ 997 TSG_FT_02_BZ 1000;
BA_REL_ "GenSigTimeoutTime" BU_SG_REL_ Bremse_ESP_EPB_EBC460Vi SG_ 997 FT_Tuer_Status 1000;
BA_REL_ "GenSigTimeoutTime" BU_SG_REL_ Bremse_ESP_EPB_EBC460Vi SG_ 288 TSK_06_CRC 500;
BA_REL_ "GenSigTimeoutTime" BU_SG_REL_ Bremse_ESP_EPB_EBC460Vi SG_ 288 TSK_06_BZ 500;
BA_REL_ "GenSigTimeoutTime" BU_SG_REL_ Bremse_ESP_EPB_EBC460Vi SG_ 288 TSK_Radbremsmom 500;
BA_REL_ "GenSigTimeoutTime" BU_SG_REL_ Bremse_ESP_EPB_EBC460Vi SG_ 288 TSK_Status 500;
BA_REL_ "GenSigTimeoutTime" BU_SG_REL_ Bremse_ESP_EPB_EBC460Vi SG_ 288 TSK_Standby_Anf_ESP 500;
BA_REL_ "GenSigTimeoutTime" BU_SG_REL_ Bremse_ESP_EPB_EBC460Vi SG_ 288 TSK_Freig_Verzoeg_Anf 500;
BA_REL_ "GenSigTimeoutTime" BU_SG_REL_ Bremse_ESP_EPB_EBC460Vi SG_ 288 TSK_Zwangszusch_ESP 500;
BA_REL_ "GenSigTimeoutTime" BU_SG_REL_ Bremse_ESP_EPB_EBC460Vi SG_ 1716 VIN_01_MUX 2000;
BA_REL_ "GenSigTimeoutTime" BU_SG_REL_ Bremse_ESP_EPB_EBC460Vi SG_ 1716 VIN_13 2000;
BA_REL_ "GenSigTimeoutTime" BU_SG_REL_ Bremse_ESP_EPB_EBC460Vi SG_ 1716 VIN_7 2000;
BA_REL_ "GenSigTimeoutTime" BU_SG_REL_ Bremse_ESP_EPB_EBC460Vi SG_ 1716 VIN_14 2000;
BA_REL_ "GenSigTimeoutTime" BU_SG_REL_ Bremse_ESP_EPB_EBC460Vi SG_ 1716 VIN_8 2000;
BA_REL_ "GenSigTimeoutTime" BU_SG_REL_ Bremse_ESP_EPB_EBC460Vi SG_ 1716 VIN_15 2000;
BA_REL_ "GenSigTimeoutTime" BU_SG_REL_ Bremse_ESP_EPB_EBC460Vi SG_ 1716 VIN_16 2000;
BA_REL_ "GenSigTimeoutTime" BU_SG_REL_ Bremse_ESP_EPB_EBC460Vi SG_ 1716 VIN_17 2000;
BA_REL_ "GenSigTimeoutTime" BU_SG_REL_ Bremse_ESP_EPB_MK100 SG_ 1601 Motor_Code_01_CRC 5000;
BA_REL_ "GenSigTimeoutTime" BU_SG_REL_ Bremse_ESP_EPB_MK100 SG_ 1601 Motor_Code_01_BZ 5000;
BA_REL_ "GenSigTimeoutTime" BU_SG_REL_ Bremse_ESP_EPB_MK100 SG_ 1601 MO_Faktor_Momente_02 5000;
BA_REL_ "GenSigTimeoutTime" BU_SG_REL_ Bremse_ESP_EPB_MK100 SG_ 1601 MO_Hybridfahrzeug 5000;
BA_REL_ "GenSigTimeoutTime" BU_SG_REL_ Bremse_ESP_EPB_MK100 SG_ 1601 MO_Getriebe_Code 5000;
BA_REL_ "GenSigTimeoutTime" BU_SG_REL_ Bremse_ESP_EPB_MK100 SG_ 1601 MO_Anzahl_Zyl 5000;
BA_REL_ "GenSigTimeoutTime" BU_SG_REL_ Bremse_ESP_EPB_MK100 SG_ 1601 MO_Kraftstoffart 5000;
BA_REL_ "GenSigTimeoutTime" BU_SG_REL_ Bremse_ESP_EPB_MK100 SG_ 1601 MO_Hubraum 5000;
BA_REL_ "GenSigTimeoutTime" BU_SG_REL_ Bremse_ESP_EPB_MK100 SG_ 1601 MO_Ansaugsystem 5000;
BA_REL_ "GenSigTimeoutTime" BU_SG_REL_ Bremse_ESP_EPB_MK100 SG_ 1601 MO_Leistung 5000;
BA_REL_ "GenSigTimeoutTime" BU_SG_REL_ Bremse_ESP_EPB_MK100 SG_ 1601 MO_OBD_Typ 5000;
BA_REL_ "GenSigTimeoutTime" BU_SG_REL_ Bremse_ESP_EPB_MK100 SG_ 1601 TSK_Codierung 5000;
BA_REL_ "GenSigTimeoutTime" BU_SG_REL_ Bremse_ESP_EPB_MK100 SG_ 2600468499 NM_ABS_NM_State 2000;
BA_REL_ "GenSigTimeoutTime" BU_SG_REL_ Bremse_ESP_EPB_MK100 SG_ 2600468496 NM_Gateway_NM_State 2000;
BA_REL_ "GenSigTimeoutTime" BU_SG_REL_ Bremse_ESP_EPB_MK100 SG_ 2600468498 NM_Lenkhilfe_NM_State 2000;
BA_REL_ "GenSigTimeoutTime" BU_SG_REL_ Bremse_ESP_EPB_MK100 SG_ 2600468585 NM_Rearview_NM_State 2000;
BA_REL_ "GenSigTimeoutTime" BU_SG_REL_ Bremse_ESP_EPB_MK100 SG_ 913 OBD_Calc_Load_Val 1000;
BA_REL_ "GenSigTimeoutTime" BU_SG_REL_ Bremse_ESP_EPB_MK100 SG_ 913 OBD_Eng_Cool_Temp 1000;
BA_REL_ "GenSigTimeoutTime" BU_SG_REL_ Bremse_ESP_EPB_MK100 SG_ 913 OBD_Abs_Throttle_Pos 1000;
BA_REL_ "GenSigTimeoutTime" BU_SG_REL_ Bremse_ESP_EPB_MK100 SG_ 913 OBD_Abs_Load_Val 1000;
BA_REL_ "GenSigTimeoutTime" BU_SG_REL_ Bremse_ESP_EPB_MK100 SG_ 913 OBD_Abs_Pedal_Pos 1000;
BA_REL_ "GenSigTimeoutTime" BU_SG_REL_ Bremse_ESP_EPB_MK100 SG_ 913 OBD_Sperrung_IUMPR 1000;
BA_REL_ "GenSigTimeoutTime" BU_SG_REL_ Bremse_ESP_EPB_MK100 SG_ 913 OBD_Kaltstart_Denominator 1000;
BA_REL_ "GenSigTimeoutTime" BU_SG_REL_ Bremse_ESP_EPB_MK100 SG_ 913 OBD_Minimum_Trip 1000;
BA_REL_ "GenSigTimeoutTime" BU_SG_REL_ Bremse_ESP_EPB_MK100 SG_ 913 OBD_Driving_Cycle 1000;
BA_REL_ "GenSigTimeoutTime" BU_SG_REL_ Bremse_ESP_EPB_MK100 SG_ 913 OBD_Warm_Up_Cycle 1000;
BA_REL_ "GenSigTimeoutTime" BU_SG_REL_ Bremse_ESP_EPB_MK100 SG_ 913 OBD_Normed_Trip 1000;
BA_REL_ "GenSigTimeoutTime" BU_SG_REL_ Bremse_ESP_EPB_MK100 SG_ 304 PLA_01_CRC 5000;
BA_REL_ "GenSigTimeoutTime" BU_SG_REL_ Bremse_ESP_EPB_MK100 SG_ 304 PLA_01_BZ 5000;
BA_REL_ "GenSigTimeoutTime" BU_SG_REL_ Bremse_ESP_EPB_MK100 SG_ 304 PLA_Status_PLA_ESP 5000;
BA_REL_ "GenSigTimeoutTime" BU_SG_REL_ Bremse_ESP_EPB_MK100 SG_ 304 PLA_Bremsmoment 5000;
BA_REL_ "GenSigTimeoutTime" BU_SG_REL_ Bremse_ESP_EPB_MK100 SG_ 304 PLA_Bremsverzoegerung 5000;
BA_REL_ "GenSigTimeoutTime" BU_SG_REL_ Bremse_ESP_EPB_MK100 SG_ 304 PLA_Anf_Bremsverzoegerung 5000;
BA_REL_ "GenSigTimeoutTime" BU_SG_REL_ Bremse_ESP_EPB_MK100 SG_ 304 PLA_BremsMom_Verzoeg 5000;
BA_REL_ "GenSigTimeoutTime" BU_SG_REL_ Bremse_ESP_EPB_MK100 SG_ 304 PLA_Anhalten 5000;
BA_REL_ "GenSigTimeoutTime" BU_SG_REL_ Bremse_ESP_EPB_MK100 SG_ 304 PLA_Anhalteweg 5000;
BA_REL_ "GenSigTimeoutTime" BU_SG_REL_ Bremse_ESP_EPB_MK100 SG_ 695 RCTA_01_CRC 500;
BA_REL_ "GenSigTimeoutTime" BU_SG_REL_ Bremse_ESP_EPB_MK100 SG_ 695 RCTA_01_BZ 500;
BA_REL_ "GenSigTimeoutTime" BU_SG_REL_ Bremse_ESP_EPB_MK100 SG_ 695 RCTA_Bremsruck_Anforderung 500;
BA_REL_ "GenSigTimeoutTime" BU_SG_REL_ Bremse_ESP_EPB_MK100 SG_ 695 RCTA_Bremsruck_Freigabe 500;
BA_REL_ "GenSigTimeoutTime" BU_SG_REL_ Bremse_ESP_EPB_MK100 SG_ 695 RCTA_Status 500;
BA_REL_ "GenSigTimeoutTime" BU_SG_REL_ Bremse_ESP_EPB_MK100 SG_ 695 RCTA_Notbremsung_Freigabe 500;
BA_REL_ "GenSigTimeoutTime" BU_SG_REL_ Bremse_ESP_EPB_MK100 SG_ 695 RCTA_Notbremsung_Anforderung 500;
BA_REL_ "GenSigTimeoutTime" BU_SG_REL_ Bremse_ESP_EPB_MK100 SG_ 997 TSG_FT_02_CRC 1000;
BA_REL_ "GenSigTimeoutTime" BU_SG_REL_ Bremse_ESP_EPB_MK100 SG_ 997 TSG_FT_02_BZ 1000;
BA_REL_ "GenSigTimeoutTime" BU_SG_REL_ Bremse_ESP_EPB_MK100 SG_ 997 FT_Tuer_Status 1000;
BA_REL_ "GenSigTimeoutTime" BU_SG_REL_ Bremse_ESP_EPB_MK100 SG_ 288 TSK_06_CRC 500;
BA_REL_ "GenSigTimeoutTime" BU_SG_REL_ Bremse_ESP_EPB_MK100 SG_ 288 TSK_06_BZ 500;
BA_REL_ "GenSigTimeoutTime" BU_SG_REL_ Bremse_ESP_EPB_MK100 SG_ 288 TSK_Radbremsmom 500;
BA_REL_ "GenSigTimeoutTime" BU_SG_REL_ Bremse_ESP_EPB_MK100 SG_ 288 TSK_Status 500;
BA_REL_ "GenSigTimeoutTime" BU_SG_REL_ Bremse_ESP_EPB_MK100 SG_ 288 TSK_Standby_Anf_ESP 500;
BA_REL_ "GenSigTimeoutTime" BU_SG_REL_ Bremse_ESP_EPB_MK100 SG_ 288 TSK_Freig_Verzoeg_Anf 500;
BA_REL_ "GenSigTimeoutTime" BU_SG_REL_ Bremse_ESP_EPB_MK100 SG_ 288 TSK_Zwangszusch_ESP 500;
BA_REL_ "GenSigTimeoutTime" BU_SG_REL_ Bremse_ESP_EPB_MK100 SG_ 1716 VIN_01_MUX 2000;
BA_REL_ "GenSigTimeoutTime" BU_SG_REL_ Bremse_ESP_EPB_MK100 SG_ 1716 VIN_13 2000;
BA_REL_ "GenSigTimeoutTime" BU_SG_REL_ Bremse_ESP_EPB_MK100 SG_ 1716 VIN_7 2000;
BA_REL_ "GenSigTimeoutTime" BU_SG_REL_ Bremse_ESP_EPB_MK100 SG_ 1716 VIN_14 2000;
BA_REL_ "GenSigTimeoutTime" BU_SG_REL_ Bremse_ESP_EPB_MK100 SG_ 1716 VIN_8 2000;
BA_REL_ "GenSigTimeoutTime" BU_SG_REL_ Bremse_ESP_EPB_MK100 SG_ 1716 VIN_15 2000;
BA_REL_ "GenSigTimeoutTime" BU_SG_REL_ Bremse_ESP_EPB_MK100 SG_ 1716 VIN_16 2000;
BA_REL_ "GenSigTimeoutTime" BU_SG_REL_ Bremse_ESP_EPB_MK100 SG_ 1716 VIN_17 2000;
BA_REL_ "GenSigTimeoutTime" BU_SG_REL_ Bremse_ESP_MK100 SG_ 1601 Motor_Code_01_CRC 5000;
BA_REL_ "GenSigTimeoutTime" BU_SG_REL_ Bremse_ESP_MK100 SG_ 1601 Motor_Code_01_BZ 5000;
BA_REL_ "GenSigTimeoutTime" BU_SG_REL_ Bremse_ESP_MK100 SG_ 1601 MO_Faktor_Momente_02 5000;
BA_REL_ "GenSigTimeoutTime" BU_SG_REL_ Bremse_ESP_MK100 SG_ 1601 MO_Getriebe_Code 5000;
BA_REL_ "GenSigTimeoutTime" BU_SG_REL_ Bremse_ESP_MK100 SG_ 1601 MO_Anzahl_Zyl 5000;
BA_REL_ "GenSigTimeoutTime" BU_SG_REL_ Bremse_ESP_MK100 SG_ 1601 MO_Kraftstoffart 5000;
BA_REL_ "GenSigTimeoutTime" BU_SG_REL_ Bremse_ESP_MK100 SG_ 1601 MO_Ansaugsystem 5000;
BA_REL_ "GenSigTimeoutTime" BU_SG_REL_ Bremse_ESP_MK100 SG_ 1601 TSK_Codierung 5000;
BA_REL_ "GenSigTimeoutTime" BU_SG_REL_ Bremse_ESP_MK100 SG_ 2600468499 NM_ABS_NM_State 2000;
BA_REL_ "GenSigTimeoutTime" BU_SG_REL_ Bremse_ESP_MK100 SG_ 2600468496 NM_Gateway_NM_State 2000;
BA_REL_ "GenSigTimeoutTime" BU_SG_REL_ Bremse_ESP_MK100 SG_ 2600468498 NM_Lenkhilfe_NM_State 2000;
BA_REL_ "GenSigTimeoutTime" BU_SG_REL_ Bremse_ESP_MK100 SG_ 2600468585 NM_Rearview_NM_State 2000;
BA_REL_ "GenSigTimeoutTime" BU_SG_REL_ Bremse_ESP_MK100 SG_ 304 PLA_01_CRC 5000;
BA_REL_ "GenSigTimeoutTime" BU_SG_REL_ Bremse_ESP_MK100 SG_ 304 PLA_01_BZ 5000;
BA_REL_ "GenSigTimeoutTime" BU_SG_REL_ Bremse_ESP_MK100 SG_ 304 PLA_Status_PLA_ESP 5000;
BA_REL_ "GenSigTimeoutTime" BU_SG_REL_ Bremse_ESP_MK100 SG_ 304 PLA_Bremsmoment 5000;
BA_REL_ "GenSigTimeoutTime" BU_SG_REL_ Bremse_ESP_MK100 SG_ 304 PLA_Bremsverzoegerung 5000;
BA_REL_ "GenSigTimeoutTime" BU_SG_REL_ Bremse_ESP_MK100 SG_ 304 PLA_Anf_Bremsverzoegerung 5000;
BA_REL_ "GenSigTimeoutTime" BU_SG_REL_ Bremse_ESP_MK100 SG_ 304 PLA_BremsMom_Verzoeg 5000;
BA_REL_ "GenSigTimeoutTime" BU_SG_REL_ Bremse_ESP_MK100 SG_ 304 PLA_Anhalten 5000;
BA_REL_ "GenSigTimeoutTime" BU_SG_REL_ Bremse_ESP_MK100 SG_ 304 PLA_Anhalteweg 5000;
BA_REL_ "GenSigTimeoutTime" BU_SG_REL_ Bremse_ESP_MK100 SG_ 288 TSK_06_CRC 500;
BA_REL_ "GenSigTimeoutTime" BU_SG_REL_ Bremse_ESP_MK100 SG_ 288 TSK_06_BZ 500;
BA_REL_ "GenSigTimeoutTime" BU_SG_REL_ Bremse_ESP_MK100 SG_ 288 TSK_Radbremsmom 500;
BA_REL_ "GenSigTimeoutTime" BU_SG_REL_ Bremse_ESP_MK100 SG_ 288 TSK_Status 500;
BA_REL_ "GenSigTimeoutTime" BU_SG_REL_ Bremse_ESP_MK100 SG_ 288 TSK_Standby_Anf_ESP 500;
BA_REL_ "GenSigTimeoutTime" BU_SG_REL_ Bremse_ESP_MK100 SG_ 288 TSK_Freig_Verzoeg_Anf 500;
BA_REL_ "GenSigTimeoutTime" BU_SG_REL_ Bremse_ESP_MK100 SG_ 288 TSK_Zwangszusch_ESP 500;
BA_REL_ "GenSigTimeoutTime" BU_SG_REL_ Bremse_ESP_MK100 SG_ 1716 VIN_01_MUX 2000;
BA_REL_ "GenSigTimeoutTime" BU_SG_REL_ Bremse_ESP_MK100 SG_ 1716 VIN_13 2000;
BA_REL_ "GenSigTimeoutTime" BU_SG_REL_ Bremse_ESP_MK100 SG_ 1716 VIN_7 2000;
BA_REL_ "GenSigTimeoutTime" BU_SG_REL_ Bremse_ESP_MK100 SG_ 1716 VIN_14 2000;
BA_REL_ "GenSigTimeoutTime" BU_SG_REL_ Bremse_ESP_MK100 SG_ 1716 VIN_8 2000;
BA_REL_ "GenSigTimeoutTime" BU_SG_REL_ Bremse_ESP_MK100 SG_ 1716 VIN_15 2000;
BA_REL_ "GenSigTimeoutTime" BU_SG_REL_ Bremse_ESP_MK100 SG_ 1716 VIN_16 2000;
BA_REL_ "GenSigTimeoutTime" BU_SG_REL_ Bremse_ESP_MK100 SG_ 1716 VIN_17 2000;
BA_REL_ "GenSigTimeoutTime" BU_SG_REL_ Daempfer SG_ 1413 SI_NWDF 5000;
BA_REL_ "GenSigTimeoutTime" BU_SG_REL_ Daempfer SG_ 1413 SI_NWDF_gueltig 5000;
BA_REL_ "GenSigTimeoutTime" BU_SG_REL_ Daempfer SG_ 1413 SI_T_Schutz 5000;
BA_REL_ "GenSigTimeoutTime" BU_SG_REL_ Daempfer SG_ 1716 VIN_01_MUX 2000;
BA_REL_ "GenSigTimeoutTime" BU_SG_REL_ Daempfer SG_ 1716 VIN_4 2000;
BA_REL_ "GenSigTimeoutTime" BU_SG_REL_ Daempfer SG_ 1716 VIN_11 2000;
BA_REL_ "GenSigTimeoutTime" BU_SG_REL_ Daempfer SG_ 1716 VIN_5 2000;
BA_REL_ "GenSigTimeoutTime" BU_SG_REL_ Daempfer SG_ 1716 VIN_12 2000;
BA_REL_ "GenSigTimeoutTime" BU_SG_REL_ Daempfer SG_ 1716 VIN_6 2000;
BA_REL_ "GenSigTimeoutTime" BU_SG_REL_ Daempfer SG_ 1716 VIN_13 2000;
BA_REL_ "GenSigTimeoutTime" BU_SG_REL_ Daempfer SG_ 1716 VIN_7 2000;
BA_REL_ "GenSigTimeoutTime" BU_SG_REL_ Daempfer SG_ 1716 VIN_14 2000;
BA_REL_ "GenSigTimeoutTime" BU_SG_REL_ Daempfer SG_ 1716 VIN_1 2000;
BA_REL_ "GenSigTimeoutTime" BU_SG_REL_ Daempfer SG_ 1716 VIN_8 2000;
BA_REL_ "GenSigTimeoutTime" BU_SG_REL_ Daempfer SG_ 1716 VIN_15 2000;
BA_REL_ "GenSigTimeoutTime" BU_SG_REL_ Daempfer SG_ 1716 VIN_2 2000;
BA_REL_ "GenSigTimeoutTime" BU_SG_REL_ Daempfer SG_ 1716 VIN_9 2000;
BA_REL_ "GenSigTimeoutTime" BU_SG_REL_ Daempfer SG_ 1716 VIN_16 2000;
BA_REL_ "GenSigTimeoutTime" BU_SG_REL_ Daempfer SG_ 1716 VIN_3 2000;
BA_REL_ "GenSigTimeoutTime" BU_SG_REL_ Daempfer SG_ 1716 VIN_10 2000;
BA_REL_ "GenSigTimeoutTime" BU_SG_REL_ Daempfer SG_ 1716 VIN_17 2000;
BA_REL_ "GenSigTimeoutTime" BU_SG_REL_ Gateway_MQB SG_ 2600468499 NM_ABS_Car_Wakeup 2000;
BA_REL_ "GenSigTimeoutTime" BU_SG_REL_ Gateway_MQB SG_ 2600468498 NM_Lenkhilfe_Car_Wakeup 2000;
BA_REL_ "GenSigTimeoutTime" BU_SG_REL_ Gateway_MQB SG_ 1175 PH_StartStopp_Info 1000;
BA_REL_ "GenSigTimeoutTime" BU_SG_REL_ Gateway_MQB SG_ 1355 PDC_Charisma_Status 5000;
BA_REL_ "GenSigTimeoutTime" BU_SG_REL_ Gateway_MQB SG_ 1355 PDC_Charisma_FahrPr 5000;
BA_REL_ "GenSigTimeoutTime" BU_SG_REL_ Gateway_MQB SG_ 1174 PLS_Anf_Anz 1000;
BA_REL_ "GenSigTimeoutTime" BU_SG_REL_ Gateway_MQB SG_ 1166 PLA_Anf_Anzeigemodus 1000;
BA_REL_ "GenSigTimeoutTime" BU_SG_REL_ Lenkhilfe_EPS SG_ 1601 Motor_Code_01_CRC 5000;
BA_REL_ "GenSigTimeoutTime" BU_SG_REL_ Lenkhilfe_EPS SG_ 1601 Motor_Code_01_BZ 5000;
BA_REL_ "GenSigTimeoutTime" BU_SG_REL_ Lenkhilfe_EPS SG_ 1601 MO_Faktor_Momente_02 5000;
BA_REL_ "GenSigTimeoutTime" BU_SG_REL_ Lenkhilfe_EPS SG_ 1601 MO_Hybridfahrzeug 5000;
BA_REL_ "GenSigTimeoutTime" BU_SG_REL_ Lenkhilfe_EPS SG_ 1601 MO_StartStopp_Codiert 5000;
BA_REL_ "GenSigTimeoutTime" BU_SG_REL_ Lenkhilfe_EPS SG_ 2600468499 NM_ABS_NM_State 2000;
BA_REL_ "GenSigTimeoutTime" BU_SG_REL_ Lenkhilfe_EPS SG_ 2600468496 NM_Gateway_NM_State 2000;
BA_REL_ "GenSigTimeoutTime" BU_SG_REL_ Lenkhilfe_EPS SG_ 2600468498 NM_Lenkhilfe_NM_State 2000;
BA_REL_ "GenSigTimeoutTime" BU_SG_REL_ Lenkhilfe_EPS SG_ 2600468585 NM_Rearview_NM_State 2000;
BA_REL_ "GenSigTimeoutTime" BU_SG_REL_ Lenkhilfe_EPS SG_ 304 PLA_01_CRC 5000;
BA_REL_ "GenSigTimeoutTime" BU_SG_REL_ Lenkhilfe_EPS SG_ 304 PLA_01_BZ 5000;
BA_REL_ "GenSigTimeoutTime" BU_SG_REL_ Lenkhilfe_EPS SG_ 304 PLA_LW_Soll 5000;
BA_REL_ "GenSigTimeoutTime" BU_SG_REL_ Lenkhilfe_EPS SG_ 304 PLA_VZ_LW_Soll 5000;
BA_REL_ "GenSigTimeoutTime" BU_SG_REL_ Lenkhilfe_EPS SG_ 304 PLA_Status_PLA_EPS 5000;
BA_REL_ "GenSigTimeoutTime" BU_SG_REL_ Lenkhilfe_EPS SG_ 1413 SI_NWDF 5000;
BA_REL_ "GenSigTimeoutTime" BU_SG_REL_ Lenkhilfe_EPS SG_ 1413 SI_NWDF_gueltig 5000;
BA_REL_ "GenSigTimeoutTime" BU_SG_REL_ Lenkhilfe_EPS SG_ 1716 VIN_01_MUX 2000;
BA_REL_ "GenSigTimeoutTime" BU_SG_REL_ Lenkhilfe_EPS SG_ 1716 VIN_14 2000;
BA_REL_ "GenSigTimeoutTime" BU_SG_REL_ Lenkhilfe_EPS SG_ 1716 VIN_15 2000;
BA_REL_ "GenSigTimeoutTime" BU_SG_REL_ Lenkhilfe_EPS SG_ 1716 VIN_16 2000;
BA_REL_ "GenSigTimeoutTime" BU_SG_REL_ Lenkhilfe_EPS SG_ 1716 VIN_17 2000;
BA_REL_ "GenSigTimeoutTime" BU_SG_REL_ PDC SG_ 2527679498 Perso_Kontonummer 5000;
BA_REL_ "GenSigTimeoutTime" BU_SG_REL_ PDC SG_ 2527679498 Perso_Steuerung 5000;
BA_REL_ "GenSigTimeoutTime" BU_SG_REL_ PDC SG_ 2527679498 Perso_Steuerungsparameter 5000;
BA_REL_ "GenSigTimeoutTime" BU_SG_REL_ PDC SG_ 2527679498 Perso_Status 5000;
BA_REL_ "GenSigTimeoutTime" BU_SG_REL_ PDC SG_ 695 RCTA_Status 500;
BA_REL_ "GenSigTimeoutTime" BU_SG_REL_ PDC SG_ 695 RCTA_Warnton 500;
BA_REL_ "GenSigTimeoutTime" BU_SG_REL_ PDC SG_ 1413 SI_NWDF 5000;
BA_REL_ "GenSigTimeoutTime" BU_SG_REL_ PDC SG_ 1413 SI_NWDF_gueltig 5000;
BA_REL_ "GenSigTimeoutTime" BU_SG_REL_ PDC SG_ 1413 SI_T_Schutz 5000;
BA_REL_ "GenSigTimeoutTime" BU_SG_REL_ PDC_PLA SG_ 2527679498 Perso_Kontonummer 5000;
BA_REL_ "GenSigTimeoutTime" BU_SG_REL_ PDC_PLA SG_ 2527679498 Perso_Steuerung 5000;
BA_REL_ "GenSigTimeoutTime" BU_SG_REL_ PDC_PLA SG_ 2527679498 Perso_Steuerungsparameter 5000;
BA_REL_ "GenSigTimeoutTime" BU_SG_REL_ PDC_PLA SG_ 2527679498 Perso_Status 5000;
BA_REL_ "GenSigTimeoutTime" BU_SG_REL_ PDC_PLA SG_ 695 RCTA_Info_rechts 500;
BA_REL_ "GenSigTimeoutTime" BU_SG_REL_ PDC_PLA SG_ 695 RCTA_Info_links 500;
BA_REL_ "GenSigTimeoutTime" BU_SG_REL_ PDC_PLA SG_ 695 RCTA_Status 500;
BA_REL_ "GenSigTimeoutTime" BU_SG_REL_ PDC_PLA SG_ 695 RCTA_Warnton 500;
BA_REL_ "GenSigTimeoutTime" BU_SG_REL_ PDC_PLA SG_ 1413 SI_NWDF 5000;
BA_REL_ "GenSigTimeoutTime" BU_SG_REL_ PDC_PLA SG_ 1413 SI_NWDF_gueltig 5000;
BA_REL_ "GenSigTimeoutTime" BU_SG_REL_ PDC_PLA SG_ 1413 SI_T_Schutz 5000;
VAL_ 1601 MO_Faktor_Momente_02 0 "nicht_belegt" ;
VAL_ 1601 MO_Hybridfahrzeug 0 "kein_Hybridfahrzeug" 1 "Mild_Hybrid" 2 "Full_Hybrid" 3 "PlugIn_Hybrid" ;
VAL_ 1601 MO_Getriebe_Code 0 "Init" 2 "DL501" 3 "DL800" 4 "VL381" 5 "DL382_Front" 6 "DL382_Allrad" 7 "DL702" 8 "AL552_Allrad" 9 "AL552_Front" 10 "AL651" 11 "AL551__AL951__AL1000_8A" 12 "PDK_PAG" 13 "AL551_Hybrid" 15 "Handschalter_konventionell" 16 "AQ250_160" 17 "AQ450" 18 "DQ200" 19 "DQ250" 20 "DQ500" 21 "SQ100" 22 "SQ200" 23 "DQ400E" 24 "DQ381" 25 "AL550" 31 "DL800E" 32 "Single_Gear__ohne_GSG_WH_am_MSG" ;
VAL_ 1601 MO_StartStopp_Codiert 0 "Start_Stopp_nicht_verbaut" 1 "Start_Stopp_verbaut" ;
VAL_ 1601 MO_Anzeige_StSt_gueltig 0 "MO_Text_Motorstart_gueltig" 1 "Signale_MO_Anzeige_StSt_gueltig" ;
VAL_ 1601 MO_Anzahl_Zyl 0 "kein_Zylinder" 1 "1_Zylinder" 2 "2_Zylinder" 3 "3_Zylinder" 4 "4_Zylinder" 5 "5_Zylinder" 6 "6_Zylinder" 7 "7_Zylinder" 8 "8_Zylinder" 9 "9_Zylinder" 10 "10_Zylinder" 11 "11_Zylinder" 12 "12_Zylinder" 13 "15_Zylinder" 14 "16_Zylinder" 15 "18_Zylinder" ;
VAL_ 1601 MO_Kraftstoffart 0 "Diesel" 1 "Benzin_inkl_E25_E85" 2 "CNG" 3 "LPG" 4 "Wasserstoff" 5 "E100_Ethanol" 15 "kein_Verbrennungskraftstoff" ;
VAL_ 1601 MO_Ansaugsystem 0 "Turbo" 1 "Sauger" ;
VAL_ 1601 MO_OBD_Typ 0 "NoOBD_RdW" 1 "EOBD" 2 "US_OBD" 3 "reserviert" ;
VAL_ 1601 MO_DPF_verbaut 0 "kein_DPF_verbaut" 1 "DPF_verbaut" ;
VAL_ 1601 TSK_Codierung 0 "kein_Fahrgeschwindigkeitsregler" 1 "GRA" 2 "GRA_Plus" 3 "Basis_ACC" 4 "ACC_Follow_to_Stop" 5 "ACC_Stop_and_Go" 7 "Codierung_in_Plausibilisierungsphase" ;
VAL_ 2600468499 NM_ABS_SNI 19 "ABS" ;
VAL_ 2600468499 NM_ABS_NM_State 1 "NM_RM_aus_BSM" 2 "NM_RM_aus_PBSM" 4 "NM_NO_aus_RM" 8 "NM_NO_aus_RS" ;
VAL_ 2600468499 NM_ABS_Car_Wakeup 0 "Inaktiv" 1 "Car_Wakeup" ;
VAL_ 2600468499 NM_ABS_Wakeup 0 "Peripherie_Wakeup__Ursache_nicht_bekannt" 1 "Bus_Wakeup" 2 "KL15_HW" 3 "Schalter_EPB" ;
VAL_ 2600468499 NM_ABS_NM_aktiv_KL15 0 "Inaktiv" 1 "KL15_EIN" ;
VAL_ 2600468499 NM_ABS_NM_aktiv_Diagnose 0 "Init" 1 "Diagnose_aktiv" ;
VAL_ 2600468499 NM_ABS_NM_aktiv_Tmin 0 "Inaktiv" 1 "Mindestaktivzeit" ;
VAL_ 2600468499 NM_ABS_NM_aktiv_v_gr_0 1 "kein_Stillstand_aller_Raeder_erkannt" ;
VAL_ 2600468499 NM_ESP_NM_aktiv_Anzeige_EPB 1 "Anzeige_EPB_Lampe" ;
VAL_ 2600468499 NM_ABS_UDS_CC 0 "Init" 1 "CC_aktiv" ;
VAL_ 2600468496 NM_Gateway_SNI 16 "Gateway" ;
VAL_ 2600468496 NM_Gateway_NM_State 1 "NM_RM_aus_BSM" 2 "NM_RM_aus_PBSM" 4 "NM_NO_aus_RM" 8 "NM_NO_aus_RS" 16 "NM_RM_aus_RS" 32 "NM_RM_aus_NO" ;
VAL_ 2600468496 NM_Gateway_Car_Wakeup 0 "Inaktiv" 1 "Car_Wakeup" ;
VAL_ 2600468496 NM_Gateway_Wakeup 0 "Peripherie_Wakeup__Ursache_nicht_bekannt" 1 "Bus_Wakeup" 2 "KL15_HW" 3 "ACAN_Wakeup" 4 "FCAN_Wakeup" 5 "KCAN_Wakeup" 6 "ICAN_Wakeup" 7 "DiagCAN_Wakeup" 8 "ECAN_Wakeup" 9 "Energie_LIN_Wakeup" 10 "Bedien_LIN_Wakeup" 11 "HybridCAN_Wakeup" 12 "Flexray_Wakeup" 13 "MFL_WakeUp" 14 "Ethernet" 15 "DCAN_Wakeup" 16 "K2CAN_Wakeup" 128 "Energiemanagement" 129 "Funktionswakeup_OBDC" 130 "Hochvoltenergiemanagement" 131 "CWU_empfangen" 132 "Fuer_Bus_relevanten_FC_empfangen" 133 "OnlineDienst_empfangen" 134 "HV_Aktivieren" 135 "HV_Deaktivieren" ;
VAL_ 2600468496 NM_Gateway_NM_aktiv_KL15 0 "Inaktiv" 1 "KL15_EIN" ;
VAL_ 2600468496 NM_Gateway_NM_aktiv_Diagnose 0 "Init" 1 "Diagnose_aktiv" ;
VAL_ 2600468496 NM_Gateway_NM_aktiv_Tmin 0 "Inaktiv" 1 "Mindestaktivzeit" ;
VAL_ 2600468496 NM_Gateway_ACAN_Aktivitaet 1 "ACAN_Aktivitaet" ;
VAL_ 2600468496 NM_Gateway_FCAN_Aktivitaet 1 "FCAN_Aktivitaet" ;
VAL_ 2600468496 NM_Gateway_KCAN_Aktivitaet 1 "KCAN_Aktivitaet" ;
VAL_ 2600468496 NM_Gateway_ICAN_Aktivitaet 1 "ICAN_Aktivitaet" ;
VAL_ 2600468496 NM_Gateway_DiagCAN_Aktivitaet 1 "DiagCAN_Aktivitaet" ;
VAL_ 2600468496 NM_Gateway_ECAN_Aktivitaet 1 "ECAN_Aktivitaet" ;
VAL_ 2600468496 NM_Gateway_EnergieLIN_Aktivitaet 1 "Energie_LIN_Aktivitaet" ;
VAL_ 2600468496 NM_Gateway_Bedien_LIN_Aktivitaet 1 "Bedien_LIN_Aktivitaet" ;
VAL_ 2600468496 NM_Gateway_EM_Aktivitaet 1 "EM_Aktivitaet" ;
VAL_ 2600468496 NM_Gateway_KS_Aktivitaet 1 "KS_Aktivitaet" ;
VAL_ 2600468496 NM_Gateway_HVEM_aktiv 0 "Init" 1 "Hochvoltenergiemanagement" ;
VAL_ 2600468496 NM_Gateway_NL_EM 1 "Energiemanagement" ;
VAL_ 2600468496 NM_Gateway_NL_Shutdown 1 "Shutdown" ;
VAL_ 2600468496 NM_Gateway_NL_Spg_Messung 1 "Spannungsmessung" ;
VAL_ 2600468496 NM_Gateway_NL_Wakeup_Monitor 1 "Wakeup_Monitor" ;
VAL_ 2600468496 NM_Gateway_UDS_CC 0 "Init" 1 "CC_aktiv" ;
VAL_ 2600468498 NM_Lenkhilfe_SNI 18 "Lenkhilfe" ;
VAL_ 2600468498 NM_Lenkhilfe_NM_State 1 "NM_RM_aus_BSM" 2 "NM_RM_aus_PBSM" 4 "NM_NO_aus_RM" 8 "NM_NO_aus_RS" ;
VAL_ 2600468498 NM_Lenkhilfe_Car_Wakeup 0 "Inaktiv" 1 "Car_Wakeup" ;
VAL_ 2600468498 NM_Lenkhilfe_Wakeup 0 "Peripherie_Wakeup__Ursache_nicht_bekannt" 1 "Bus_Wakeup" 2 "KL15_HW" ;
VAL_ 2600468498 NM_Lenkhilfe_NM_aktiv_KL15 0 "Inaktiv" 1 "KL15_EIN" ;
VAL_ 2600468498 NM_Lenkhilfe_NM_aktiv_Diagnose 0 "Init" 1 "Diagnose_aktiv" ;
VAL_ 2600468498 NM_Lenkhilfe_NM_aktiv_Tmin 0 "Inaktiv" 1 "Mindestaktivzeit" ;
VAL_ 2600468498 NM_Lenkhilfe_NM_aktiv_v_gr_7 1 "v_groesser_7" ;
VAL_ 2600468498 NM_Lenkhilfe_NM_aktiv_DZ_gr_300 1 "DZ_groesser_300" ;
VAL_ 2600468498 NM_Lenkhilfe_NM_aktiv_Handlenkmo 1 "Handlenkmoment" ;
VAL_ 2600468498 NM_Lenkhilfe_NM_aktiv_Post_Run 1 "Post_Run" ;
VAL_ 2600468498 NM_Lenkhilfe_NM_aktiv_Fahrbereit 0 "keine_Fahrbereitschaft_erkannt" 1 "Fahrbereitsschaft_erkannt" ;
VAL_ 2600468498 NM_Lenkhilfe_UDS_CC 0 "Init" 1 "CC_aktiv" ;
VAL_ 2600468585 NM_Rearview_SNI 105 "Rearview" ;
VAL_ 2600468585 NM_Rearview_NM_State 0 "Init" 1 "NM_RM_aus_BSM" 2 "NM_RM_aus_PBSM" 4 "NM_NO_aus_RM" 8 "NM_NO_aus_RS" 16 "NM_RM_aus_RS" 32 "NM_RM_aus_NO" ;
VAL_ 2600468585 NM_Rearview_Car_Wakeup 0 "Inaktiv" 1 "Car_Wakeup" ;
VAL_ 2600468585 NM_Rearview_Wakeup 0 "Peripherie_Wakeup__Ursache_nicht_bekannt" 1 "Bus_Wakeup" 2 "KL15_HW" ;
VAL_ 2600468585 NM_Rearview_NM_aktiv_KL15 0 "Inaktiv" 1 "KL15_EIN" ;
VAL_ 2600468585 NM_Rearview_NM_aktiv_Diagnose 0 "Init" 1 "Diagnose_aktiv" ;
VAL_ 2600468585 NM_Rearview_NM_aktiv_Tmin 0 "Inaktiv" 1 "Mindestaktivzeit" ;
VAL_ 2600468585 NM_Rearview_UDS_CC 0 "Init" 1 "CC_aktiv" ;
VAL_ 913 MO_Servicemodus 0 "nicht_aktiv" 1 "Service_Mode_1" 2 "Service_Mode_2" 3 "Service_Mode_3" 4 "Service_Mode_4" 5 "Service_Mode_5" 6 "Service_Mode_6" 7 "Service_Mode_7" 8 "Service_Mode_8" 9 "Service_Mode_9" 10 "Service_Mode_10" 11 "Service_Mode_11" 12 "Service_Mode_12" 13 "Service_Mode_13" 14 "Service_Mode_14" 15 "Service_Mode_15" ;
VAL_ 913 MO_QBit_Aussen_Temp 0 "gueltiger_Wert" 1 "Ersatz_Init_oder_Fehlerwert" ;
VAL_ 913 OBD_Sperrung_IUMPR 0 "IUMPR_Berechnung_freigegeben" 1 "IUMPR_Berechnung_gesperrt" ;
VAL_ 913 OBD_Kaltstart_Denominator 0 "Denominator_nicht_hochzaehlen" 1 "Bedingungen_zum_Inkr_des_Kaltstart_Denom_erf" ;
VAL_ 913 OBD_Minimum_Trip 0 "kein_Min_Normed_Trip" 1 "Min_Normed_Trip" ;
VAL_ 913 OBD_Driving_Cycle 0 "kein Driving Cycle erkannt" 1 "DC erkannt" ;
VAL_ 913 OBD_Warm_Up_Cycle 0 "kein Warm Up Cycle erkannt" 1 "Warm Up Cycle erkannt" ;
VAL_ 913 OBD_Normed_Trip 0 "kein Normed Trip" 1 "Normed Trip erfüllt" ;
VAL_ 1175 PH_Visualisierung 0 "Aus" 1 "Angefragt" 2 "InAnzeige" 3 "Abgefordert" 6 "Init" 7 "Fehler" ;
VAL_ 1175 PDC_Tonausgabe_Front 0 "kein_Ton" 1 "Intervallton_1" 2 "Intervallton_2" 3 "Intervallton_3" 4 "Intervallton_4" 5 "Intervallton_5" 6 "Dauerton" 7 "Fehlerton" 8 "RCTATon" ;
VAL_ 1175 PDC_Tonausgabe_Heck 0 "kein_Ton" 1 "Intervallton_1" 2 "Intervallton_2" 3 "Intervallton_3" 4 "Intervallton_4" 5 "Intervallton_5" 6 "Dauerton" 7 "Fehlerton" 8 "Erstwarnton_hinten" 9 "RCTATon" ;
VAL_ 1175 PH_nachtr_Stopp_Anf 0 "nicht_angefordert" 1 "angefordert" ;
VAL_ 1175 PH_Abschaltursache 0 "keine, bzw. System aktiv" 1 "Abschaltung durch Herausnahme R-Gang" 2 "Abschaltung ueber Geschwindigkeit" 3 "Abschaltung ueber PDC-Taster" 4 "Abschaltung wegen PLA" 5 "Abschaltung durch KL 15 Bit = 0" 6 "tbd." 7 "Fehler-/gestört Zustand, System noch aktiv" ;
VAL_ 1175 PH_Opt_Anzeige_V_ein 0 "optische Anzeige vorne nicht aktiv" 1 "optische Anzeige vorne aktiviert" ;
VAL_ 1175 PH_Opt_Anzeige_H_ein 0 "Optische Anzeige aus" 1 "optische Anzeige hinten aktiviert" ;
VAL_ 1175 PH_Opt_Anz_V_Hindernis 0 "optische Anzeige vorne meldet kein Hindernis" 1 "optische Anzeige vorne meldet Hindernis im Warnbereich" ;
VAL_ 1175 PH_Opt_Anz_H_Hindernis 0 "optische Anzeige hinten meldet kein Hindernis" 1 "optische Anzeige hinten meldet Hindernis im Warnbereich" ;
VAL_ 1175 PH_Tongeber_V_aktiv 0 "Tongeber vorne nicht aktiv" 1 "Tongeber vorne  aktiv" ;
VAL_ 1175 PH_Tongeber_H_aktiv 0 "Tongeber hinten nicht aktiv" 1 "Tongeber hinten aktiv" ;
VAL_ 1175 PH_Tongeber_mute 0 "Tongeber nicht stummgeschaltet" 1 "Tongeber stummgeschaltet" ;
VAL_ 1175 PH_Anf_Audioabsenkung 0 "keine Absenkung der Lautstärke" 1 "Anforderung an das Audiosystem für Absenkung der Lautstärke" ;
VAL_ 1175 PH_Tongeber_H_verfuegbar 0 "nicht verfügbar" 1 "verfügbar" ;
VAL_ 1175 PLA_Anf_Aufschaltung_RVC 0 "Keine_RVC_Aufschalteanf" 1 "RVC_Aufschalteanforderung" ;
VAL_ 1175 PH_Taster 0 "Taster_nicht_gedrueckt" 1 "Taster_gedrueckt" 2 "reserviert" 3 "Fehler" ;
VAL_ 1175 PH_Anf_Verdeck 0 "Verdeckbetrieb_freigegeben" 1 "Verdeckbetrieb_sperren" 2 "reserviert" 3 "reserviert" ;
VAL_ 1175 PH_StartStopp_Info 0 "Motorlauf_nicht_notwendig_(Stoppfreigabe)" 1 "Motoranlauf_nicht_zwingend_notwendig_(Stoppverbot,keine_Startanforderung)" 2 "Motoranlauf_zwingend_notwendig_(Startanforderung)" 3 "Systemfehler" ;
VAL_ 1175 PH_Stoermeldung 0 "keine_Anzeige_kein_Gong" 1 "Textmeldung_PDC_hinten_gestoert_mit_Gong" 2 "Textmeldung_PDC_hinten_gestoert_ohne_Gong" 3 "Textmeldung_PDC_vorn_gestoert_mit_Gong" 4 "Textmeldung_PDC_vorn_gestoert_ohne_Gong" 5 "Textmeldung_PDC_gestoert_mit_Gong" 6 "Textmeldung_PDC_gestoert_ohne_Gong" 7 "Textmeldung_PDC_seitlich_gestoert_mit_Gong" 8 "Textmeldung_PDC_seitlich_gestoert_ohne_Gong" ;
VAL_ 1175 PH_defekt 0 "PH aktiv" 1 "PH wurde aufgrund eines Defektes deaktiviert" ;
VAL_ 1175 PH_gestoert 0 "PH aktiv" 1 "PH wurde auf Grund einer Stoerung tempraer deaktiviert" ;
VAL_ 1175 PH_Systemzustand 0 "Anlage aus" 1 "Anlage durch einlegen R-Gang aktiviert" 2 "Anlage manuell durch Taster aktiviert" 3 "Anlage automatisch aktiviert" 4 "Anlage durch ARA aktiviert" 6 "Init - Initialisierungsphase nach Kl. 15 ein / Reset" 7 "Fehler-/gestört Zustand, System noch aktiv" ;
VAL_ 1175 PH_Display_Kundenwunsch 0 "Anzeige aus" 1 "Grafik" 2 "Rear View" 3 "automatisch" ;
VAL_ 1355 PH_Verschmutzungsmeldung 0 "keine_Anzeige_kein_Gong" 1 "Textmeldung_PDC_hinten_verschmutzt_mit_Gong" 2 "Textmeldung_PDC_hinten_verschmutzt_ohne_Gong" 3 "Textmeldung_PDC_vorn_verschmutzt_mit_Gong" 4 "Textmeldung_PDC_vorn_verschmutzt_ohne_Gong" 5 "Textmeldung_PDC_verschmutzt_mit_Gong" 6 "Textmeldung_PDC_verschmutzt_ohne_Gong" 7 "Textmeldung_PDC_seitlich_verschmutzt_mit_Gong" 8 "Textmeldung_PDC_seitlich_verschmutzt_ohne_Gong" ;
VAL_ 1355 PH_Aufschaltursache 0 "Anlage aus" 1 "Anlage durch einlegen R-Gang aktiviert" 2 "Anlage manuell durch Taster aktiviert" 3 "Anlage automatisch aktiviert" 4 "Anlage durch ARA aktiviert" 5 "Rueckwaertsrollen" 6 "Anlage_durch_PLA_aktiviert" 7 "Anlage_durch_IPA_aktiviert" 8 "Anlage_durch_FA_aktiviert" 9 "Anlage_durch_RBF_oder_MA_aktiviert" 10 "Anlage_durch_Smartphone_aktiviert" 11 "Anlage_durch_Jokertaste_aktiviert" 12 "Anlage_durch_Favoritentasten_aktiviert" 13 "Anlage_durch_SideViewTaster_aktiviert" 14 "Anlage_durch_RCTA_aktiviert" 15 "Anlage_durch_KAS_aktiviert" 16 "Anlage_durch_AWC_aktiviert" 30 "Init_Initialisierungsphase_nach_Kl_15_ein_oder_Reset" 31 "Fehler_gestoerter_Zustand_System_noch_aktiv" ;
VAL_ 1355 PDC_Charisma_Status 0 "Init" 1 "verfuegbar" 2 "nicht_verfuegbar" 3 "asynchron_durch_Fahrerwunsch" ;
VAL_ 1355 PDC_Charisma_FahrPr 0 "keine_Funktion" 1 "Programm_1" 2 "Programm_2" 3 "Programm_3" 4 "Programm_4" 5 "Programm_5" 6 "Programm_6" 7 "Programm_7" 8 "Programm_8" 9 "Programm_9" 10 "Programm_10" 11 "Programm_11" 12 "Programm_12" 13 "Programm_13" 14 "Programm_14" 15 "Programm_15" ;
VAL_ 1351 US_Objekt_links 0 "Init" 1 "Objekt_erkannt" 2 "Kein_Objekt_erkannt" ;
VAL_ 1351 US_Objekt_rechts 0 "Init" 1 "Objekt_erkannt" 2 "Kein_Objekt_erkannt" ;
VAL_ 1351 US_Objektueberwachung_Status 0 "Passiv" 1 "Aktiv" 3 "Fehler" ;
VAL_ 2527679498 Perso_Kontonummer 0 "kein_Benutzerkonto" 1 "Benutzerkonto_1" 2 "Benutzerkonto_2" 3 "Benutzerkonto_3" 4 "Benutzerkonto_4" 5 "Benutzerkonto_5" 6 "Benutzerkonto_6" 7 "Benutzerkonto_7" ;
VAL_ 2527679498 Perso_Steuerung 0 "keine_Steuerung" 1 "Reset_alle_Konten" 2 "Reset_aktives_Konto" 3 "Kopiere_aktives_Konto_nach" 4 "Wiederherstellen_aktives_Konto" ;
VAL_ 2527679498 Perso_Steuerungsparameter 0 "kein_Parameter" 1 "Benutzerkonto_1" 2 "Benutzerkonto_2" 3 "Benutzerkonto_3" 4 "Benutzerkonto_4" 5 "Benutzerkonto_5" 6 "Benutzerkonto_6" 7 "Benutzerkonto_7" ;
VAL_ 2527679498 Perso_Status 0 "deaktiviert" 1 "aktiviert" ;
VAL_ 2527679498 Perso_Bedienstelle 0 "Init" 1 "Kombiinstrument" 2 "ABT" ;
VAL_ 2527679498 Perso_Freigabe_Verstellung 0 "Init" 1 "freigegeben" ;
VAL_ 2527679498 Perso_Aktiv 0 "deaktiviert" 1 "aktiviert" ;
VAL_ 304 PLA_Status_PLA_ESP 0 "PLA_ESP_Deaktiv" 1 "PLA_ESP_Init" 2 "PLA_ESP_Fehler" 3 "reserviert" 4 "PLA_ESP_aktivierbar" 5 "reserviert" 6 "PLA_ESP_Bremse_aktiv" 7 "reserviert" 8 "PLA_ESP_funktionsbereit" 9 "PLA_ESP_Neustart" 10 "PLA_ESP_Abbruch" 11 "reserviert" 12 "reserviert" 13 "reserviert" 14 "reserviert" 15 "reserviert" ;
VAL_ 304 PLA_VZ_LW_Soll 0 "positiv" 1 "negativ" ;
VAL_ 304 PLA_Status_PLA_EPS 0 "reserviert" 1 "reserviert" 2 "reserviert" 3 "reserviert" 4 "PLA_EPS_aktivierbar" 5 "reserviert" 6 "PLA_EPS_Lenkwinkel_aktiv" 7 "reserviert" 8 "PLA_EPS_funktionsbereit" 9 "PLA_EPS_Neustart" 10 "PLA_EPS_Abbruch" 11 "reserviert" 12 "reserviert" 13 "reserviert" 14 "reserviert" 15 "reserviert" ;
VAL_ 304 PLA_Bremsmoment 8191 "Fehler" ;
VAL_ 304 PLA_Bremsverzoegerung 126 "Init" 127 "Fehler" ;
VAL_ 304 PLA_Anf_Bremsverzoegerung 0 "keine_Bremsverzoegerung" 1 "Bremsverzoegerung" ;
VAL_ 304 PLA_BremsMom_Verzoeg 0 "Bremsmoment" 1 "Bremsverzoegerung" ;
VAL_ 304 PLA_Anhalten 0 "kein_anhalten_gewuenscht" 1 "anhalten_erwuenscht" ;
VAL_ 304 PLA_Anhalteweg 0 "Inaktiv" 2046 "Init" 2047 "Fehler" ;
VAL_ 304 PLA_01_Signal_red_cyclic 0 "Langsame_Zykluszeit_aktiv" 1 "Schnelle_Zykluszeit_aktiv" ;
VAL_ 1174 PLS_Anf_Anz 0 "keine_Anforderung" 1 "Anzeige_Anforderung" ;
VAL_ 1174 PLS_Kurze_Luecke 0 "keine_Kurze_Luecke" 1 "Kurze_Luecke" ;
VAL_ 1174 PLS_Laengs_Querluecke 0 "Laengsluecke" 1 "Querluecke" ;
VAL_ 1174 PLS_Anf_Anz_Schwellpfeil 0 "Anzeige_Schwellpfeil_aus" 1 "Anzeige_Schwellpfeil_ein" ;
VAL_ 1174 PLS_Fahrtrichtg_Mehrzg 0 "vorwaerts" 1 "rueckwaerts" ;
VAL_ 1174 PLS_Bremssymbol 0 "keine_Anzeige" 1 "Anzeige_Bremssymbol" ;
VAL_ 1174 PLS_PL_Exist 0 "keine_Parkluecke" 1 "Parkluecke" ;
VAL_ 1174 PLS_Standby 0 "keine_Anzeige" 1 "Anzeige_des_Standby_Symbols" ;
VAL_ 1174 PLS_Mehrzg_Aktiv 0 "nicht_aktiv" 1 "aktiv" ;
VAL_ 1174 PLS_Pos_OK 0 "Pos_NOK" 1 "Pos_OK" ;
VAL_ 1174 PLS_PL_Seite 0 "rechts" 1 "links" ;
VAL_ 1174 PLS_Lenk_Aktiv_Hinweis 0 "keine_Info" 1 "Lenkeingriff_aktiv" ;
VAL_ 1174 PLS_Texte 0 "keine_Meldung" 1 "ParkAssist_deaktiviert__Funktion_ohne_vorherigem_Lenkeingriff_regulaer_beendet" 2 "ParkAssist_deaktiviert__Geschwindigkeit_zu_hoch" 3 "ParkAssist_deaktiviert__Eingriff_ASR_ohne_aktiviertem_Lenkeingriff" 4 "ParkAssist_deaktiviert__ASR_Ausgeschaltet" 5 "ParkAssist_deaktiviert__Anhaenger_vorhanden_ohne_aktiviertem_Lenkeingriff" 6 "ParkAssist_deaktiviert__Zeitlimit_ueberschritten" 7 "ParkAssist_deaktiviert__Systemstoerung_ohne_aktiviertem_Lenkeingriff" 8 "ParkAssist_deaktiviert__defekt_ohne_aktiviertem_Lenkeingriff" 9 "Stillstandszeit_nicht_ausreichend" 10 "Geschwindigkeit_zu_niedrig" 11 "Blinker_setzen_und_Rueckwaertsgang_einlegen__Ausparkfunktion" 12 "Automatisches_Ausparken_nicht_moeglich__Luecke_zu_klein" 13 "Geschwindigkeit_zu_hoch__bei_aktivem_Lenkeingriff" 14 "ParkAssist_beendet__Geschwindigkeit_zu_hoch" 15 "ParkAssist_deaktiviert__Lenkung_uebernehmen" 16 "ParkAssist_deaktiviert__Anhaenger__bei_aktiviertem_Lenkeingriff" 17 "ParkAssist_deaktiviert__ASR_ausgeschaltet__Lenkung_uebernehmen" 18 "ParkAssist_deaktiviert__Zeitlimit_ueberschritten_Lenkung_uebernehmen" 19 "Lenkeingriff_deaktiviert__Lenkung_uebernehmen" 20 "ParkAssist_deaktiviert__Lenkung_uebernehmen_Parkvorgang_manuell_beenden" 21 "ParkAssist_deaktiviert__Geschwindigkeit_zu_hoch__Lenkung_uebernehmen" 22 "ParkAssist_deaktiviert__Eingriff_ASR__Lenkung_uebernehmen" 23 "ParkAssist_deaktiviert__Systemstoerung" 24 "ParkAssist_deaktiviert__defekt" 25 "Bitte_Lenkung_uebernehmen_und_Fahrt_fortsetzen" 26 "Automatisches_Ausparken_nicht_moeglich__Luecke_zu_klein" 27 "ParkAssist__Bremseingriff__Geschwindigkeit_zu_hoch" 28 "Hindernis_erkannt__bitte_Bremse_betaetigen" 29 "Achtung__Bremse_öffnet" 30 "Achtung__Seitliches_Hindernis" 31 "ParkAssist_beendet__Lenkung_uebernehmen" 32 "Dauertonbereich_veraendert__besondere_Vorsicht_geboten" ;
VAL_ 1174 PLS_Schwellpfeil_rel 0 "kein_Segment_leer" 1 "1_Segment" 2 "2_Segmente" 3 "3_Segmente" 4 "4_Segmente" 5 "5_Segmente" 6 "6_Segmente" 7 "7_Segmente" 8 "8_Segmente" 9 "9_Segmente" 10 "10_Segmente" 11 "11_Segmente" 12 "12_Segmente" 13 "13_Segmente" 14 "14_Segmente" 15 "15_Segmente_voll" ;
VAL_ 1174 PLS_Schwellpfeil_abs 0 "3_Segmente__voll" 1 "2_Segmente" 2 "1_Segment" 3 "kein_Segment__togelt_in_Gegenrichtung" ;
VAL_ 1174 PLS_Ausparken_Aktiv 0 "Ausparken_nicht_aktiv" 1 "Ausparken_aktiv" ;
VAL_ 1174 PLS_Bremsleuchte 0 "Bremsleuchte_aus" 1 "Bremsleuchte_an" ;
VAL_ 1174 PLS_Akustik 0 "keine_Akustik" 1 "Akustik_1" 2 "Akustik_2" 3 "Akustik_3" ;
VAL_ 1166 PLA_Status_Aktive_Seite 0 "Rechts" 1 "Links" ;
VAL_ 1166 PLA_Anf_Anzeige_Mini 0 "keine_Anzeige" 1 "Miniaturanzeige" ;
VAL_ 1166 PLA_Mini_Modus 0 "kein_Mini_angezeigt" 1 "Mini_Laengsparken" 2 "Mini_Rueckwaerts_Querparken_mit_Vorbeifahrt" 3 "Mini_Vorwaerts_Querparken_ohne_VB" 4 "Mini_Vorwaerts_Querparken_mit_VB" 5 "weitere_Parkmoeglichkeit_vorhanden" 6 "Garagenparken" 7 "Mini_Rueckwaerts_Querparken_ohne_Vorbeifahrt" ;
VAL_ 1166 PLA_Anf_Akustik 0 "keine_Akustik" 1 "Akustik__Gong_1000" ;
VAL_ 1166 PLA_Anf_Anzeige_Schwellpfeil 0 "Keine_Schwellpfeilanzeige" 1 "Anzeige_Schwellpfeil" ;
VAL_ 1166 PLA_Anf_Anzeige_Bremsfuss 0 "Keine_Anzeige_Bremsfuss" 1 "Anzeige_Bremsfuss" ;
VAL_ 1166 PLA_Anf_Funktionsdisclaimer 0 "Laengsparken" 1 "Rueckwaerts_Querparken" 2 "Vorwaerts_Querparken" 3 "Ausparken_Laengsparken" ;
VAL_ 1166 PLA_Anf_Anzeigemodus 0 "Keine_Anzeige" 1 "Reserved" 2 "Laengsparken_Singlescreen" 3 "Reserved" 4 "Rueckwaerts_Querparken_mit_VB" 5 "Rueckwaerts_Querparken_ohne_VB" 6 "Vorwaerts_Querparken_ohne_VB" 7 "Vorwaerts_Querparken_mit_VB" 8 "Ausparken_Laengsparken_Single" 9 "Garagenparken_vorwaerts" 10 "Garagenparken_rueckwaerts" 11 "Textmeldung_hochprior" 12 "Textmeldungen_niederprior" 13 "Anzeige_beidseitig" 14 "Anzeige_PL_verfuegbar" 15 "Reserved" ;
VAL_ 1166 PLA_Anf_Meldungen 0 "keine_Meldung" ;
VAL_ 1166 PLA_Status_Funktion 0 "PL_Suche" 1 "PL_Suche_Standby" 2 "PL_gefunden" 3 "POS_OK" 4 "Rangieren_vorwaerts" 5 "Rangieren_rueckwaerts" 6 "Disclaimer_in_Anzeige" 7 "Automodus_Wand" 8 "PP_Pos_OK" 11 "GP_Pos_OK" 14 "DP_Pos_OK" ;
VAL_ 1166 PLA_Status_beenden_Mini 0 "Funktion_vorhanden" 1 "Funktion_ausgewaehlt" 2 "Funktion_einparken_moeglich" 3 "Funktion_nicht_vorhanden" ;
VAL_ 1166 PLA_Status_Laengsparken_Mini 0 "Funktion_vorhanden" 1 "Funktion_ausgewaehlt" 2 "Funktion_einparken_moeglich" 3 "Funktion_nicht_vorhanden" ;
VAL_ 1166 PLA_Status_QP_Rueckw_Mini 0 "Funktion_vorhanden" 1 "Funktion_ausgewaehlt" 2 "Funktion_einparken_moeglich" 3 "Funktion_nicht_vorhanden" ;
VAL_ 1166 PLA_Status_QP_Vorw_Mini 0 "Funktion_vorhanden" 1 "Funktion_ausgewaehlt" 2 "Funktion_einparken_moeglich" 3 "Funktion_nicht_vorhanden" ;
VAL_ 695 RCTA_Modus 0 "kein_Fehler_verfuegbar" 1 "Eingriffsmute" 2 "eingeschraenkt_Verfuegbar_pata2_Warnruck_etc" 3 "Anhaengerbetrieb" 4 "Init_nicht_codiert" 5 "keine_Sensorsicht_Blindheit" 6 "zur_Zeit_nicht_verfuegbar_temp_Fehler" 7 "Systemstoerung_dauer_Fehler" ;
VAL_ 695 RCTA_Kritikalitaetslevel_rechts 0 "unkritisch" 1 "Kritikalitaetslevel_1" 2 "Kritikalitaetslevel_2" 3 "Kritikalitaetslevel_3" 4 "Kritikalitaetslevel_4" 5 "Kritikalitaetslevel_5" 6 "reserviert" 7 "nicht_bewertbar" ;
VAL_ 695 RCTA_Kritikalitaetslevel_links 0 "unkritisch" 1 "Kritikalitaetslevel_1" 2 "Kritikalitaetslevel_2" 3 "Kritikalitaetslevel_3" 4 "Kritikalitaetslevel_4" 5 "Kritikalitaetslevel_5" 6 "reserviert" 7 "nicht_bewertbar" ;
VAL_ 695 RCTA_Info_rechts 0 "RCTA_hat_rechts_nichts_erkannt" 1 "RCTA_hat_rechts_blind_erkannt" 2 "RCTA_hat_rechts_frei_erkannt" 3 "RCTA_hat_rechts_unkritisch_erkannt" 4 "RCTA_hat_rechts_relevant_aber_unkritisch_erkannt" 5 "RCTA_hat_rechts_kritisch_erkannt" 6 "RCTA_hat_rechts_sehr_kritisch_erkannt" 7 "RCTA_meldet_rechts_Kollision_steht_bevor" ;
VAL_ 695 RCTA_Anforderung_HMS 0 "keine Anforderung" 1 "halten" 2 "parken" 3 "Halten Standby" 4 "anfahren" 5 "loesen_ueber_Rampe" ;
VAL_ 695 RCTA_Bremsruck_Anforderung 0 "nicht_angefordert" 1 "angefordert" ;
VAL_ 695 RCTA_Bremsruck_Freigabe 0 "keine_Freigabe" 1 "Freigabe" ;
VAL_ 695 RCTA_Info_links 0 "RCTA_hat_links_nichts_erkannt" 1 "RCTA_hat_links_blind_erkannt" 2 "RCTA_hat_links_frei_erkannt" 3 "RCTA_hat_links_unkritisch_erkannt" 4 "RCTA_hat_links_relevant_aber_unkritisch_erkannt" 5 "RCTA_hat_links_kritisch_erkannt" 6 "RCTA_hat_links_sehr_kritisch_erkannt" 7 "RCTA_meldet_links_Kollision_steht_bevor" ;
VAL_ 695 RCTA_Status 0 "Aus" 1 "Passiv" 2 "Aktiv" 3 "Fehler" ;
VAL_ 695 RCTA_Warnton 0 "Aus" 1 "Ein" ;
VAL_ 695 RCTA_Notbremsung_Freigabe 0 "keine_Freigabe" 1 "Freigabe" ;
VAL_ 695 RCTA_Notbremsung_Anforderung 0 "Init" 255 "Fehler" ;
VAL_ 1711 RV_Video_on 0 "Kamerabild wird nicht angezeigt" 1 "Kamerabild wird angezeigt" ;
VAL_ 1711 RV_Dark_Screen 0 "Kamerabild nicht verdunkeln" 1 "Kamerabild verdunkeln" ;
VAL_ 1711 RV_HMI_Mode 0 "Parkluecke  (Modus 1)" 1 "Parallel zur Straße (Modus 2)" 2 "reserviert" 3 "Kalibrierung (nur Diagnose)" ;
VAL_ 1711 RV_GL_side 0 "Guidelines_abgeschaltet" 1 "Guidelines_Anzeige_rechte_Seite" 2 "Guiedelines_Anzeige_linke_Seite" 3 "Guiedelines_Anzeige_beide_Seiten" ;
VAL_ 1711 RV_System_aktiv 0 "System nicht betriebsbereit" 1 "System betriebsbereit" ;
VAL_ 1711 RV_Reinigung_Anf 0 "nicht_reinigen" 1 "reinigen" ;
VAL_ 1711 RV_Settings_enabled 0 "Menu 'Einstellungen' nicht aktiviert" 1 "Menu 'Einstellungen' aktiviert" ;
VAL_ 1711 RV_Menu_Item 0 "HMI Mode als ausgewaehlt markiert" 1 "Helligkeit als ausgewaehlt markiert" 2 "Kontrast als ausgewaehlt markiert" 3 "Farbsaettigung als ausgewaehlt markiert" ;
VAL_ 1711 SV_Video_on 0 "SideView_aus_/_nicht_verbaut" 1 "SideView_an" ;
VAL_ 1711 RV_Calib_Fehler 0 "Kalibrierung_i.O." 1 "RearView_nicht_kalibriert" ;
VAL_ 1711 RV_GL_Trailer_connect 0 "Guidelines_werden_angezeigt" 1 "Guidelines_wegen_angekoppeltem_Anhänger_deaktiviert" ;
VAL_ 1711 RV_GL_Trunk_open 0 "Guidelines_werden_angezeigt" 1 "Guidelines_wegen_geöffneter_Heckklappe_deaktiviert" ;
VAL_ 1711 RV_GL_LWS_Fehler 0 "Guidelines_werden_angezeigt" 1 "Guidelines_wegen_nicht_kalibriertem_Lenkwinkelsensor_deaktiviert" ;
VAL_ 1610 RKA_Warnungen 0 "keine Anzeige" 1 "RD prüfen (P1-rot)" 2 "RD_VL (P1-rot)" 3 "RD_VR (P1-rot)" 4 "RD_HL (P1-rot)" 5 "RD_HR (P1-rot)" 6 "RD_RR (P2-gelb)" 7 "RD prüfen (P2-gelb)" 8 "reserviert" 9 "RD Systemstörung (P2-gelb)" 10 "RD_VL_(P2-gelb)" 11 "RD_VR_(P2-gelb)" 12 "RD_HL_(P2-gelb)" 13 "RD_HR_(P2-gelb)" ;
VAL_ 1610 RKA_FMVSS138_Lampe 0 "keine Warnung" 1 "Warnlampe FMVSS 138, gelbe Lampe statisch an" ;
VAL_ 1610 RKA_Druckwarnung_RdW 0 "rote Lampe aus" 1 "rote Lampe ein" ;
VAL_ 1610 RKA_Warnungen_02 0 "keine_Anzeige" 1 "Kontrollleuchte" 2 "Systemfehler" 3 "Reifen_allgemein_Warnstufe_1" 4 "Reifen_vorne_links_Warnstufe_1" 5 "Reifen_vorne_rechts_Warnstufe_1" 6 "Reifen_hinten_links_Warnstufe_1" 7 "Reifen_hinten_rechts_Warnstufe_1" 8 "Reifen_allgemein_Warnstufe_2" 9 "Reifen_vorne_links_Warnstufe_2" 10 "Reifen_vorne_rechts_Warnstufe_2" 11 "Reifen_hinten_links_Warnstufe_2" 12 "Reifen_hinten_rechts_Warnstufe_2" 13 "Reifen_allgemein_Warnstufe_3" 14 "Reifen_vorne_links_Warnstufe_3" 15 "Reifen_vorne_rechts_Warnstufe_3" 16 "Reifen_hinten_links_Warnstufe_3" 17 "Reifen_hinten_rechts_Warnstufe_3" 18 "Reifendruecke_kalibrieren" 19 "Akustik" 20 "Systemfehler_Lampe_Text" 21 "Reifen_allgemein_Lampe_Text" 22 "Reifen_vorne_links_Lampe_Text" 23 "Reifen_vorne_rechts_Lampe_Text" 24 "Reifen_hinten_links_Lampe_Text" 25 "Reifen_hinten_rechts_Lampe_Text" 26 "Reifendruecke_kalibrieren_Text_Gong" 27 "Reifendruecke_kalibrieren_Text_Gong_Lampe" ;
VAL_ 1610 RKA_KD_Fehler 0 "kein_KD_Fehler" 1 "KD_Fehler" ;
VAL_ 1710 SP_FT_oben 0 "nicht_betaetigt" 1 "betaetigt" ;
VAL_ 1710 SP_FT_unten 0 "nicht_betaetigt" 1 "betaetigt" ;
VAL_ 1710 SP_FT_links 0 "nicht_betaetigt" 1 "betaetigt" ;
VAL_ 1710 SP_FT_rechts 0 "nicht_betaetigt" 1 "betaetigt" ;
VAL_ 1710 SP_BT_oben 0 "nicht_betaetigt" 1 "betaetigt" ;
VAL_ 1710 SP_BT_unten 0 "nicht_betaetigt" 1 "betaetigt" ;
VAL_ 1710 SP_BT_links 0 "nicht_betaetigt" 1 "betaetigt" ;
VAL_ 1710 SP_BT_rechts 0 "nicht_betaetigt" 1 "betaetigt" ;
VAL_ 1710 SP_abklappen 0 "Spiegel_abklappen_nicht_aktiv" 1 "Spiegel_abklappen_aktiv" ;
VAL_ 1710 SP_anklappen 0 "Spiegle_anklappen_nicht_aktiv" 1 "Spiegel_anklappen_aktiv" ;
VAL_ 1710 SP_normieren 0 "Spiegel_nicht_normiert" 1 "Spiegel_normiert" ;
VAL_ 1710 SP_Spg_Verstellschalter_Fehler 0 "kein_Fehler" 1 "Fehler" ;
VAL_ 1710 SP_Hzg_Taster 0 "nicht_betaetigt" 1 "betaetigt" ;
VAL_ 1710 SP_S_oben 1 "Spiegelschalter in Stellung oben" ;
VAL_ 1710 SP_S_unten 1 "Spiegelschalter in Stellung unten" ;
VAL_ 1710 SP_S_links 1 "Spiegelschalter in Stellung links" ;
VAL_ 1710 SP_S_rechts 1 "Spiegelschalter in Stellung rechts" ;
VAL_ 1710 SP_Auswahl_li 1 "Spiegelschalter in Stellung Auswahl links" ;
VAL_ 1710 SP_Auswahl_re 1 "Spiegelschalter in Stellung Auswahl rechts" ;
VAL_ 1710 SP_ARA_Status 0 "TSG nicht im ARA-Modus" 1 "TSG im ARA-Modus" ;
VAL_ 1710 SP_S_Klappen 1 "Spiegelschalter in Stellung Klappen" ;
VAL_ 1413 SI_Sammel_SG_Fehler 61 "Reserviert" 62 "Overflow" 63 "ungueltig" ;
VAL_ 1413 SI_Diagnose_Aktiv 0 "inaktiv" 1 "aktiv" ;
VAL_ 1413 SI_QRS_Mode 0 "QRS_Messmodus_nicht_aktiv" 1 "QRS_Messmodus_aktiv" ;
VAL_ 1413 SI_T_Mode 0 "Transportmodus_nicht_aktiv" 1 "Transportmodus_aktiv" ;
VAL_ 1413 SI_NWDF 0 "Ueberwachung_nicht_freigegeben" 1 "Ueberwachung_freigegeben" ;
VAL_ 1413 SI_NWDF_gueltig 0 "NWDF_wird_nicht_unterstuetzt" 1 "NWDF_wird_unterstuetzt" ;
VAL_ 1413 SI_Sammelfehler 0 "kein_Sammelfehler" 1 "Sammelfehler" ;
VAL_ 1413 GW_KD_Fehler 0 "kein_KD_Fehler" 1 "KD_Fehler" ;
VAL_ 1413 SI_T_Schutz 0 "Transportschutz_nicht_aktiv" 1 "Transportschutz_aktiv" ;
VAL_ 1413 SI_BUS_01 0 "keine_Busruhe" 1 "Busruhe" ;
VAL_ 1413 SI_BUS_02 0 "keine_Busruhe" 1 "Busruhe" ;
VAL_ 1413 SI_BUS_03 0 "keine_Busruhe" 1 "Busruhe" ;
VAL_ 1413 SI_BUS_04 0 "keine_Busruhe" 1 "Busruhe" ;
VAL_ 1413 SI_BUS_05 0 "keine_Busruhe" 1 "Busruhe" ;
VAL_ 1413 SI_BUS_06 0 "keine_Busruhe" 1 "Busruhe" ;
VAL_ 1413 SI_BUS_07 0 "keine_Busruhe" 1 "Busruhe" ;
VAL_ 1413 SI_BUS_08 0 "keine_Busruhe" 1 "Busruhe" ;
VAL_ 1413 SI_BUS_09 0 "keine_Busruhe" 1 "Busruhe" ;
VAL_ 1413 SI_BUS_10 0 "keine_Busruhe" 1 "Busruhe" ;
VAL_ 1413 SI_BUS_11 0 "keine_Busruhe" 1 "Busruhe" ;
VAL_ 1413 SI_BUS_12 0 "keine_Busruhe" 1 "Busruhe" ;
VAL_ 1413 SI_BUS_13 0 "keine_Busruhe" 1 "Busruhe" ;
VAL_ 1413 SI_BUS_14 0 "keine_Busruhe" 1 "Busruhe" ;
VAL_ 1413 SI_BUS_15 0 "keine_Busruhe" 1 "Busruhe" ;
VAL_ 1413 SI_Bus_Identifikation 16 "CAN_Diagnose" 17 "CAN_Antrieb" 18 "CAN_Komfort" 19 "CAN_Infotainment" 20 "CAN_Fahrwerk" 21 "CAN_Extended" 22 "CAN_Hybrid" 23 "CAN_Lade" 24 "CAN_Kombi" 25 "CAN_Komfort_2" 48 "FlexRay_A" 49 "FlexRay_B" ;
VAL_ 997 FT_Tuer_Status 0 "Init" 1 "Tuer_geschlossen" 2 "Tuer_offen" 3 "Fehler" ;
VAL_ 997 FT_Tuer_Status_QBit 0 "Status_Tuerkontakt_sicher" 1 "Status_Tuerkontakt_unsicher" ;
VAL_ 997 FT_Lock_Taster_02 0 "nicht_betaetigt" 1 "betaetigt" ;
VAL_ 997 FT_Schluesselschalter_zu_02 0 "nicht_betaetigt" 1 "betaetigt" ;
VAL_ 997 FT_BFS_Tuer_Status 0 "Init" 1 "Tuer_geschlossen" 2 "Tuer_offen" 3 "Fehler" ;
VAL_ 997 FT_HBFS_Tuer_Status 0 "Init" 1 "Tuer geschlossen" 2 "Tuer offen" 3 "Fehler" ;
VAL_ 997 FT_HFS_Tuer_Status 0 "Init" 1 "Tuer geschlossen" 2 "Tuer offen" 3 "Fehler" ;
VAL_ 997 FT_Tuerschloss_verrieg_nicht 0 "Türschloss kann verriegelt werden" 1 "Türschloss kann nicht verriegelt werden" ;
VAL_ 997 FT_SP_Heizung_ein 0 "Aus" 1 "Ein" ;
VAL_ 997 FT_Kisi_Taster_li_02 0 "nicht_betaetigt" 1 "betaetigt" ;
VAL_ 997 FT_Kisi_Taster_re_02 0 "nicht_betaetigt" 1 "betaetigt" ;
VAL_ 997 FT_TD_Taste_Status 0 "kein_Fehler" 1 "Kurzschluss_nach_Minus" 2 "Kurzschluss_nach_Plus" 3 "Leitungsunterbrechung" ;
VAL_ 288 TSK_Status 0 "Hauptschalter_aus" 1 "Init" 2 "passiv" 3 "aktiv" 4 "Uebertreten" 5 "brake_only_Mode" 6 "reversibel_aus" 7 "irreversibel_aus" ;
VAL_ 288 TSK_v_Begrenzung_aktiv 0 "inaktiv" 1 "aktiv" ;
VAL_ 288 TSK_Standby_Anf_ESP 0 "keine_Standby_Anforderung" 1 "Standby_Anforderung" ;
VAL_ 288 TSK_Freig_WU 0 "TSK_Uebersetzungswunsch_nicht_freigegeben" 1 "TSK_Uebersetzungswunsch_freigegeben" ;
VAL_ 288 TSK_Freig_Verzoeg_Anf 0 "Verzoegerungsanforderung_nicht_freigegeben" 1 "Verzoegerungsanforderung_freigegeben" ;
VAL_ 288 TSK_Limiter_ausgewaehlt 0 "kein_Limiter_ausgewaehlt" 1 "Limiter_ausgewaehlt" ;
VAL_ 288 TSK_Wunsch_Uebersetz 0 "Init" ;
VAL_ 288 TSK_Hauptschalter_GRA_ACC 0 "Init" 1 "Aus" 2 "Ein" 3 "Fehler" ;
VAL_ 288 TSK_SRBM_Anf_ASIL 0 "keine_SRBM_Anforderung" 1 "SRBM_Anforderung_in_ASIL_QM" 2 "SRBM_Anforderung_in_ASIL_A" 3 "SRBM_Anforderung_in_ASIL_B" 4 "SRBM_Anforderung_in_ASIL_C" ;
VAL_ 288 TSK_ax_Getriebe_02 511 "Neutralwert" ;
VAL_ 288 TSK_Zwangszusch_ESP 0 "keine_ESP_ASR_Beeinflussung" 1 "ESP_ASR_Beeinflussung" ;
